VERSION "2021.24.4"

NS_ :

BS_:

BU_: VEH CH Receiver X

BA_DEF_ BO_ "GenMsgSendType" ENUM "Cyclic";
BA_DEF_ BO_ "GenMsgCycleTime" INT 0 10000;

BO_ 1317 PMF_alertLog: 8 Vector__XXX
 SG_ PMF_a011_vrefIrrational m11 : 63|1@1+ (1,0) [0|0] "" Vector__XXX
 SG_ PMF_a036_in1HzCLK m36 : 63|1@1+ (1,0) [0|0] "" Vector__XXX
 SG_ PMF_a011_currentReadingIrrationa m11 : 62|1@1+ (1,0) [0|0] "" Vector__XXX
 SG_ PMF_a036_in10HzCLK m36 : 62|1@1+ (1,0) [0|0] "" Vector__XXX
 SG_ PMF_a011_rateOfChangeIrrational m11 : 61|1@1+ (1,0) [0|0] "" Vector__XXX
 SG_ PMF_a036_in100HzCLK m36 : 61|1@1+ (1,0) [0|0] "" Vector__XXX
 SG_ PMF_a011_sampleFreeze m11 : 60|1@1+ (1,0) [0|0] "" Vector__XXX
 SG_ PMF_a036_in1kHzCLK m36 : 60|1@1+ (1,0) [0|0] "" Vector__XXX
 SG_ PMF_a095_fwdErrCounter m95 : 60|4@1+ (1,0) [0|0] "" Vector__XXX
 SG_ PMF_a011_badPhaseBsample m11 : 59|1@1+ (1,0) [0|0] "" Vector__XXX
 SG_ PMF_a036_in1kHzSWI m36 : 59|1@1+ (1,0) [0|0] "" Vector__XXX
 SG_ PMF_a011_badPhaseAsample m11 : 58|1@1+ (1,0) [0|0] "" Vector__XXX
 SG_ PMF_a036_inRxHWI m36 : 58|1@1+ (1,0) [0|0] "" Vector__XXX
 SG_ PMF_a036_inTxHWI m36 : 57|1@1+ (1,0) [0|0] "" Vector__XXX
 SG_ PMF_a036_inTxISR m36 : 56|1@1+ (1,0) [0|0] "" Vector__XXX
 SG_ PMF_a095_wwdErrCounter m95 : 56|4@1+ (1,0) [0|0] "" Vector__XXX
 SG_ PMF_a055_diElecAngleMismatchWarn m55 : 55|1@1+ (1,0) [0|0] "" Vector__XXX
 SG_ PMF_a055_diMIA m55 : 54|1@1+ (1,0) [0|0] "" Vector__XXX
 SG_ PMF_a055_claMIA m55 : 53|1@1+ (1,0) [0|0] "" Vector__XXX
 SG_ PMF_a036_ovfStackId m36 : 52|4@1+ (1,0) [0|0] "" Vector__XXX
 SG_ PMF_a055_diSpeedMismatch m55 : 52|1@1+ (1,0) [0|0] "" Vector__XXX
 SG_ PMF_a094_safetyICstate m94 : 52|3@1+ (1,0) [0|0] "" Vector__XXX
 SG_ PMF_a055_diElecAngleMismatch m55 : 51|1@1+ (1,0) [0|0] "" Vector__XXX
 SG_ PMF_a011_currentVref m11 : 50|8@1+ (0.04,0) [0|0] "" Vector__XXX
 SG_ PMF_a055_phaseOutOfSpec m55 : 50|1@1+ (1,0) [0|0] "" Vector__XXX
 SG_ PMF_a055_noCarrier m55 : 49|1@1+ (1,0) [0|0] "" Vector__XXX
 SG_ PMF_a000_alertDataW2 m0 : 48|16@1+ (1,0) [0|0] "" Vector__XXX
 SG_ PMF_a001_w2 m1 : 48|16@1+ (1,0) [0|0] "" Vector__XXX
 SG_ PMF_a002_torqueAccelWindow m2 : 48|13@1- (2,0) [0|0] "" Vector__XXX
 SG_ PMF_a004_torqueDecelWindow m4 : 48|13@1- (2,0) [0|0] "" Vector__XXX
 SG_ PMF_a008_crc_msw m8 : 48|16@1+ (1,0) [0|0] "" Vector__XXX
 SG_ PMF_a012_badValue2 m12 : 48|16@1+ (1,0) [0|0] "" Vector__XXX
 SG_ PMF_a013_errorType m13 : 48|3@1+ (1,0) [0|0] "" Vector__XXX
 SG_ PMF_a018_w2 m18 : 48|16@1+ (1,0) [0|0] "" Vector__XXX
 SG_ PMF_a027_w2 m27 : 48|16@1+ (1,0) [0|0] "" Vector__XXX
 SG_ PMF_a028_pedalPos m28 : 48|8@1+ (0.4,0) [0|0] "" Vector__XXX
 SG_ PMF_a031_stackSize m31 : 48|14@1+ (1,0) [0|0] "" Vector__XXX
 SG_ PMF_a032_w2 m32 : 48|16@1+ (1,0) [0|0] "" Vector__XXX
 SG_ PMF_a034_motorRPM m34 : 48|16@1- (1,0) [0|0] "" Vector__XXX
 SG_ PMF_a055_notReady m55 : 48|1@1+ (1,0) [0|0] "" Vector__XXX
 SG_ PMF_a056_errorType m56 : 48|3@1+ (1,0) [0|0] "" Vector__XXX
 SG_ PMF_a057_badValue2 m57 : 48|16@1+ (1,0) [0|0] "" Vector__XXX
 SG_ PMF_a062_errorType m62 : 48|4@1+ (1,0) [0|0] "" Vector__XXX
 SG_ PMF_a094_fwdErrCounter m94 : 48|4@1+ (1,0) [0|0] "" Vector__XXX
 SG_ PMF_a096_safetyICstate m96 : 48|3@1+ (1,0) [0|0] "" Vector__XXX
 SG_ PMF_a036_timeSinceIdle m36 : 46|6@1+ (0.16,0) [0|0] "" Vector__XXX
 SG_ PMF_a096_armingConditionsMet m96 : 46|1@1+ (1,0) [0|0] "" Vector__XXX
 SG_ PMF_a034_torqueType m34 : 45|2@1+ (1,0) [0|0] "" Vector__XXX
 SG_ PMF_a010_DI_autonomyHealth m10 : 44|1@1+ (1,0) [0|0] "" Vector__XXX
 SG_ PMF_a094_wwdErrCounter m94 : 44|4@1+ (1,0) [0|0] "" Vector__XXX
 SG_ PMF_a010_DI_brakeCommand m10 : 43|1@1+ (1,0) [0|0] "" Vector__XXX
 SG_ PMF_a094_spiParityErr m94 : 43|1@1+ (1,0) [0|0] "" Vector__XXX
 SG_ PMF_a095_motorRPM m95 : 43|12@1- (10,0) [0|0] "" Vector__XXX
 SG_ PMF_a010_DI_vehicleEstimates m10 : 42|1@1+ (1,0) [0|0] "" Vector__XXX
 SG_ PMF_a011_IbDelta m11 : 42|8@1- (24.0384,0) [0|0] "" Vector__XXX
 SG_ PMF_a026_xdcErrorArg1 m26 : 42|22@1- (1,0) [0|0] "" Vector__XXX
 SG_ PMF_a094_spiOverrun m94 : 42|1@1+ (1,0) [0|0] "" Vector__XXX
 SG_ PMF_a010_vdcRight m10 : 41|1@1+ (1,0) [0|0] "" Vector__XXX
 SG_ PMF_a094_tracker2UV m94 : 41|1@1+ (1,0) [0|0] "" Vector__XXX
 SG_ PMF_a010_vdcLeft m10 : 40|1@1+ (1,0) [0|0] "" Vector__XXX
 SG_ PMF_a033_DSADC_Ib m33 : 40|16@1- (0.0939,0) [0|0] "" Vector__XXX
 SG_ PMF_a036_timeSince1kHzSWI m36 : 40|6@1+ (32,0) [0|0] "" Vector__XXX
 SG_ PMF_a040_PM_locState m40 : 40|1@1+ (1,0) [0|0] "" Vector__XXX
 SG_ PMF_a055_commonGain m55 : 40|8@1+ (0.02,0) [0|0] "" Vector__XXX
 SG_ PMF_a094_tracker1UV m94 : 40|1@1+ (1,0) [0|0] "" Vector__XXX
 SG_ PMF_a095_safetyICstate m95 : 40|3@1+ (1,0) [0|0] "" Vector__XXX
 SG_ PMF_a096_fwdErrCounterMax m96 : 40|6@1+ (1,0) [0|0] "" Vector__XXX
 SG_ PMF_a010_DI_chassisControl2 m10 : 39|1@1+ (1,0) [0|0] "" Vector__XXX
 SG_ PMF_a094_voltRefUV m94 : 39|1@1+ (1,0) [0|0] "" Vector__XXX
 SG_ PMF_a010_DI_chassisControl m10 : 38|1@1+ (1,0) [0|0] "" Vector__XXX
 SG_ PMF_a094_commLdoUV m94 : 38|1@1+ (1,0) [0|0] "" Vector__XXX
 SG_ PMF_a095_biasCurrentTooHigh m95 : 38|1@1+ (1,0) [0|0] "" Vector__XXX
 SG_ PMF_a010_DI_systemStatus m10 : 37|1@1+ (1,0) [0|0] "" Vector__XXX
 SG_ PMF_a094_preRegulatorUV m94 : 37|1@1+ (1,0) [0|0] "" Vector__XXX
 SG_ PMF_a095_biasCurrentTooLow m95 : 37|1@1+ (1,0) [0|0] "" Vector__XXX
 SG_ PMF_a010_DI_speed m10 : 36|1@1+ (1,0) [0|0] "" Vector__XXX
 SG_ PMF_a094_commLdoOT m94 : 36|1@1+ (1,0) [0|0] "" Vector__XXX
 SG_ PMF_a095_bandgapComparatorOV m95 : 36|1@1+ (1,0) [0|0] "" Vector__XXX
 SG_ PMF_a010_DI_locStatus m10 : 35|1@1+ (1,0) [0|0] "" Vector__XXX
 SG_ PMF_a094_tracker2OV m94 : 35|1@1+ (1,0) [0|0] "" Vector__XXX
 SG_ PMF_a095_bandgapComparatorUV m95 : 35|1@1+ (1,0) [0|0] "" Vector__XXX
 SG_ PMF_a010_DI_slaveCommand m10 : 34|1@1+ (1,0) [0|0] "" Vector__XXX
 SG_ PMF_a031_stackUsedPrev m31 : 34|14@1+ (1,0) [0|0] "" Vector__XXX
 SG_ PMF_a036_timeSince1kHzCLK m36 : 34|6@1+ (32,0) [0|0] "" Vector__XXX
 SG_ PMF_a094_tracker1OV m94 : 34|1@1+ (1,0) [0|0] "" Vector__XXX
 SG_ PMF_a095_supplyVoltOV m95 : 34|1@1+ (1,0) [0|0] "" Vector__XXX
 SG_ PMF_a010_DI_torque m10 : 33|1@1+ (1,0) [0|0] "" Vector__XXX
 SG_ PMF_a011_Ib m11 : 33|9@1- (12.0192,0) [0|0] "" Vector__XXX
 SG_ PMF_a094_commLdoOV m94 : 33|1@1+ (1,0) [0|0] "" Vector__XXX
 SG_ PMF_a095_coreUV m95 : 33|1@1+ (1,0) [0|0] "" Vector__XXX
 SG_ PMF_a000_alertDataW1 m0 : 32|16@1+ (1,0) [0|0] "" Vector__XXX
 SG_ PMF_a001_w1 m1 : 32|16@1+ (1,0) [0|0] "" Vector__XXX
 SG_ PMF_a002_torqueAccelAverage m2 : 32|13@1- (2,0) [0|0] "" Vector__XXX
 SG_ PMF_a003_zeroPointPedal m3 : 32|8@1+ (0.4,0) [0|0] "" Vector__XXX
 SG_ PMF_a004_torqueDecelAverage m4 : 32|13@1- (2,0) [0|0] "" Vector__XXX
 SG_ PMF_a005_iDQmagnitude m5 : 32|16@1- (0.0939,0) [0|0] "" Vector__XXX
 SG_ PMF_a008_crc_lsw m8 : 32|16@1+ (1,0) [0|0] "" Vector__XXX
 SG_ PMF_a010_DI_status m10 : 32|1@1+ (1,0) [0|0] "" Vector__XXX
 SG_ PMF_a012_badValue1 m12 : 32|16@1+ (1,0) [0|0] "" Vector__XXX
 SG_ PMF_a013_canID m13 : 32|16@1+ (1,0) [0|0] "" Vector__XXX
 SG_ PMF_a018_w1 m18 : 32|16@1+ (1,0) [0|0] "" Vector__XXX
 SG_ PMF_a019_statorTslope1 m19 : 32|16@1- (0.1,0) [0|0] "" Vector__XXX
 SG_ PMF_a026_xdcErrorIdMSW m26 : 32|10@1+ (1,0) [0|0] "" Vector__XXX
 SG_ PMF_a027_w1 m27 : 32|16@1+ (1,0) [0|0] "" Vector__XXX
 SG_ PMF_a028_torqueCommandFwd m28 : 32|13@1- (2,0) [0|0] "" Vector__XXX
 SG_ PMF_a032_w1 m32 : 32|16@1+ (1,0) [0|0] "" Vector__XXX
 SG_ PMF_a034_parameterPM m34 : 32|13@1- (0.25,0) [0|0] "" Vector__XXX
 SG_ PMF_a055_phaseAngle m55 : 32|8@1+ (0.00308,0) [0|0] "" Vector__XXX
 SG_ PMF_a056_canID m56 : 32|16@1+ (1,0) [0|0] "" Vector__XXX
 SG_ PMF_a057_badValue1 m57 : 32|16@1+ (1,0) [0|0] "" Vector__XXX
 SG_ PMF_a064_pmCrsState m64 : 32|3@1+ (1,0) [0|0] "" Vector__XXX
 SG_ PMF_a094_tracker2Short m94 : 32|1@1+ (1,0) [0|0] "" Vector__XXX
 SG_ PMF_a095_standbyLdoUV m95 : 32|1@1+ (1,0) [0|0] "" Vector__XXX
 SG_ PMF_a096_fwdNumKicks m96 : 32|6@1+ (1,0) [0|0] "" Vector__XXX
 SG_ PMF_a026_immStackOvf m26 : 31|1@1+ (1,0) [0|0] "" Vector__XXX
 SG_ PMF_a094_tracker1Short m94 : 31|1@1+ (1,0) [0|0] "" Vector__XXX
 SG_ PMF_a095_ucLdoUV m95 : 31|1@1+ (1,0) [0|0] "" Vector__XXX
 SG_ PMF_a025_possibleSafetyICReset m25 : 30|1@1+ (1,0) [0|0] "" Vector__XXX
 SG_ PMF_a026_eepStackOvf m26 : 30|1@1+ (1,0) [0|0] "" Vector__XXX
 SG_ PMF_a094_voltRefShort m94 : 30|1@1+ (1,0) [0|0] "" Vector__XXX
 SG_ PMF_a095_voltRefOV m95 : 30|1@1+ (1,0) [0|0] "" Vector__XXX
 SG_ PMF_a025_ovfNmi m25 : 29|1@1+ (1,0) [0|0] "" Vector__XXX
 SG_ PMF_a026_idleStackOvf m26 : 29|1@1+ (1,0) [0|0] "" Vector__XXX
 SG_ PMF_a094_commLdoShort m94 : 29|1@1+ (1,0) [0|0] "" Vector__XXX
 SG_ PMF_a095_coreOV m95 : 29|1@1+ (1,0) [0|0] "" Vector__XXX
 SG_ PMF_a012_errorType m12 : 28|3@1+ (1,0) [0|0] "" Vector__XXX
 SG_ PMF_a025_rlNmi m25 : 28|1@1+ (1,0) [0|0] "" Vector__XXX
 SG_ PMF_a026_controlStackOvf m26 : 28|1@1+ (1,0) [0|0] "" Vector__XXX
 SG_ PMF_a036_timeSince100HzTxSWI m36 : 28|6@1+ (0.32,0) [0|0] "" Vector__XXX
 SG_ PMF_a057_errorType m57 : 28|3@1+ (1,0) [0|0] "" Vector__XXX
 SG_ PMF_a094_refVoltOverLoad m94 : 28|1@1+ (1,0) [0|0] "" Vector__XXX
 SG_ PMF_a095_standbyLdoOV m95 : 28|1@1+ (1,0) [0|0] "" Vector__XXX
 SG_ PMF_a025_sysDbgNmi m25 : 27|1@1+ (1,0) [0|0] "" Vector__XXX
 SG_ PMF_a026_systemStackOvf m26 : 27|1@1+ (1,0) [0|0] "" Vector__XXX
 SG_ PMF_a064_diCrsState m64 : 27|3@1+ (1,0) [0|0] "" Vector__XXX
 SG_ PMF_a094_commLdoOTWrn m94 : 27|1@1+ (1,0) [0|0] "" Vector__XXX
 SG_ PMF_a095_ucLdoOV m95 : 27|1@1+ (1,0) [0|0] "" Vector__XXX
 SG_ PMF_a025_pieVectErrorNmi m25 : 26|1@1+ (1,0) [0|0] "" Vector__XXX
 SG_ PMF_a026_switchingActive m26 : 26|1@1+ (1,0) [0|0] "" Vector__XXX
 SG_ PMF_a094_standbyLdoOverLoad m94 : 26|1@1+ (1,0) [0|0] "" Vector__XXX
 SG_ PMF_a095_preRegulatorOV m95 : 26|1@1+ (1,0) [0|0] "" Vector__XXX
 SG_ PMF_a011_IaDelta m11 : 25|8@1- (24.0384,0) [0|0] "" Vector__XXX
 SG_ PMF_a025_cpu2signMismatchNmi m25 : 25|1@1+ (1,0) [0|0] "" Vector__XXX
 SG_ PMF_a064_UI_stoppingMode m64 : 25|2@1+ (1,0) [0|0] "" Vector__XXX
 SG_ PMF_a094_ucLdoOTWrn m94 : 25|1@1+ (1,0) [0|0] "" Vector__XXX
 SG_ PMF_a095_coreVoltShort m95 : 25|1@1+ (1,0) [0|0] "" Vector__XXX
 SG_ PMF_a003_pedalPos m3 : 24|8@1+ (0.4,0) [0|0] "" Vector__XXX
 SG_ PMF_a025_cpu1signMismatchNmi m25 : 24|1@1+ (1,0) [0|0] "" Vector__XXX
 SG_ PMF_a033_DSADC_Ia m33 : 24|16@1- (0.0939,0) [0|0] "" Vector__XXX
 SG_ PMF_a039_messageId m39 : 24|16@1+ (1,0) [0|0] "" Vector__XXX
 SG_ PMF_a040_messageId m40 : 24|16@1+ (1,0) [0|0] "" Vector__XXX
 SG_ PMF_a061_pmIpcVersion m61 : 24|8@1+ (1,0) [0|0] "" Vector__XXX
 SG_ PMF_a064_shortDetectedByDI m64 : 24|1@1+ (1,0) [0|0] "" Vector__XXX
 SG_ PMF_a094_preRegulatorOTWrn m94 : 24|1@1+ (1,0) [0|0] "" Vector__XXX
 SG_ PMF_a095_standbyLdoShort m95 : 24|1@1+ (1,0) [0|0] "" Vector__XXX
 SG_ PMF_a096_wwdErrCounterMax m96 : 24|6@1+ (1,0) [0|0] "" Vector__XXX
 SG_ PMF_a025_flashUncErrorNmi m25 : 23|1@1+ (1,0) [0|0] "" Vector__XXX
 SG_ PMF_a094_lockUnlockErr m94 : 23|1@1+ (1,0) [0|0] "" Vector__XXX
 SG_ PMF_a095_ucLdoShort m95 : 23|1@1+ (1,0) [0|0] "" Vector__XXX
 SG_ PMF_a025_ramUncErrorNmi m25 : 22|1@1+ (1,0) [0|0] "" Vector__XXX
 SG_ PMF_a026_isrCount1kHz m26 : 22|4@1+ (1,0) [0|0] "" Vector__XXX
 SG_ PMF_a036_timeSinceRxHWI m36 : 22|6@1+ (64,0) [0|0] "" Vector__XXX
 SG_ PMF_a042_gearControl m42 : 22|1@1+ (1,0) [0|0] "" Vector__XXX
 SG_ PMF_a094_durationErr m94 : 22|1@1+ (1,0) [0|0] "" Vector__XXX
 SG_ PMF_a095_preRegulatorVoltShort m95 : 22|1@1+ (1,0) [0|0] "" Vector__XXX
 SG_ PMF_a025_clockFailNmi m25 : 21|1@1+ (1,0) [0|0] "" Vector__XXX
 SG_ PMF_a094_addrErr m94 : 21|1@1+ (1,0) [0|0] "" Vector__XXX
 SG_ PMF_a095_monitoringOT m95 : 21|1@1+ (1,0) [0|0] "" Vector__XXX
 SG_ PMF_a025_watchdog m25 : 20|1@1+ (1,0) [0|0] "" Vector__XXX
 SG_ PMF_a031_stackUsed m31 : 20|14@1+ (1,0) [0|0] "" Vector__XXX
 SG_ PMF_a033_failReason m33 : 20|3@1+ (1,0) [0|0] "" Vector__XXX
 SG_ PMF_a042_expectedPerformanceCfg m42 : 20|2@1+ (1,0) [0|0] "" Vector__XXX
 SG_ PMF_a053_sensors m53 : 20|1@1+ (1,0) [0|0] "" Vector__XXX
 SG_ PMF_a054_uiTPMSRCPSetting m54 : 20|1@1+ (1,0) [0|0] "" Vector__XXX
 SG_ PMF_a064_torqueCmdState m64 : 20|4@1+ (1,0) [0|0] "" Vector__XXX
 SG_ PMF_a094_lengthErr m94 : 20|1@1+ (1,0) [0|0] "" Vector__XXX
 SG_ PMF_a095_ucLdoOT m95 : 20|1@1+ (1,0) [0|0] "" Vector__XXX
 SG_ PMF_a017_EPBR_autonomyHealth m17 : 19|1@1+ (1,0) [0|0] "" Vector__XXX
 SG_ PMF_a025_nmiWatchdog m25 : 19|1@1+ (1,0) [0|0] "" Vector__XXX
 SG_ PMF_a053_restraintStatus m53 : 19|1@1+ (1,0) [0|0] "" Vector__XXX
 SG_ PMF_a054_uiTrackModeSettings m54 : 19|1@1+ (1,0) [0|0] "" Vector__XXX
 SG_ PMF_a094_parityErr m94 : 19|1@1+ (1,0) [0|0] "" Vector__XXX
 SG_ PMF_a095_preRegulatorOT m95 : 19|1@1+ (1,0) [0|0] "" Vector__XXX
 SG_ PMF_a002_torqueMeasured m2 : 18|13@1- (2,0) [0|0] "" Vector__XXX
 SG_ PMF_a004_torqueMeasured m4 : 18|13@1- (2,0) [0|0] "" Vector__XXX
 SG_ PMF_a005_torqueMeasured m5 : 18|13@1- (2,0) [0|0] "" Vector__XXX
 SG_ PMF_a017_EPBL_autonomyHealth m17 : 18|1@1+ (1,0) [0|0] "" Vector__XXX
 SG_ PMF_a025_hwBist m25 : 18|1@1+ (1,0) [0|0] "" Vector__XXX
 SG_ PMF_a042_GTW_drivetrainType m42 : 18|2@1+ (1,0) [0|0] "" Vector__XXX
 SG_ PMF_a053_vcleftSwitchStatus m53 : 18|1@1+ (1,0) [0|0] "" Vector__XXX
 SG_ PMF_a054_uiCruiseControl m54 : 18|1@1+ (1,0) [0|0] "" Vector__XXX
 SG_ PMF_a094_noOpFlag m94 : 18|1@1+ (1,0) [0|0] "" Vector__XXX
 SG_ PMF_a095_errMissStsFlag m95 : 18|1@1+ (1,0) [0|0] "" Vector__XXX
 SG_ PMF_a002_torqueWindow m2 : 17|1@1+ (1,0) [0|0] "" Vector__XXX
 SG_ PMF_a004_torqueWindow m4 : 17|1@1+ (1,0) [0|0] "" Vector__XXX
 SG_ PMF_a017_EPBR_status m17 : 17|1@1+ (1,0) [0|0] "" Vector__XXX
 SG_ PMF_a025_hibernate m25 : 17|1@1+ (1,0) [0|0] "" Vector__XXX
 SG_ PMF_a026_isrCount20kHz m26 : 17|5@1+ (1,0) [0|0] "" Vector__XXX
 SG_ PMF_a039_DIS_torque m39 : 17|1@1+ (1,0) [0|0] "" Vector__XXX
 SG_ PMF_a042_GTW_time m42 : 17|1@1+ (1,0) [0|0] "" Vector__XXX
 SG_ PMF_a053_coolant m53 : 17|1@1+ (1,0) [0|0] "" Vector__XXX
 SG_ PMF_a054_uiChassisControl m54 : 17|1@1+ (1,0) [0|0] "" Vector__XXX
 SG_ PMF_a094_trFailFlag m94 : 17|1@1+ (1,0) [0|0] "" Vector__XXX
 SG_ PMF_a095_fwdErrIntFlag m95 : 17|1@1+ (1,0) [0|0] "" Vector__XXX
 SG_ PMF_a000_alertDataW0 m0 : 16|16@1+ (1,0) [0|0] "" Vector__XXX
 SG_ PMF_a001_w0 m1 : 16|16@1+ (1,0) [0|0] "" Vector__XXX
 SG_ PMF_a002_torqueAverage m2 : 16|1@1+ (1,0) [0|0] "" Vector__XXX
 SG_ PMF_a003_reverseGear m3 : 16|1@1+ (1,0) [0|0] "" Vector__XXX
 SG_ PMF_a004_torqueAverage m4 : 16|1@1+ (1,0) [0|0] "" Vector__XXX
 SG_ PMF_a005_torqueReason m5 : 16|2@1+ (1,0) [0|0] "" Vector__XXX
 SG_ PMF_a008_memoryErrorTypeBits m8 : 16|16@1+ (1,0) [0|0] "" Vector__XXX
 SG_ PMF_a010_messageId m10 : 16|16@1+ (1,0) [0|0] "" Vector__XXX
 SG_ PMF_a011_Ia m11 : 16|9@1- (12.0192,0) [0|0] "" Vector__XXX
 SG_ PMF_a012_canID m12 : 16|12@1+ (1,0) [0|0] "" Vector__XXX
 SG_ PMF_a013_mailboxID m13 : 16|16@1+ (1,0) [0|0] "" Vector__XXX
 SG_ PMF_a017_EPBL_status m17 : 16|1@1+ (1,0) [0|0] "" Vector__XXX
 SG_ PMF_a018_w0 m18 : 16|16@1+ (1,0) [0|0] "" Vector__XXX
 SG_ PMF_a019_statorTemp1 m19 : 16|16@1- (0.1,0) [0|0] "" Vector__XXX
 SG_ PMF_a025_sccReset m25 : 16|1@1+ (1,0) [0|0] "" Vector__XXX
 SG_ PMF_a026_reason m26 : 16|1@1+ (1,0) [0|0] "" Vector__XXX
 SG_ PMF_a027_w0 m27 : 16|16@1+ (1,0) [0|0] "" Vector__XXX
 SG_ PMF_a028_torqueCommanded m28 : 16|13@1- (2,0) [0|0] "" Vector__XXX
 SG_ PMF_a031_taskID m31 : 16|4@1+ (1,0) [0|0] "" Vector__XXX
 SG_ PMF_a032_w0 m32 : 16|16@1+ (1,0) [0|0] "" Vector__XXX
 SG_ PMF_a033_state m33 : 16|4@1+ (1,0) [0|0] "" Vector__XXX
 SG_ PMF_a034_parameterDI m34 : 16|13@1- (0.25,0) [0|0] "" Vector__XXX
 SG_ PMF_a035_serviceDataId m35 : 16|16@1+ (1,0) [0|0] "" Vector__XXX
 SG_ PMF_a036_timeSinceTxHWI m36 : 16|6@1+ (64,0) [0|0] "" Vector__XXX
 SG_ PMF_a037_hvpFaults m37 : 16|1@1+ (1,0) [0|0] "" Vector__XXX
 SG_ PMF_a039_DIS_status m39 : 16|1@1+ (1,0) [0|0] "" Vector__XXX
 SG_ PMF_a040_PM_state m40 : 16|1@1+ (1,0) [0|0] "" Vector__XXX
 SG_ PMF_a042_GTW_carConfig m42 : 16|1@1+ (1,0) [0|0] "" Vector__XXX
 SG_ PMF_a053_LVPowerState m53 : 16|1@1+ (1,0) [0|0] "" Vector__XXX
 SG_ PMF_a054_uiPowertrainControl m54 : 16|1@1+ (1,0) [0|0] "" Vector__XXX
 SG_ PMF_a055_motorRPM m55 : 16|16@1- (1,0) [0|0] "" Vector__XXX
 SG_ PMF_a056_mailboxID m56 : 16|16@1+ (1,0) [0|0] "" Vector__XXX
 SG_ PMF_a057_canID m57 : 16|12@1+ (1,0) [0|0] "" Vector__XXX
 SG_ PMF_a061_diIpcVersion m61 : 16|8@1+ (1,0) [0|0] "" Vector__XXX
 SG_ PMF_a062_address m62 : 16|32@1+ (1,0) [0|0] "" Vector__XXX
 SG_ PMF_a064_interventionType m64 : 16|4@1+ (1,0) [0|0] "" Vector__XXX
 SG_ PMF_a092_pllClockSource m92 : 16|2@1+ (1,0) [0|0] "" Vector__XXX
 SG_ PMF_a094_cfgErrFlag m94 : 16|1@1+ (1,0) [0|0] "" Vector__XXX
 SG_ PMF_a095_wwdErrIntFlag m95 : 16|1@1+ (1,0) [0|0] "" Vector__XXX
 SG_ PMF_a096_wwdNumKicks m96 : 16|6@1+ (1,0) [0|0] "" Vector__XXX
 SG_ PMF_alertState : 15|1@1+ (1,0) [0|0] "" Vector__XXX
 SG_ PMF_alertID M : 0|7@1+ (1,0) [0|0] "" Vector__XXX

BO_ 1318 DIF_alertLog: 8 Vector__XXX
 SG_ DIF_a007_motorShort m7 : 63|1@1+ (1,0) [0|0] "" Vector__XXX
 SG_ DIF_a014_fbDeratedForRmsError m14 : 63|1@1+ (1,0) [0|0] "" Vector__XXX
 SG_ DIF_a240_secondaryStrategy3ps m240 : 63|1@1+ (1,0) [0|0] "" Vector__XXX
 SG_ DIF_a007_motorShift m7 : 62|1@1+ (1,0) [0|0] "" Vector__XXX
 SG_ DIF_a014_tcEnabled m14 : 62|1@1+ (1,0) [0|0] "" Vector__XXX
 SG_ DIF_a015_selfTestAborted m15 : 62|1@1+ (1,0) [0|0] "" Vector__XXX
 SG_ DIF_a156_incrementedGateDriveErr m156 : 62|1@1+ (1,0) [0|0] "" Vector__XXX
 SG_ DIF_a240_confNoCurrentDetected m240 : 62|1@1+ (1,0) [0|0] "" Vector__XXX
 SG_ DIF_a001_faultLine1Gpio_L m1 : 61|1@1+ (1,0) [0|0] "" Vector__XXX
 SG_ DIF_a002_faultLine1Gpio_L m2 : 61|1@1+ (1,0) [0|0] "" Vector__XXX
 SG_ DIF_a003_faultLine1Gpio_L m3 : 61|1@1+ (1,0) [0|0] "" Vector__XXX
 SG_ DIF_a038_reason m38 : 61|2@1+ (1,0) [0|0] "" Vector__XXX
 SG_ DIF_a153_reason m153 : 61|3@1+ (1,0) [0|0] "" Vector__XXX
 SG_ DIF_a001_faultLine1Gpio_H m1 : 60|1@1+ (1,0) [0|0] "" Vector__XXX
 SG_ DIF_a002_faultLine1Gpio_H m2 : 60|1@1+ (1,0) [0|0] "" Vector__XXX
 SG_ DIF_a003_faultLine1Gpio_H m3 : 60|1@1+ (1,0) [0|0] "" Vector__XXX
 SG_ DIF_a066_errorType m66 : 60|3@1+ (1,0) [0|0] "" Vector__XXX
 SG_ DIF_a123_varianceQ m123 : 60|4@1+ (20,0) [0|0] "" Vector__XXX
 SG_ DIF_a156_powerPolarityAlternate m156 : 60|2@1+ (1,0) [0|0] "" Vector__XXX
 SG_ DIF_a251_reason m251 : 60|3@1+ (1,0) [0|0] "" Vector__XXX
 SG_ DIF_a001_localReset_L m1 : 59|1@1+ (1,0) [0|0] "" Vector__XXX
 SG_ DIF_a002_localReset_L m2 : 59|1@1+ (1,0) [0|0] "" Vector__XXX
 SG_ DIF_a003_localReset_L m3 : 59|1@1+ (1,0) [0|0] "" Vector__XXX
 SG_ DIF_a001_remoteReset_L m1 : 58|1@1+ (1,0) [0|0] "" Vector__XXX
 SG_ DIF_a002_remoteReset_L m2 : 58|1@1+ (1,0) [0|0] "" Vector__XXX
 SG_ DIF_a003_remoteReset_L m3 : 58|1@1+ (1,0) [0|0] "" Vector__XXX
 SG_ DIF_a156_phaseCPolarityAlternate m156 : 58|2@1+ (1,0) [0|0] "" Vector__XXX
 SG_ DIF_a001_localCommError_L m1 : 57|1@1+ (1,0) [0|0] "" Vector__XXX
 SG_ DIF_a002_localCommError_L m2 : 57|1@1+ (1,0) [0|0] "" Vector__XXX
 SG_ DIF_a003_localCommError_L m3 : 57|1@1+ (1,0) [0|0] "" Vector__XXX
 SG_ DIF_a016_triggerEvent m16 : 57|5@1+ (1,0) [0|0] "" Vector__XXX
 SG_ DIF_a024_rotorAngle m24 : 57|7@1- (3,0) [0|0] "" Vector__XXX
 SG_ DIF_a240_secondaryDutyCycle m240 : 57|5@1+ (1,0) [0|0] "" Vector__XXX
 SG_ DIF_a001_remoteCommError_L m1 : 56|1@1+ (1,0) [0|0] "" Vector__XXX
 SG_ DIF_a002_remoteCommError_L m2 : 56|1@1+ (1,0) [0|0] "" Vector__XXX
 SG_ DIF_a003_remoteCommError_L m3 : 56|1@1+ (1,0) [0|0] "" Vector__XXX
 SG_ DIF_a011_codeBranch m11 : 56|4@1+ (1,0) [0|0] "" Vector__XXX
 SG_ DIF_a015_pyroSenseVAvg m15 : 56|6@1+ (0.1,0) [0|0] "" Vector__XXX
 SG_ DIF_a016_safetyICfaultLine m16 : 56|1@1+ (1,0) [0|0] "" Vector__XXX
 SG_ DIF_a099_cpuUsage10ms m99 : 56|8@1+ (1,0) [0|0] "" Vector__XXX
 SG_ DIF_a123_varianceD m123 : 56|4@1+ (20,0) [0|0] "" Vector__XXX
 SG_ DIF_a153_oilPumpAlert m153 : 56|5@1+ (1,0) [0|0] "" Vector__XXX
 SG_ DIF_a156_phaseBPolarityAlternate m156 : 56|2@1+ (1,0) [0|0] "" Vector__XXX
 SG_ DIF_a251_leadAngle m251 : 56|4@1+ (1.875,0) [0|0] "" Vector__XXX
 SG_ DIF_a001_localReset_H m1 : 55|1@1+ (1,0) [0|0] "" Vector__XXX
 SG_ DIF_a002_localReset_H m2 : 55|1@1+ (1,0) [0|0] "" Vector__XXX
 SG_ DIF_a003_localReset_H m3 : 55|1@1+ (1,0) [0|0] "" Vector__XXX
 SG_ DIF_a148_timeAbove104degC m148 : 55|9@1+ (5,0) [0|0] "" Vector__XXX
 SG_ DIF_a154_claMIA m154 : 55|1@1+ (1,0) [0|0] "" Vector__XXX
 SG_ DIF_a001_remoteReset_H m1 : 54|1@1+ (1,0) [0|0] "" Vector__XXX
 SG_ DIF_a002_remoteReset_H m2 : 54|1@1+ (1,0) [0|0] "" Vector__XXX
 SG_ DIF_a003_remoteReset_H m3 : 54|1@1+ (1,0) [0|0] "" Vector__XXX
 SG_ DIF_a007_iqFdbStdDeviation m7 : 54|8@1+ (4,0) [0|0] "" Vector__XXX
 SG_ DIF_a154_trackerIrrational m154 : 54|1@1+ (1,0) [0|0] "" Vector__XXX
 SG_ DIF_a156_phaseAPolarityAlternate m156 : 54|2@1+ (1,0) [0|0] "" Vector__XXX
 SG_ DIF_a001_localCommError_H m1 : 53|1@1+ (1,0) [0|0] "" Vector__XXX
 SG_ DIF_a002_localCommError_H m2 : 53|1@1+ (1,0) [0|0] "" Vector__XXX
 SG_ DIF_a003_localCommError_H m3 : 53|1@1+ (1,0) [0|0] "" Vector__XXX
 SG_ DIF_a153_state m153 : 53|3@1+ (1,0) [0|0] "" Vector__XXX
 SG_ DIF_a154_carrierOffset m154 : 53|1@1+ (1,0) [0|0] "" Vector__XXX
 SG_ DIF_a001_remoteCommError_H m1 : 52|1@1+ (1,0) [0|0] "" Vector__XXX
 SG_ DIF_a002_remoteCommError_H m2 : 52|1@1+ (1,0) [0|0] "" Vector__XXX
 SG_ DIF_a003_remoteCommError_H m3 : 52|1@1+ (1,0) [0|0] "" Vector__XXX
 SG_ DIF_a014_rmsTorqueError m14 : 52|10@1+ (1,0) [0|0] "" Vector__XXX
 SG_ DIF_a103_sensorTempEst m103 : 52|8@1- (1.2598425196850394,40.31496062992126) [0|0] "" Vector__XXX
 SG_ DIF_a134_wheelSpeedDiffReR m134 : 52|12@1- (0.0625,0) [0|0] "" Vector__XXX
 SG_ DIF_a154_errorTableInvalid m154 : 52|1@1+ (1,0) [0|0] "" Vector__XXX
 SG_ DIF_a240_primaryDutyCycle m240 : 52|5@1+ (1,0) [0|0] "" Vector__XXX
 SG_ DIF_a084_flashEccTestFail m84 : 51|1@1+ (1,0) [0|0] "" Vector__XXX
 SG_ DIF_a154_notReady m154 : 51|1@1+ (1,0) [0|0] "" Vector__XXX
 SG_ DIF_a240_secNoCurrentB m240 : 51|1@1+ (1,0) [0|0] "" Vector__XXX
 SG_ DIF_a069_fittedTorqueLimit m69 : 50|13@1- (0.25,0) [0|0] "" Vector__XXX
 SG_ DIF_a084_postAddressTestFail m84 : 50|1@1+ (1,0) [0|0] "" Vector__XXX
 SG_ DIF_a107_fpgaWarningActive m107 : 50|1@1+ (1,0) [0|0] "" Vector__XXX
 SG_ DIF_a154_noCarrier m154 : 50|1@1+ (1,0) [0|0] "" Vector__XXX
 SG_ DIF_a240_secNoCurrentA m240 : 50|1@1+ (1,0) [0|0] "" Vector__XXX
 SG_ DIF_a084_preAddressTestFail m84 : 49|1@1+ (1,0) [0|0] "" Vector__XXX
 SG_ DIF_a107_fpgaFaultActive m107 : 49|1@1+ (1,0) [0|0] "" Vector__XXX
 SG_ DIF_a149_pcbaID m149 : 49|1@1+ (1,0) [0|0] "" Vector__XXX
 SG_ DIF_a154_noPhaseLock m154 : 49|1@1+ (1,0) [0|0] "" Vector__XXX
 SG_ DIF_a240_primNoCurrentB m240 : 49|1@1+ (1,0) [0|0] "" Vector__XXX
 SG_ DIF_a000_alertDataW2 m0 : 48|16@1+ (1,0) [0|0] "" Vector__XXX
 SG_ DIF_a001_gateDriveErrCounter m1 : 48|4@1+ (1,0) [0|0] "" Vector__XXX
 SG_ DIF_a002_gateDriveErrCounter m2 : 48|4@1+ (1,0) [0|0] "" Vector__XXX
 SG_ DIF_a003_gateDriveErrCounter m3 : 48|4@1+ (1,0) [0|0] "" Vector__XXX
 SG_ DIF_a011_badDataExpected m11 : 48|8@1+ (1,0) [0|0] "" Vector__XXX
 SG_ DIF_a013_errorType m13 : 48|4@1+ (1,0) [0|0] "" Vector__XXX
 SG_ DIF_a015_pyroSenseVDiff m15 : 48|6@1+ (0.1,0) [0|0] "" Vector__XXX
 SG_ DIF_a025_motorSpeed m25 : 48|16@1- (1,0) [0|0] "" Vector__XXX
 SG_ DIF_a026_motorSpeed m26 : 48|16@1- (1,0) [0|0] "" Vector__XXX
 SG_ DIF_a027_motorSpeed m27 : 48|16@1- (1,0) [0|0] "" Vector__XXX
 SG_ DIF_a028_iArmsSpeed m28 : 48|16@1+ (1,0) [0|0] "" Vector__XXX
 SG_ DIF_a029_iBrmsSpeed m29 : 48|16@1+ (1,0) [0|0] "" Vector__XXX
 SG_ DIF_a030_iCrmsSpeed m30 : 48|16@1+ (1,0) [0|0] "" Vector__XXX
 SG_ DIF_a033_vRefIa m33 : 48|16@1- (0.001,0) [0|0] "" Vector__XXX
 SG_ DIF_a034_vRefIb m34 : 48|16@1- (0.001,0) [0|0] "" Vector__XXX
 SG_ DIF_a035_frequency m35 : 48|10@1+ (1,0) [0|0] "" Vector__XXX
 SG_ DIF_a038_iBat m38 : 48|13@1+ (0.5,0) [0|0] "" Vector__XXX
 SG_ DIF_a042_inletTempSlope m42 : 48|8@1- (0.5,0) [0|0] "" Vector__XXX
 SG_ DIF_a045_outletTempSlope m45 : 48|8@1- (0.5,0) [0|0] "" Vector__XXX
 SG_ DIF_a049_motorCurrent m49 : 48|11@1+ (1,0) [0|0] "" Vector__XXX
 SG_ DIF_a055_motorRPM m55 : 48|16@1- (1,0) [0|0] "" Vector__XXX
 SG_ DIF_a058_pcbTempSlope m58 : 48|8@1- (0.5,0) [0|0] "" Vector__XXX
 SG_ DIF_a066_canID m66 : 48|12@1+ (1,0) [0|0] "" Vector__XXX
 SG_ DIF_a074_motorSpeed2 m74 : 48|16@1- (1,0) [0|0] "" Vector__XXX
 SG_ DIF_a084_eccCheckFail m84 : 48|1@1+ (1,0) [0|0] "" Vector__XXX
 SG_ DIF_a093_errorType m93 : 48|1@1+ (1,0) [0|0] "" Vector__XXX
 SG_ DIF_a094_badValue2 m94 : 48|16@1+ (1,0) [0|0] "" Vector__XXX
 SG_ DIF_a099_cpuUsage1kHz m99 : 48|8@1+ (1,0) [0|0] "" Vector__XXX
 SG_ DIF_a107_fpgaMasterActive m107 : 48|1@1+ (1,0) [0|0] "" Vector__XXX
 SG_ DIF_a113_heatsink3Temp m113 : 48|16@1- (0.1,0) [0|0] "" Vector__XXX
 SG_ DIF_a121_badFlux m121 : 48|16@1+ (0.0001,0) [0|0] "" Vector__XXX
 SG_ DIF_a123_motorRPM m123 : 48|8@1- (150,0) [0|0] "" Vector__XXX
 SG_ DIF_a133_badValue2 m133 : 48|16@1- (0.1,0) [0|0] "" Vector__XXX
 SG_ DIF_a149_responseError m149 : 48|1@1+ (1,0) [0|0] "" Vector__XXX
 SG_ DIF_a150_energy m150 : 48|16@1+ (1,0) [0|0] "" Vector__XXX
 SG_ DIF_a153_lowPressPlausibility m153 : 48|5@1+ (3.3,0) [0|0] "" Vector__XXX
 SG_ DIF_a154_noCalibration m154 : 48|1@1+ (1,0) [0|0] "" Vector__XXX
 SG_ DIF_a160_energy m160 : 48|16@1+ (1,0) [0|0] "" Vector__XXX
 SG_ DIF_a240_primNoCurrentA m240 : 48|1@1+ (1,0) [0|0] "" Vector__XXX
 SG_ DIF_a246_eepromOffsetIb m246 : 48|6@1- (0.763,0) [0|0] "" Vector__XXX
 SG_ DIF_a247_torqueMotor m247 : 48|16@1- (1,0) [0|0] "" Vector__XXX
 SG_ DIF_a249_motorCurrent m249 : 48|11@1+ (1,0) [0|0] "" Vector__XXX
 SG_ DIF_a251_phaseCurrent m251 : 48|8@1+ (0.1,0) [0|0] "" Vector__XXX
 SG_ DIF_a001_deadtimeError_L m1 : 47|1@1+ (1,0) [0|0] "" Vector__XXX
 SG_ DIF_a002_deadtimeError_L m2 : 47|1@1+ (1,0) [0|0] "" Vector__XXX
 SG_ DIF_a003_deadtimeError_L m3 : 47|1@1+ (1,0) [0|0] "" Vector__XXX
 SG_ DIF_a149_motorFlowSNA m149 : 47|1@1+ (1,0) [0|0] "" Vector__XXX
 SG_ DIF_a240_secondaryTimeout m240 : 47|1@1+ (1,0) [0|0] "" Vector__XXX
 SG_ DIF_a001_spiError_L m1 : 46|1@1+ (1,0) [0|0] "" Vector__XXX
 SG_ DIF_a002_spiError_L m2 : 46|1@1+ (1,0) [0|0] "" Vector__XXX
 SG_ DIF_a003_spiError_L m3 : 46|1@1+ (1,0) [0|0] "" Vector__XXX
 SG_ DIF_a007_idFdbStdDeviation m7 : 46|8@1+ (4,0) [0|0] "" Vector__XXX
 SG_ DIF_a148_timeFrom90to104degC m148 : 46|9@1+ (30,0) [0|0] "" Vector__XXX
 SG_ DIF_a149_motorShorted m149 : 46|1@1+ (1,0) [0|0] "" Vector__XXX
 SG_ DIF_a240_primaryTimeout m240 : 46|1@1+ (1,0) [0|0] "" Vector__XXX
 SG_ DIF_a001_localRegError_L m1 : 45|1@1+ (1,0) [0|0] "" Vector__XXX
 SG_ DIF_a002_localRegError_L m2 : 45|1@1+ (1,0) [0|0] "" Vector__XXX
 SG_ DIF_a003_localRegError_L m3 : 45|1@1+ (1,0) [0|0] "" Vector__XXX
 SG_ DIF_a024_maxCurrMagSqrd m24 : 45|12@1+ (500,0) [0|0] "" Vector__XXX
 SG_ DIF_a055_torqueType m55 : 45|2@1+ (1,0) [0|0] "" Vector__XXX
 SG_ DIF_a103_ambientTemp m103 : 45|7@1- (1.5873015873015872,11.11111111111111) [0|0] "" Vector__XXX
 SG_ DIF_a149_motorOpenPhase m149 : 45|1@1+ (1,0) [0|0] "" Vector__XXX
 SG_ DIF_a001_overvoltVDD_L m1 : 44|1@1+ (1,0) [0|0] "" Vector__XXX
 SG_ DIF_a002_overvoltVDD_L m2 : 44|1@1+ (1,0) [0|0] "" Vector__XXX
 SG_ DIF_a003_overvoltVDD_L m3 : 44|1@1+ (1,0) [0|0] "" Vector__XXX
 SG_ DIF_a147_wearIsValid m147 : 44|1@1+ (1,0) [0|0] "" Vector__XXX
 SG_ DIF_a149_insufficientFlow m149 : 44|1@1+ (1,0) [0|0] "" Vector__XXX
 SG_ DIF_a001_undervoltVDD_L m1 : 43|1@1+ (1,0) [0|0] "" Vector__XXX
 SG_ DIF_a002_undervoltVDD_L m2 : 43|1@1+ (1,0) [0|0] "" Vector__XXX
 SG_ DIF_a003_undervoltVDD_L m3 : 43|1@1+ (1,0) [0|0] "" Vector__XXX
 SG_ DIF_a149_fluidTempSNA m149 : 43|1@1+ (1,0) [0|0] "" Vector__XXX
 SG_ DIF_a001_remoteRegError_L m1 : 42|1@1+ (1,0) [0|0] "" Vector__XXX
 SG_ DIF_a002_remoteRegError_L m2 : 42|1@1+ (1,0) [0|0] "" Vector__XXX
 SG_ DIF_a003_remoteRegError_L m3 : 42|1@1+ (1,0) [0|0] "" Vector__XXX
 SG_ DIF_a014_brakeMasterCylPress m14 : 42|10@1+ (0.25,-42.5) [0|0] "" Vector__XXX
 SG_ DIF_a162_currentOdometer m162 : 42|10@1+ (500,0) [0|0] "" Vector__XXX
 SG_ DIF_a001_asynchStop_L m1 : 41|1@1+ (1,0) [0|0] "" Vector__XXX
 SG_ DIF_a002_asynchStop_L m2 : 41|1@1+ (1,0) [0|0] "" Vector__XXX
 SG_ DIF_a003_asynchStop_L m3 : 41|1@1+ (1,0) [0|0] "" Vector__XXX
 SG_ DIF_a001_undervoltVCC_L m1 : 40|1@1+ (1,0) [0|0] "" Vector__XXX
 SG_ DIF_a002_undervoltVCC_L m2 : 40|1@1+ (1,0) [0|0] "" Vector__XXX
 SG_ DIF_a003_undervoltVCC_L m3 : 40|1@1+ (1,0) [0|0] "" Vector__XXX
 SG_ DIF_a011_badDataRead m11 : 40|8@1+ (1,0) [0|0] "" Vector__XXX
 SG_ DIF_a015_pyroSenseVN m15 : 40|6@1+ (0.1,0) [0|0] "" Vector__XXX
 SG_ DIF_a016_torqueMotor m16 : 40|16@1- (1,0) [0|0] "" Vector__XXX
 SG_ DIF_a061_otherTemp m61 : 40|16@1- (0.1,0) [0|0] "" Vector__XXX
 SG_ DIF_a065_mailboxID m65 : 40|16@1+ (1,0) [0|0] "" Vector__XXX
 SG_ DIF_a069_rotorMagnetTemp m69 : 40|10@1+ (0.25,-60) [0|0] "" Vector__XXX
 SG_ DIF_a096_word2 m96 : 40|16@1+ (1,0) [0|0] "" Vector__XXX
 SG_ DIF_a097_argument m97 : 40|16@1+ (1,0) [0|0] "" Vector__XXX
 SG_ DIF_a099_cpuUsage100Hz m99 : 40|8@1+ (1,0) [0|0] "" Vector__XXX
 SG_ DIF_a122_stackSize m122 : 40|16@1+ (1,0) [0|0] "" Vector__XXX
 SG_ DIF_a134_wheelSpeedDiffReL m134 : 40|12@1- (0.0625,0) [0|0] "" Vector__XXX
 SG_ DIF_a149_state m149 : 40|3@1+ (1,0) [0|0] "" Vector__XXX
 SG_ DIF_a150_elapsedMs m150 : 40|8@1+ (1,0) [0|0] "" Vector__XXX
 SG_ DIF_a152_expectedValue m152 : 40|8@1+ (1,0) [0|0] "" Vector__XXX
 SG_ DIF_a153_dcVoltage m153 : 40|8@1+ (0.3,0) [0|0] "" Vector__XXX
 SG_ DIF_a154_commonGain m154 : 40|8@1+ (0.02,0) [0|0] "" Vector__XXX
 SG_ DIF_a160_elapsedMs m160 : 40|8@1+ (1,0) [0|0] "" Vector__XXX
 SG_ DIF_a240_fuseB_I2t m240 : 40|6@1+ (8,0) [0|0] "" Vector__XXX
 SG_ DIF_a246_eepromOffsetIa m246 : 40|6@1- (0.763,0) [0|0] "" Vector__XXX
 SG_ DIF_a249_statorT m249 : 40|8@1+ (1,-40) [0|0] "" Vector__XXX
 SG_ DIF_a251_dcCurrent m251 : 40|8@1+ (0.1,0) [0|0] "" Vector__XXX
 SG_ DIF_a254_reason m254 : 40|2@1+ (1,0) [0|0] "" Vector__XXX
 SG_ DIF_a001_overvoltVH_L m1 : 39|1@1+ (1,0) [0|0] "" Vector__XXX
 SG_ DIF_a002_overvoltVH_L m2 : 39|1@1+ (1,0) [0|0] "" Vector__XXX
 SG_ DIF_a003_overvoltVH_L m3 : 39|1@1+ (1,0) [0|0] "" Vector__XXX
 SG_ DIF_a123_badCurrent m123 : 39|9@1- (10,0) [0|0] "" Vector__XXX
 SG_ DIF_a001_overvoltVL_L m1 : 38|1@1+ (1,0) [0|0] "" Vector__XXX
 SG_ DIF_a002_overvoltVL_L m2 : 38|1@1+ (1,0) [0|0] "" Vector__XXX
 SG_ DIF_a003_overvoltVL_L m3 : 38|1@1+ (1,0) [0|0] "" Vector__XXX
 SG_ DIF_a024_Ib m24 : 38|7@1- (22.5,0) [0|0] "" Vector__XXX
 SG_ DIF_a156_motorRPM m156 : 38|16@1- (1,0) [0|0] "" Vector__XXX
 SG_ DIF_a001_desat_L m1 : 37|1@1+ (1,0) [0|0] "" Vector__XXX
 SG_ DIF_a002_desat_L m2 : 37|1@1+ (1,0) [0|0] "" Vector__XXX
 SG_ DIF_a003_desat_L m3 : 37|1@1+ (1,0) [0|0] "" Vector__XXX
 SG_ DIF_a148_timeFrom50to90degC m148 : 37|9@1+ (30,0) [0|0] "" Vector__XXX
 SG_ DIF_a156_alertQueueOverrun m156 : 37|1@1+ (1,0) [0|0] "" Vector__XXX
 SG_ DIF_a001_sense_L m1 : 36|1@1+ (1,0) [0|0] "" Vector__XXX
 SG_ DIF_a002_sense_L m2 : 36|1@1+ (1,0) [0|0] "" Vector__XXX
 SG_ DIF_a003_sense_L m3 : 36|1@1+ (1,0) [0|0] "" Vector__XXX
 SG_ DIF_a042_heatsinkTemp m42 : 36|10@1+ (0.25,-60) [0|0] "" Vector__XXX
 SG_ DIF_a045_heatsinkTemp m45 : 36|10@1+ (0.25,-60) [0|0] "" Vector__XXX
 SG_ DIF_a058_heatsinkTemp m58 : 36|10@1+ (0.25,-60) [0|0] "" Vector__XXX
 SG_ DIF_a144_autonomyFeatureType m144 : 36|1@1+ (1,0) [0|0] "" Vector__XXX
 SG_ DIF_a001_undervoltVH_L m1 : 35|1@1+ (1,0) [0|0] "" Vector__XXX
 SG_ DIF_a002_undervoltVH_L m2 : 35|1@1+ (1,0) [0|0] "" Vector__XXX
 SG_ DIF_a003_undervoltVH_L m3 : 35|1@1+ (1,0) [0|0] "" Vector__XXX
 SG_ DIF_a103_rmsCurrent m103 : 35|10@1- (12.819960861056751,0) [0|0] "" Vector__XXX
 SG_ DIF_a144_chassisSubType m144 : 35|1@1+ (1,0) [0|0] "" Vector__XXX
 SG_ DIF_a156_safeStateRecommend m156 : 35|2@1+ (1,0) [0|0] "" Vector__XXX
 SG_ DIF_a001_undervoltVL_L m1 : 34|1@1+ (1,0) [0|0] "" Vector__XXX
 SG_ DIF_a002_undervoltVL_L m2 : 34|1@1+ (1,0) [0|0] "" Vector__XXX
 SG_ DIF_a003_undervoltVL_L m3 : 34|1@1+ (1,0) [0|0] "" Vector__XXX
 SG_ DIF_a144_powerLiftgateType m144 : 34|1@1+ (1,0) [0|0] "" Vector__XXX
 SG_ DIF_a147_accumulatedWear m147 : 34|10@1+ (0.005,0) [0|0] "" Vector__XXX
 SG_ DIF_a240_fuseA_I2t m240 : 34|6@1+ (8,0) [0|0] "" Vector__XXX
 SG_ DIF_a001_thermalShutdown_L m1 : 33|1@1+ (1,0) [0|0] "" Vector__XXX
 SG_ DIF_a002_thermalShutdown_L m2 : 33|1@1+ (1,0) [0|0] "" Vector__XXX
 SG_ DIF_a003_thermalShutdown_L m3 : 33|1@1+ (1,0) [0|0] "" Vector__XXX
 SG_ DIF_a136_busyError_AH m136 : 33|1@1+ (1,0) [0|0] "" Vector__XXX
 SG_ DIF_a144_dasHw m144 : 33|1@1+ (1,0) [0|0] "" Vector__XXX
 SG_ DIF_a156_result m156 : 33|2@1+ (1,0) [0|0] "" Vector__XXX
 SG_ DIF_a000_alertDataW1 m0 : 32|16@1+ (1,0) [0|0] "" Vector__XXX
 SG_ DIF_a001_thermalWarning_L m1 : 32|1@1+ (1,0) [0|0] "" Vector__XXX
 SG_ DIF_a002_thermalWarning_L m2 : 32|1@1+ (1,0) [0|0] "" Vector__XXX
 SG_ DIF_a003_thermalWarning_L m3 : 32|1@1+ (1,0) [0|0] "" Vector__XXX
 SG_ DIF_a007_offsetError m7 : 32|14@1- (0.00038349519697141,0) [0|0] "" Vector__XXX
 SG_ DIF_a010_wdtFlags m10 : 32|16@1+ (1,0) [0|0] "" Vector__XXX
 SG_ DIF_a011_badGateDriveIC m11 : 32|3@1+ (1,0) [0|0] "" Vector__XXX
 SG_ DIF_a014_torqueCommandFwd m14 : 32|10@1- (2,0) [0|0] "" Vector__XXX
 SG_ DIF_a015_pyroSenseV m15 : 32|6@1+ (0.1,0) [0|0] "" Vector__XXX
 SG_ DIF_a025_torqueMotor m25 : 32|13@1- (0.25,0) [0|0] "" Vector__XXX
 SG_ DIF_a026_torqueMotor m26 : 32|13@1- (0.25,0) [0|0] "" Vector__XXX
 SG_ DIF_a027_torqueMotor m27 : 32|13@1- (0.25,0) [0|0] "" Vector__XXX
 SG_ DIF_a028_iArmsTorque m28 : 32|16@1+ (0.25,0) [0|0] "" Vector__XXX
 SG_ DIF_a029_iBrmsTorque m29 : 32|16@1+ (0.25,0) [0|0] "" Vector__XXX
 SG_ DIF_a030_iCrmsTorque m30 : 32|16@1+ (0.25,0) [0|0] "" Vector__XXX
 SG_ DIF_a033_deltaIa m33 : 32|16@1- (1,0) [0|0] "" Vector__XXX
 SG_ DIF_a034_deltaIb m34 : 32|16@1- (1,0) [0|0] "" Vector__XXX
 SG_ DIF_a035_phaseCurrent m35 : 32|16@1+ (1,0) [0|0] "" Vector__XXX
 SG_ DIF_a036_busHighLimit m36 : 32|16@1+ (0.1,0) [0|0] "" Vector__XXX
 SG_ DIF_a037_busLowLimit m37 : 32|16@1+ (0.1,0) [0|0] "" Vector__XXX
 SG_ DIF_a038_vBat m38 : 32|13@1+ (0.2,0) [0|0] "" Vector__XXX
 SG_ DIF_a046_statorTemp2 m46 : 32|16@1- (0.1,0) [0|0] "" Vector__XXX
 SG_ DIF_a047_statorTslope1 m47 : 32|16@1- (0.1,0) [0|0] "" Vector__XXX
 SG_ DIF_a048_statorTslope2 m48 : 32|16@1- (0.1,0) [0|0] "" Vector__XXX
 SG_ DIF_a049_motorRPM m49 : 32|16@1+ (1,0) [0|0] "" Vector__XXX
 SG_ DIF_a050_statorTemp2 m50 : 32|16@1- (0.1,0) [0|0] "" Vector__XXX
 SG_ DIF_a054_heatsinkTemp m54 : 32|16@1- (0.1,0) [0|0] "" Vector__XXX
 SG_ DIF_a055_parameterPM m55 : 32|13@1- (0.25,0) [0|0] "" Vector__XXX
 SG_ DIF_a065_errorType m65 : 32|1@1+ (1,0) [0|0] "" Vector__XXX
 SG_ DIF_a066_badValue2 m66 : 32|16@1+ (1,0) [0|0] "" Vector__XXX
 SG_ DIF_a067_mailboxID m67 : 32|16@1+ (1,0) [0|0] "" Vector__XXX
 SG_ DIF_a069_rotorCoolingPower m69 : 32|8@1+ (20,0) [0|0] "" Vector__XXX
 SG_ DIF_a071_busVslope m71 : 32|16@1+ (0.1,0) [0|0] "" Vector__XXX
 SG_ DIF_a074_motorSpeed1 m74 : 32|16@1- (1,0) [0|0] "" Vector__XXX
 SG_ DIF_a075_absSpeed m75 : 32|16@1+ (1,0) [0|0] "" Vector__XXX
 SG_ DIF_a093_canID m93 : 32|16@1+ (1,0) [0|0] "" Vector__XXX
 SG_ DIF_a094_badValue1 m94 : 32|16@1+ (1,0) [0|0] "" Vector__XXX
 SG_ DIF_a095_canID m95 : 32|16@1+ (1,0) [0|0] "" Vector__XXX
 SG_ DIF_a098_fluxState m98 : 32|4@1+ (1,0) [0|0] "" Vector__XXX
 SG_ DIF_a099_cpuUsage10Hz m99 : 32|8@1+ (1,0) [0|0] "" Vector__XXX
 SG_ DIF_a107_fpgaBootVersion m107 : 32|16@1+ (1,0) [0|0] "" Vector__XXX
 SG_ DIF_a108_blockingAlert m108 : 32|8@1+ (1,0) [0|0] "" Vector__XXX
 SG_ DIF_a111_phBcalib m111 : 32|16@1+ (1,0) [0|0] "" Vector__XXX
 SG_ DIF_a113_heatsink2Temp m113 : 32|16@1- (0.1,0) [0|0] "" Vector__XXX
 SG_ DIF_a121_badCurrent m121 : 32|16@1- (0.1,0) [0|0] "" Vector__XXX
 SG_ DIF_a123_lossRequest m123 : 32|7@1+ (0.1,0) [0|0] "" Vector__XXX
 SG_ DIF_a128_reportedFPGAversion m128 : 32|16@1+ (1,0) [0|0] "" Vector__XXX
 SG_ DIF_a133_badValue1 m133 : 32|16@1- (0.1,0) [0|0] "" Vector__XXX
 SG_ DIF_a136_crcError_AH m136 : 32|1@1+ (1,0) [0|0] "" Vector__XXX
 SG_ DIF_a142_lashCheckCount m142 : 32|15@1+ (1,0) [0|0] "" Vector__XXX
 SG_ DIF_a144_brakeActuationType m144 : 32|1@1+ (1,0) [0|0] "" Vector__XXX
 SG_ DIF_a149_temperature m149 : 32|8@1+ (1,-40) [0|0] "" Vector__XXX
 SG_ DIF_a150_vBatFilteredRate m150 : 32|8@1- (100,0) [0|0] "" Vector__XXX
 SG_ DIF_a151_torqueDriver m151 : 32|16@1- (0.25,0) [0|0] "" Vector__XXX
 SG_ DIF_a152_badValue m152 : 32|8@1+ (1,0) [0|0] "" Vector__XXX
 SG_ DIF_a153_phaseCurrent m153 : 32|8@1+ (0.1,0) [0|0] "" Vector__XXX
 SG_ DIF_a154_phaseError m154 : 32|8@1- (0.004,0) [0|0] "" Vector__XXX
 SG_ DIF_a156_ucrPlausible m156 : 32|1@1+ (1,0) [0|0] "" Vector__XXX
 SG_ DIF_a160_vBatFilteredRate m160 : 32|8@1- (100,0) [0|0] "" Vector__XXX
 SG_ DIF_a162_initialVehicleOdometer m162 : 32|10@1+ (400,0) [0|0] "" Vector__XXX
 SG_ DIF_a172_statorTemp2 m172 : 32|16@1- (0.1,0) [0|0] "" Vector__XXX
 SG_ DIF_a177_correctedValue m177 : 32|16@1+ (0.0001,0) [0|0] "" Vector__XXX
 SG_ DIF_a202_sysStateExitCondition m202 : 32|5@1+ (1,0) [0|0] "" Vector__XXX
 SG_ DIF_a244_delay m244 : 32|16@1+ (1,0) [0|0] "" Vector__XXX
 SG_ DIF_a246_motorRPM m246 : 32|8@1- (150,0) [0|0] "" Vector__XXX
 SG_ DIF_a247_motorRPM m247 : 32|16@1- (1,0) [0|0] "" Vector__XXX
 SG_ DIF_a249_statorTempFromResist m249 : 32|8@1+ (1,-40) [0|0] "" Vector__XXX
 SG_ DIF_a251_dcVoltage m251 : 32|8@1+ (0.3,0) [0|0] "" Vector__XXX
 SG_ DIF_a001_deadtimeError_H m1 : 31|1@1+ (1,0) [0|0] "" Vector__XXX
 SG_ DIF_a002_deadtimeError_H m2 : 31|1@1+ (1,0) [0|0] "" Vector__XXX
 SG_ DIF_a003_deadtimeError_H m3 : 31|1@1+ (1,0) [0|0] "" Vector__XXX
 SG_ DIF_a024_Ia m24 : 31|7@1- (22.5,0) [0|0] "" Vector__XXX
 SG_ DIF_a136_spiError_AH m136 : 31|1@1+ (1,0) [0|0] "" Vector__XXX
 SG_ DIF_a144_softPerformanceLimit m144 : 31|1@1+ (1,0) [0|0] "" Vector__XXX
 SG_ DIF_a156_highMotorSpeed m156 : 31|1@1+ (1,0) [0|0] "" Vector__XXX
 SG_ DIF_a244_plausibleSingleSwitchSh m244 : 31|1@1+ (1,0) [0|0] "" Vector__XXX
 SG_ DIF_a001_spiError_H m1 : 30|1@1+ (1,0) [0|0] "" Vector__XXX
 SG_ DIF_a002_spiError_H m2 : 30|1@1+ (1,0) [0|0] "" Vector__XXX
 SG_ DIF_a003_spiError_H m3 : 30|1@1+ (1,0) [0|0] "" Vector__XXX
 SG_ DIF_a014_adState m14 : 30|2@1+ (1,0) [0|0] "" Vector__XXX
 SG_ DIF_a015_pyroSenseIrrational m15 : 30|1@1+ (1,0) [0|0] "" Vector__XXX
 SG_ DIF_a117_odometerStatus m117 : 30|1@1+ (1,0) [0|0] "" Vector__XXX
 SG_ DIF_a136_busyError_AL m136 : 30|1@1+ (1,0) [0|0] "" Vector__XXX
 SG_ DIF_a144_heatsinkType m144 : 30|1@1+ (1,0) [0|0] "" Vector__XXX
 SG_ DIF_a156_highCurrentMagnitude m156 : 30|1@1+ (1,0) [0|0] "" Vector__XXX
 SG_ DIF_a244_gateDriveICUndervoltage m244 : 30|1@1+ (1,0) [0|0] "" Vector__XXX
 SG_ DIF_a253_reason m253 : 30|2@1+ (1,0) [0|0] "" Vector__XXX
 SG_ DIF_a254_vBat m254 : 30|10@1+ (2,0) [0|0] "" Vector__XXX
 SG_ DIF_a001_localRegError_H m1 : 29|1@1+ (1,0) [0|0] "" Vector__XXX
 SG_ DIF_a002_localRegError_H m2 : 29|1@1+ (1,0) [0|0] "" Vector__XXX
 SG_ DIF_a003_localRegError_H m3 : 29|1@1+ (1,0) [0|0] "" Vector__XXX
 SG_ DIF_a010_ovfNmi m10 : 29|1@1+ (1,0) [0|0] "" Vector__XXX
 SG_ DIF_a136_crcError_AL m136 : 29|1@1+ (1,0) [0|0] "" Vector__XXX
 SG_ DIF_a144_oilPump2HwType m144 : 29|1@1+ (1,0) [0|0] "" Vector__XXX
 SG_ DIF_a229_reason m229 : 29|1@1+ (1,0) [0|0] "" Vector__XXX
 SG_ DIF_a001_overvoltVDD_H m1 : 28|1@1+ (1,0) [0|0] "" Vector__XXX
 SG_ DIF_a002_overvoltVDD_H m2 : 28|1@1+ (1,0) [0|0] "" Vector__XXX
 SG_ DIF_a003_overvoltVDD_H m3 : 28|1@1+ (1,0) [0|0] "" Vector__XXX
 SG_ DIF_a010_rlNmi m10 : 28|1@1+ (1,0) [0|0] "" Vector__XXX
 SG_ DIF_a094_errorType m94 : 28|3@1+ (1,0) [0|0] "" Vector__XXX
 SG_ DIF_a134_wheelSpeedDiffFrR m134 : 28|12@1- (0.0625,0) [0|0] "" Vector__XXX
 SG_ DIF_a136_spiError_AL m136 : 28|1@1+ (1,0) [0|0] "" Vector__XXX
 SG_ DIF_a144_oilPump1HwType m144 : 28|1@1+ (1,0) [0|0] "" Vector__XXX
 SG_ DIF_a148_timeBelow50degC m148 : 28|9@1+ (30,0) [0|0] "" Vector__XXX
 SG_ DIF_a156_powerPolarity m156 : 28|2@1+ (1,0) [0|0] "" Vector__XXX
 SG_ DIF_a240_secondaryPattern m240 : 28|6@1+ (1,0) [0|0] "" Vector__XXX
 SG_ DIF_a250_reason m250 : 28|2@1+ (1,0) [0|0] "" Vector__XXX
 SG_ DIF_a001_undervoltVDD_H m1 : 27|1@1+ (1,0) [0|0] "" Vector__XXX
 SG_ DIF_a002_undervoltVDD_H m2 : 27|1@1+ (1,0) [0|0] "" Vector__XXX
 SG_ DIF_a003_undervoltVDD_H m3 : 27|1@1+ (1,0) [0|0] "" Vector__XXX
 SG_ DIF_a010_sysDbgNmi m10 : 27|1@1+ (1,0) [0|0] "" Vector__XXX
 SG_ DIF_a024_state m24 : 27|4@1+ (1,0) [0|0] "" Vector__XXX
 SG_ DIF_a103_inverterTemp m103 : 27|8@1- (2.0078740157480315,68.26771653543307) [0|0] "" Vector__XXX
 SG_ DIF_a136_busyError_CH m136 : 27|1@1+ (1,0) [0|0] "" Vector__XXX
 SG_ DIF_a144_platformMaxBusVoltage m144 : 27|1@1+ (1,0) [0|0] "" Vector__XXX
 SG_ DIF_a155_liftgateStatus m155 : 27|1@1+ (1,0) [0|0] "" Vector__XXX
 SG_ DIF_a001_remoteRegError_H m1 : 26|1@1+ (1,0) [0|0] "" Vector__XXX
 SG_ DIF_a002_remoteRegError_H m2 : 26|1@1+ (1,0) [0|0] "" Vector__XXX
 SG_ DIF_a003_remoteRegError_H m3 : 26|1@1+ (1,0) [0|0] "" Vector__XXX
 SG_ DIF_a010_pieVectErrorNmi m10 : 26|1@1+ (1,0) [0|0] "" Vector__XXX
 SG_ DIF_a042_outletTemp m42 : 26|10@1+ (0.25,-60) [0|0] "" Vector__XXX
 SG_ DIF_a045_outletTemp m45 : 26|10@1+ (0.25,-60) [0|0] "" Vector__XXX
 SG_ DIF_a058_outletTemp m58 : 26|10@1+ (0.25,-60) [0|0] "" Vector__XXX
 SG_ DIF_a074_speed2Type m74 : 26|2@1+ (1,0) [0|0] "" Vector__XXX
 SG_ DIF_a092_bmsSystemStatus m92 : 26|1@1+ (1,0) [0|0] "" Vector__XXX
 SG_ DIF_a103_fluidImplausible m103 : 26|1@1+ (1,0) [0|0] "" Vector__XXX
 SG_ DIF_a136_crcError_CH m136 : 26|1@1+ (1,0) [0|0] "" Vector__XXX
 SG_ DIF_a144_frunkLatchType m144 : 26|1@1+ (1,0) [0|0] "" Vector__XXX
 SG_ DIF_a156_phaseCPolarity m156 : 26|2@1+ (1,0) [0|0] "" Vector__XXX
 SG_ DIF_a001_asynchStop_H m1 : 25|1@1+ (1,0) [0|0] "" Vector__XXX
 SG_ DIF_a002_asynchStop_H m2 : 25|1@1+ (1,0) [0|0] "" Vector__XXX
 SG_ DIF_a003_asynchStop_H m3 : 25|1@1+ (1,0) [0|0] "" Vector__XXX
 SG_ DIF_a010_cpu2signMismatchNmi m10 : 25|1@1+ (1,0) [0|0] "" Vector__XXX
 SG_ DIF_a011_regAddress m11 : 25|5@1+ (1,0) [0|0] "" Vector__XXX
 SG_ DIF_a035_phaseDifference m35 : 25|7@1+ (1,0) [0|0] "" Vector__XXX
 SG_ DIF_a088_uiDriveSystemsDebug m88 : 25|1@1+ (1,0) [0|0] "" Vector__XXX
 SG_ DIF_a092_bmsPackConfig m92 : 25|1@1+ (1,0) [0|0] "" Vector__XXX
 SG_ DIF_a103_lowFlowDetected m103 : 25|1@1+ (1,0) [0|0] "" Vector__XXX
 SG_ DIF_a123_badFlux m123 : 25|7@1+ (0.0015,0) [0|0] "" Vector__XXX
 SG_ DIF_a136_spiError_CH m136 : 25|1@1+ (1,0) [0|0] "" Vector__XXX
 SG_ DIF_a144_cabinPTCHeaterType m144 : 25|1@1+ (1,0) [0|0] "" Vector__XXX
 SG_ DIF_a155_systemStatus m155 : 25|1@1+ (1,0) [0|0] "" Vector__XXX
 SG_ DIF_a246_codeBranch m246 : 25|2@1+ (1,0) [0|0] "" Vector__XXX
 SG_ DIF_a001_undervoltVCC_H m1 : 24|1@1+ (1,0) [0|0] "" Vector__XXX
 SG_ DIF_a002_undervoltVCC_H m2 : 24|1@1+ (1,0) [0|0] "" Vector__XXX
 SG_ DIF_a003_undervoltVCC_H m3 : 24|1@1+ (1,0) [0|0] "" Vector__XXX
 SG_ DIF_a007_phaseBcurrent m7 : 24|8@1+ (8,0) [0|0] "" Vector__XXX
 SG_ DIF_a010_cpu1signMismatchNmi m10 : 24|1@1+ (1,0) [0|0] "" Vector__XXX
 SG_ DIF_a011_phaseCLow m11 : 24|1@1+ (1,0) [0|0] "" Vector__XXX
 SG_ DIF_a015_lightSenseV m15 : 24|6@1+ (0.1,0) [0|0] "" Vector__XXX
 SG_ DIF_a016_motorRPM m16 : 24|16@1- (1,0) [0|0] "" Vector__XXX
 SG_ DIF_a024_failReason m24 : 24|3@1+ (1,0) [0|0] "" Vector__XXX
 SG_ DIF_a035_noDriveCurrent m35 : 24|1@1+ (1,0) [0|0] "" Vector__XXX
 SG_ DIF_a041_sdcUartRxVersion m41 : 24|4@1+ (1,0) [0|0] "" Vector__XXX
 SG_ DIF_a049_statorTemp2 m49 : 24|8@1- (1,80) [0|0] "" Vector__XXX
 SG_ DIF_a061_phTemp m61 : 24|16@1- (0.1,0) [0|0] "" Vector__XXX
 SG_ DIF_a074_speed1Type m74 : 24|2@1+ (1,0) [0|0] "" Vector__XXX
 SG_ DIF_a078_adcRefLowAvg m78 : 24|16@1+ (1,0) [0|0] "" Vector__XXX
 SG_ DIF_a079_adcRefHighAvg m79 : 24|16@1+ (1,0) [0|0] "" Vector__XXX
 SG_ DIF_a088_semiControls m88 : 24|1@1+ (1,0) [0|0] "" Vector__XXX
 SG_ DIF_a092_bmsVoltageRegGain m92 : 24|1@1+ (1,0) [0|0] "" Vector__XXX
 SG_ DIF_a096_word1 m96 : 24|16@1+ (1,0) [0|0] "" Vector__XXX
 SG_ DIF_a097_lineNumber m97 : 24|16@1+ (1,0) [0|0] "" Vector__XXX
 SG_ DIF_a099_cpuUsage1Hz m99 : 24|8@1+ (1,0) [0|0] "" Vector__XXX
 SG_ DIF_a103_noFlowDetected m103 : 24|1@1+ (1,0) [0|0] "" Vector__XXX
 SG_ DIF_a108_toState m108 : 24|8@1+ (1,0) [0|0] "" Vector__XXX
 SG_ DIF_a117_vehicle m117 : 24|1@1+ (1,0) [0|0] "" Vector__XXX
 SG_ DIF_a122_stackUsed m122 : 24|16@1+ (1,0) [0|0] "" Vector__XXX
 SG_ DIF_a127_temp m127 : 24|16@1- (0.1,0) [0|0] "" Vector__XXX
 SG_ DIF_a136_busyError_CL m136 : 24|1@1+ (1,0) [0|0] "" Vector__XXX
 SG_ DIF_a144_inverterHardware m144 : 24|1@1+ (1,0) [0|0] "" Vector__XXX
 SG_ DIF_a147_overtorque2UsedCount m147 : 24|10@1+ (1,0) [0|0] "" Vector__XXX
 SG_ DIF_a149_voltage m149 : 24|8@1+ (0.1,0) [0|0] "" Vector__XXX
 SG_ DIF_a152_frameId m152 : 24|8@1+ (1,0) [0|0] "" Vector__XXX
 SG_ DIF_a153_oilTemperature m153 : 24|8@1+ (1,-40) [0|0] "" Vector__XXX
 SG_ DIF_a155_restraintStatus m155 : 24|1@1+ (1,0) [0|0] "" Vector__XXX
 SG_ DIF_a156_phaseBPolarity m156 : 24|2@1+ (1,0) [0|0] "" Vector__XXX
 SG_ DIF_a162_additionalFetBurnIn m162 : 24|8@1+ (2,0) [0|0] "" Vector__XXX
 SG_ DIF_a173_phaseCPeriodViolation2 m173 : 24|1@1+ (1,0) [0|0] "" Vector__XXX
 SG_ DIF_a241_rotorMaxMagnetTemp m241 : 24|8@1- (1,88) [0|0] "" Vector__XXX
 SG_ DIF_a243_triggerEvent m243 : 24|6@1+ (1,0) [0|0] "" Vector__XXX
 SG_ DIF_a244_irSensorV m244 : 24|6@1+ (0.1,0) [0|0] "" Vector__XXX
 SG_ DIF_a246_lvIsGood m246 : 24|1@1+ (1,0) [0|0] "" Vector__XXX
 SG_ DIF_a251_oilTemperature m251 : 24|8@1+ (1,-40) [0|0] "" Vector__XXX
 SG_ DIF_a001_overvoltVH_H m1 : 23|1@1+ (1,0) [0|0] "" Vector__XXX
 SG_ DIF_a002_overvoltVH_H m2 : 23|1@1+ (1,0) [0|0] "" Vector__XXX
 SG_ DIF_a003_overvoltVH_H m3 : 23|1@1+ (1,0) [0|0] "" Vector__XXX
 SG_ DIF_a010_flashUncErrorNmi m10 : 23|1@1+ (1,0) [0|0] "" Vector__XXX
 SG_ DIF_a011_phaseCHigh m11 : 23|1@1+ (1,0) [0|0] "" Vector__XXX
 SG_ DIF_a016_pedalMonitorPreWatchdog m16 : 23|1@1+ (1,0) [0|0] "" Vector__XXX
 SG_ DIF_a088_vehicleControl2 m88 : 23|1@1+ (1,0) [0|0] "" Vector__XXX
 SG_ DIF_a091_ESP_redundantBrakingSta m91 : 23|1@1+ (1,0) [0|0] "" Vector__XXX
 SG_ DIF_a092_bmsCtrStatus m92 : 23|1@1+ (1,0) [0|0] "" Vector__XXX
 SG_ DIF_a117_temperature m117 : 23|1@1+ (1,0) [0|0] "" Vector__XXX
 SG_ DIF_a136_crcError_CL m136 : 23|1@1+ (1,0) [0|0] "" Vector__XXX
 SG_ DIF_a144_brakeHWType m144 : 23|1@1+ (1,0) [0|0] "" Vector__XXX
 SG_ DIF_a155_vcleftSwitchStatus m155 : 23|1@1+ (1,0) [0|0] "" Vector__XXX
 SG_ DIF_a173_phaseCPeriodViolation1 m173 : 23|1@1+ (1,0) [0|0] "" Vector__XXX
 SG_ DIF_a246_hvIsGood m246 : 23|1@1+ (1,0) [0|0] "" Vector__XXX
 SG_ DIF_a001_overvoltVL_H m1 : 22|1@1+ (1,0) [0|0] "" Vector__XXX
 SG_ DIF_a002_overvoltVL_H m2 : 22|1@1+ (1,0) [0|0] "" Vector__XXX
 SG_ DIF_a003_overvoltVL_H m3 : 22|1@1+ (1,0) [0|0] "" Vector__XXX
 SG_ DIF_a010_ramUncErrorNmi m10 : 22|1@1+ (1,0) [0|0] "" Vector__XXX
 SG_ DIF_a011_phaseBLow m11 : 22|1@1+ (1,0) [0|0] "" Vector__XXX
 SG_ DIF_a015_lightSenseIrrational m15 : 22|1@1+ (1,0) [0|0] "" Vector__XXX
 SG_ DIF_a016_uncontrolledRegenZone m16 : 22|1@1+ (1,0) [0|0] "" Vector__XXX
 SG_ DIF_a035_reportingPhase m35 : 22|2@1+ (1,0) [0|0] "" Vector__XXX
 SG_ DIF_a040_temperature m40 : 22|1@1+ (1,0) [0|0] "" Vector__XXX
 SG_ DIF_a052_temperature m52 : 22|1@1+ (1,0) [0|0] "" Vector__XXX
 SG_ DIF_a088_mcuDriverLimits m88 : 22|1@1+ (1,0) [0|0] "" Vector__XXX
 SG_ DIF_a091_ESP_party3 m91 : 22|1@1+ (1,0) [0|0] "" Vector__XXX
 SG_ DIF_a092_bmsThermalStatus m92 : 22|1@1+ (1,0) [0|0] "" Vector__XXX
 SG_ DIF_a117_systemStatus m117 : 22|1@1+ (1,0) [0|0] "" Vector__XXX
 SG_ DIF_a136_spiError_CL m136 : 22|1@1+ (1,0) [0|0] "" Vector__XXX
 SG_ DIF_a144_vdcType m144 : 22|1@1+ (1,0) [0|0] "" Vector__XXX
 SG_ DIF_a148_initialJunctionT m148 : 22|6@1+ (3,-40) [0|0] "" Vector__XXX
 SG_ DIF_a155_rightDoorStatus m155 : 22|1@1+ (1,0) [0|0] "" Vector__XXX
 SG_ DIF_a156_phaseAPolarity m156 : 22|2@1+ (1,0) [0|0] "" Vector__XXX
 SG_ DIF_a173_phaseBPeriodViolation2 m173 : 22|1@1+ (1,0) [0|0] "" Vector__XXX
 SG_ DIF_a240_primaryPattern m240 : 22|6@1+ (1,0) [0|0] "" Vector__XXX
 SG_ DIF_a245_unexpectedCurrent m245 : 22|1@1+ (1,0) [0|0] "" Vector__XXX
 SG_ DIF_a246_observerDetectedLS3PS m246 : 22|1@1+ (1,0) [0|0] "" Vector__XXX
 SG_ DIF_a001_desat_H m1 : 21|1@1+ (1,0) [0|0] "" Vector__XXX
 SG_ DIF_a002_desat_H m2 : 21|1@1+ (1,0) [0|0] "" Vector__XXX
 SG_ DIF_a003_desat_H m3 : 21|1@1+ (1,0) [0|0] "" Vector__XXX
 SG_ DIF_a010_clockFailNmi m10 : 21|1@1+ (1,0) [0|0] "" Vector__XXX
 SG_ DIF_a011_phaseBHigh m11 : 21|1@1+ (1,0) [0|0] "" Vector__XXX
 SG_ DIF_a015_armedFailed m15 : 21|1@1+ (1,0) [0|0] "" Vector__XXX
 SG_ DIF_a016_ascMonitor m16 : 21|1@1+ (1,0) [0|0] "" Vector__XXX
 SG_ DIF_a035_wontMoveCurrent m35 : 21|1@1+ (1,0) [0|0] "" Vector__XXX
 SG_ DIF_a040_hvStatus m40 : 21|1@1+ (1,0) [0|0] "" Vector__XXX
 SG_ DIF_a052_hvStatus m52 : 21|1@1+ (1,0) [0|0] "" Vector__XXX
 SG_ DIF_a088_uiTrackModeSettings m88 : 21|1@1+ (1,0) [0|0] "" Vector__XXX
 SG_ DIF_a090_state4 m90 : 21|1@1+ (1,0) [0|0] "" Vector__XXX
 SG_ DIF_a091_ESP_status m91 : 21|1@1+ (1,0) [0|0] "" Vector__XXX
 SG_ DIF_a092_bmsSocStatus m92 : 21|1@1+ (1,0) [0|0] "" Vector__XXX
 SG_ DIF_a096_boot_flash m96 : 21|1@1+ (1,0) [0|0] "" Vector__XXX
 SG_ DIF_a112_modulationIndex m112 : 21|11@1+ (0.00048828125,0) [0|0] "" Vector__XXX
 SG_ DIF_a117_chassisControl m117 : 21|1@1+ (1,0) [0|0] "" Vector__XXX
 SG_ DIF_a136_busyError_BH m136 : 21|1@1+ (1,0) [0|0] "" Vector__XXX
 SG_ DIF_a144_performancePackage m144 : 21|1@1+ (1,0) [0|0] "" Vector__XXX
 SG_ DIF_a155_leftDoorStatus m155 : 21|1@1+ (1,0) [0|0] "" Vector__XXX
 SG_ DIF_a173_phaseBPeriodViolation1 m173 : 21|1@1+ (1,0) [0|0] "" Vector__XXX
 SG_ DIF_a244_udsSelfTest m244 : 21|1@1+ (1,0) [0|0] "" Vector__XXX
 SG_ DIF_a245_gateDriveSupplyFault m245 : 21|1@1+ (1,0) [0|0] "" Vector__XXX
 SG_ DIF_a246_currentSensorRational m246 : 21|1@1+ (1,0) [0|0] "" Vector__XXX
 SG_ DIF_a001_sense_H m1 : 20|1@1+ (1,0) [0|0] "" Vector__XXX
 SG_ DIF_a002_sense_H m2 : 20|1@1+ (1,0) [0|0] "" Vector__XXX
 SG_ DIF_a003_sense_H m3 : 20|1@1+ (1,0) [0|0] "" Vector__XXX
 SG_ DIF_a010_watchdog m10 : 20|1@1+ (1,0) [0|0] "" Vector__XXX
 SG_ DIF_a011_phaseALow m11 : 20|1@1+ (1,0) [0|0] "" Vector__XXX
 SG_ DIF_a015_swLowsideTestFailed m15 : 20|1@1+ (1,0) [0|0] "" Vector__XXX
 SG_ DIF_a016_gateDriveFaultLine m16 : 20|1@1+ (1,0) [0|0] "" Vector__XXX
 SG_ DIF_a035_unbalancedCurrent m35 : 20|1@1+ (1,0) [0|0] "" Vector__XXX
 SG_ DIF_a040_capability2 m40 : 20|1@1+ (1,0) [0|0] "" Vector__XXX
 SG_ DIF_a052_capability2 m52 : 20|1@1+ (1,0) [0|0] "" Vector__XXX
 SG_ DIF_a064_torqueCmdState m64 : 20|4@1+ (1,0) [0|0] "" Vector__XXX
 SG_ DIF_a087_carState m87 : 20|1@1+ (1,0) [0|0] "" Vector__XXX
 SG_ DIF_a088_uiVehicleModes m88 : 20|1@1+ (1,0) [0|0] "" Vector__XXX
 SG_ DIF_a090_state2 m90 : 20|1@1+ (1,0) [0|0] "" Vector__XXX
 SG_ DIF_a091_ESP_offsets m91 : 20|1@1+ (1,0) [0|0] "" Vector__XXX
 SG_ DIF_a092_bmsBmbMinMax m92 : 20|1@1+ (1,0) [0|0] "" Vector__XXX
 SG_ DIF_a096_mem_regs m96 : 20|1@1+ (1,0) [0|0] "" Vector__XXX
 SG_ DIF_a099_thread1kHz m99 : 20|1@1+ (1,0) [0|0] "" Vector__XXX
 SG_ DIF_a112_hs3psSafeState m112 : 20|1@1+ (1,0) [0|0] "" Vector__XXX
 SG_ DIF_a117_speed m117 : 20|1@1+ (1,0) [0|0] "" Vector__XXX
 SG_ DIF_a136_crcError_BH m136 : 20|1@1+ (1,0) [0|0] "" Vector__XXX
 SG_ DIF_a144_packPerformanceDeviatio m144 : 20|1@1+ (1,0) [0|0] "" Vector__XXX
 SG_ DIF_a155_status m155 : 20|1@1+ (1,0) [0|0] "" Vector__XXX
 SG_ DIF_a173_phaseAPeriodViolation2 m173 : 20|1@1+ (1,0) [0|0] "" Vector__XXX
 SG_ DIF_a202_movement m202 : 20|9@1+ (0.005,0) [0|0] "" Vector__XXX
 SG_ DIF_a233_serviceModeActive m233 : 20|1@1+ (1,0) [0|0] "" Vector__XXX
 SG_ DIF_a244_postShortTestFailed m244 : 20|1@1+ (1,0) [0|0] "" Vector__XXX
 SG_ DIF_a245_doubleSwitchShort m245 : 20|1@1+ (1,0) [0|0] "" Vector__XXX
 SG_ DIF_a246_didPMCauseASC m246 : 20|1@1+ (1,0) [0|0] "" Vector__XXX
 SG_ DIF_a001_undervoltVH_H m1 : 19|1@1+ (1,0) [0|0] "" Vector__XXX
 SG_ DIF_a002_undervoltVH_H m2 : 19|1@1+ (1,0) [0|0] "" Vector__XXX
 SG_ DIF_a003_undervoltVH_H m3 : 19|1@1+ (1,0) [0|0] "" Vector__XXX
 SG_ DIF_a010_nmiWatchdog m10 : 19|1@1+ (1,0) [0|0] "" Vector__XXX
 SG_ DIF_a011_phaseAHigh m11 : 19|1@1+ (1,0) [0|0] "" Vector__XXX
 SG_ DIF_a015_swHighsideTestFailed m15 : 19|1@1+ (1,0) [0|0] "" Vector__XXX
 SG_ DIF_a035_standbyCurrent m35 : 19|1@1+ (1,0) [0|0] "" Vector__XXX
 SG_ DIF_a040_status m40 : 19|1@1+ (1,0) [0|0] "" Vector__XXX
 SG_ DIF_a052_status m52 : 19|1@1+ (1,0) [0|0] "" Vector__XXX
 SG_ DIF_a087_gearControl m87 : 19|1@1+ (1,0) [0|0] "" Vector__XXX
 SG_ DIF_a088_uiPowertrainControl m88 : 19|1@1+ (1,0) [0|0] "" Vector__XXX
 SG_ DIF_a090_locState m90 : 19|1@1+ (1,0) [0|0] "" Vector__XXX
 SG_ DIF_a091_ESP_motorLimits m91 : 19|1@1+ (1,0) [0|0] "" Vector__XXX
 SG_ DIF_a092_bmsPowerAvailable m92 : 19|1@1+ (1,0) [0|0] "" Vector__XXX
 SG_ DIF_a096_mem_data m96 : 19|1@1+ (1,0) [0|0] "" Vector__XXX
 SG_ DIF_a099_thread100Hz m99 : 19|1@1+ (1,0) [0|0] "" Vector__XXX
 SG_ DIF_a110_EPBR_autonomyHealth m110 : 19|1@1+ (1,0) [0|0] "" Vector__XXX
 SG_ DIF_a112_ls3psSafeState m112 : 19|1@1+ (1,0) [0|0] "" Vector__XXX
 SG_ DIF_a117_slaveCommand2 m117 : 19|1@1+ (1,0) [0|0] "" Vector__XXX
 SG_ DIF_a121_torqueDelta m121 : 19|13@1- (0.25,0) [0|0] "" Vector__XXX
 SG_ DIF_a123_busVoltage m123 : 19|6@1+ (4,250) [0|0] "" Vector__XXX
 SG_ DIF_a136_spiError_BH m136 : 19|1@1+ (1,0) [0|0] "" Vector__XXX
 SG_ DIF_a144_packEnergy m144 : 19|1@1+ (1,0) [0|0] "" Vector__XXX
 SG_ DIF_a155_vehicleStatus m155 : 19|1@1+ (1,0) [0|0] "" Vector__XXX
 SG_ DIF_a173_phaseAPeriodViolation1 m173 : 19|1@1+ (1,0) [0|0] "" Vector__XXX
 SG_ DIF_a225_hsDeltaImplausible m225 : 19|1@1+ (1,0) [0|0] "" Vector__XXX
 SG_ DIF_a244_flybackFault m244 : 19|1@1+ (1,0) [0|0] "" Vector__XXX
 SG_ DIF_a245_lowSpeedShort m245 : 19|1@1+ (1,0) [0|0] "" Vector__XXX
 SG_ DIF_a001_undervoltVL_H m1 : 18|1@1+ (1,0) [0|0] "" Vector__XXX
 SG_ DIF_a002_undervoltVL_H m2 : 18|1@1+ (1,0) [0|0] "" Vector__XXX
 SG_ DIF_a003_undervoltVL_H m3 : 18|1@1+ (1,0) [0|0] "" Vector__XXX
 SG_ DIF_a010_hwBist m10 : 18|1@1+ (1,0) [0|0] "" Vector__XXX
 SG_ DIF_a015_hwIrTestFailed m15 : 18|1@1+ (1,0) [0|0] "" Vector__XXX
 SG_ DIF_a016_oldSafeState m16 : 18|2@1+ (1,0) [0|0] "" Vector__XXX
 SG_ DIF_a035_phaseCerror m35 : 18|1@1+ (1,0) [0|0] "" Vector__XXX
 SG_ DIF_a040_power m40 : 18|1@1+ (1,0) [0|0] "" Vector__XXX
 SG_ DIF_a041_diUartRxVersion m41 : 18|4@1+ (1,0) [0|0] "" Vector__XXX
 SG_ DIF_a052_power m52 : 18|1@1+ (1,0) [0|0] "" Vector__XXX
 SG_ DIF_a061_reason m61 : 18|1@1+ (1,0) [0|0] "" Vector__XXX
 SG_ DIF_a087_gtwUpdateStatus m87 : 18|1@1+ (1,0) [0|0] "" Vector__XXX
 SG_ DIF_a088_uiDriverAssistMapData m88 : 18|1@1+ (1,0) [0|0] "" Vector__XXX
 SG_ DIF_a090_state m90 : 18|1@1+ (1,0) [0|0] "" Vector__XXX
 SG_ DIF_a091_ESP_wheelRotation m91 : 18|1@1+ (1,0) [0|0] "" Vector__XXX
 SG_ DIF_a092_bmsHvBusStatus m92 : 18|1@1+ (1,0) [0|0] "" Vector__XXX
 SG_ DIF_a096_text_flash m96 : 18|1@1+ (1,0) [0|0] "" Vector__XXX
 SG_ DIF_a099_thread10Hz m99 : 18|1@1+ (1,0) [0|0] "" Vector__XXX
 SG_ DIF_a110_EPBL_autonomyHealth m110 : 18|1@1+ (1,0) [0|0] "" Vector__XXX
 SG_ DIF_a112_allOffSafeState m112 : 18|1@1+ (1,0) [0|0] "" Vector__XXX
 SG_ DIF_a117_power m117 : 18|1@1+ (1,0) [0|0] "" Vector__XXX
 SG_ DIF_a136_busyError_BL m136 : 18|1@1+ (1,0) [0|0] "" Vector__XXX
 SG_ DIF_a144_drivetrainType m144 : 18|1@1+ (1,0) [0|0] "" Vector__XXX
 SG_ DIF_a155_LVPowerState m155 : 18|1@1+ (1,0) [0|0] "" Vector__XXX
 SG_ DIF_a156_observation m156 : 18|4@1+ (1,0) [0|0] "" Vector__XXX
 SG_ DIF_a158_BUS2_IBST_status m158 : 18|1@1+ (1,0) [0|0] "" Vector__XXX
 SG_ DIF_a173_phaseCDetected m173 : 18|1@1+ (1,0) [0|0] "" Vector__XXX
 SG_ DIF_a225_fluidImplausible m225 : 18|1@1+ (1,0) [0|0] "" Vector__XXX
 SG_ DIF_a242_ResolverError m242 : 18|1@1+ (1,0) [0|0] "" Vector__XXX
 SG_ DIF_a244_singleSwitchShort m244 : 18|1@1+ (1,0) [0|0] "" Vector__XXX
 SG_ DIF_a245_unsuccessfulSafeState m245 : 18|1@1+ (1,0) [0|0] "" Vector__XXX
 SG_ DIF_a001_thermalShutdown_H m1 : 17|1@1+ (1,0) [0|0] "" Vector__XXX
 SG_ DIF_a002_thermalShutdown_H m2 : 17|1@1+ (1,0) [0|0] "" Vector__XXX
 SG_ DIF_a003_thermalShutdown_H m3 : 17|1@1+ (1,0) [0|0] "" Vector__XXX
 SG_ DIF_a010_hibernate m10 : 17|1@1+ (1,0) [0|0] "" Vector__XXX
 SG_ DIF_a015_hwOpenCircuitTestFailed m15 : 17|1@1+ (1,0) [0|0] "" Vector__XXX
 SG_ DIF_a035_phaseBerror m35 : 17|1@1+ (1,0) [0|0] "" Vector__XXX
 SG_ DIF_a040_capability m40 : 17|1@1+ (1,0) [0|0] "" Vector__XXX
 SG_ DIF_a041_SDC_status_MIA m41 : 17|1@1+ (1,0) [0|0] "" Vector__XXX
 SG_ DIF_a052_capability m52 : 17|1@1+ (1,0) [0|0] "" Vector__XXX
 SG_ DIF_a087_gtwTime m87 : 17|1@1+ (1,0) [0|0] "" Vector__XXX
 SG_ DIF_a088_uiCruiseControl m88 : 17|1@1+ (1,0) [0|0] "" Vector__XXX
 SG_ DIF_a091_ESP_wheelSpeeds m91 : 17|1@1+ (1,0) [0|0] "" Vector__XXX
 SG_ DIF_a092_bmsDriveLimits m92 : 17|1@1+ (1,0) [0|0] "" Vector__XXX
 SG_ DIF_a096_text_fast m96 : 17|1@1+ (1,0) [0|0] "" Vector__XXX
 SG_ DIF_a099_thread1Hz m99 : 17|1@1+ (1,0) [0|0] "" Vector__XXX
 SG_ DIF_a110_EPBR_status m110 : 17|1@1+ (1,0) [0|0] "" Vector__XXX
 SG_ DIF_a112_gdicResetLine m112 : 17|1@1+ (1,0) [0|0] "" Vector__XXX
 SG_ DIF_a117_slaveCommand m117 : 17|1@1+ (1,0) [0|0] "" Vector__XXX
 SG_ DIF_a136_crcError_BL m136 : 17|1@1+ (1,0) [0|0] "" Vector__XXX
 SG_ DIF_a144_chassisType m144 : 17|1@1+ (1,0) [0|0] "" Vector__XXX
 SG_ DIF_a155_coolant m155 : 17|1@1+ (1,0) [0|0] "" Vector__XXX
 SG_ DIF_a157_RCM_inertial2 m157 : 17|1@1+ (1,0) [0|0] "" Vector__XXX
 SG_ DIF_a158_BUS1_IBST_status m158 : 17|1@1+ (1,0) [0|0] "" Vector__XXX
 SG_ DIF_a161_EPAS3P_angleCalib m161 : 17|1@1+ (1,0) [0|0] "" Vector__XXX
 SG_ DIF_a173_phaseBDetected m173 : 17|1@1+ (1,0) [0|0] "" Vector__XXX
 SG_ DIF_a225_hs2Implausible m225 : 17|1@1+ (1,0) [0|0] "" Vector__XXX
 SG_ DIF_a242_RotorFlux m242 : 17|1@1+ (1,0) [0|0] "" Vector__XXX
 SG_ DIF_a244_desatLowSide m244 : 17|1@1+ (1,0) [0|0] "" Vector__XXX
 SG_ DIF_a245_busShort m245 : 17|1@1+ (1,0) [0|0] "" Vector__XXX
 SG_ DIF_a000_alertDataW0 m0 : 16|16@1+ (1,0) [0|0] "" Vector__XXX
 SG_ DIF_a001_thermalWarning_H m1 : 16|1@1+ (1,0) [0|0] "" Vector__XXX
 SG_ DIF_a002_thermalWarning_H m2 : 16|1@1+ (1,0) [0|0] "" Vector__XXX
 SG_ DIF_a003_thermalWarning_H m3 : 16|1@1+ (1,0) [0|0] "" Vector__XXX
 SG_ DIF_a007_phaseAcurrent m7 : 16|8@1+ (8,0) [0|0] "" Vector__XXX
 SG_ DIF_a010_sccReset m10 : 16|1@1+ (1,0) [0|0] "" Vector__XXX
 SG_ DIF_a011_reason m11 : 16|3@1+ (1,0) [0|0] "" Vector__XXX
 SG_ DIF_a013_address m13 : 16|32@1+ (1,0) [0|0] "" Vector__XXX
 SG_ DIF_a014_motorSpeed m14 : 16|14@1- (2,0) [0|0] "" Vector__XXX
 SG_ DIF_a015_hwLatchTestFailed m15 : 16|1@1+ (1,0) [0|0] "" Vector__XXX
 SG_ DIF_a016_newSafeState m16 : 16|2@1+ (1,0) [0|0] "" Vector__XXX
 SG_ DIF_a024_vBat m24 : 16|8@1+ (2,0) [0|0] "" Vector__XXX
 SG_ DIF_a025_Ia m25 : 16|16@1- (0.1,0) [0|0] "" Vector__XXX
 SG_ DIF_a026_Ib m26 : 16|16@1- (0.1,0) [0|0] "" Vector__XXX
 SG_ DIF_a027_Ic m27 : 16|16@1- (0.1,0) [0|0] "" Vector__XXX
 SG_ DIF_a028_phaseAirms m28 : 16|16@1+ (1,0) [0|0] "" Vector__XXX
 SG_ DIF_a029_phaseBirms m29 : 16|16@1+ (1,0) [0|0] "" Vector__XXX
 SG_ DIF_a030_phaseCirms m30 : 16|16@1+ (1,0) [0|0] "" Vector__XXX
 SG_ DIF_a031_phaseAoffset m31 : 16|15@1- (0.002,0) [0|0] "" Vector__XXX
 SG_ DIF_a032_phaseBoffset m32 : 16|15@1- (0.002,0) [0|0] "" Vector__XXX
 SG_ DIF_a033_phaseAcurrent m33 : 16|16@1- (1,0) [0|0] "" Vector__XXX
 SG_ DIF_a034_phaseBcurrent m34 : 16|16@1- (1,0) [0|0] "" Vector__XXX
 SG_ DIF_a035_phaseAerror m35 : 16|1@1+ (1,0) [0|0] "" Vector__XXX
 SG_ DIF_a036_busVoltage m36 : 16|16@1+ (0.1,0) [0|0] "" Vector__XXX
 SG_ DIF_a037_busVoltage m37 : 16|16@1+ (0.1,0) [0|0] "" Vector__XXX
 SG_ DIF_a038_vBMS m38 : 16|13@1+ (0.2,0) [0|0] "" Vector__XXX
 SG_ DIF_a040_torque m40 : 16|1@1+ (1,0) [0|0] "" Vector__XXX
 SG_ DIF_a041_uartRxDataAvailable m41 : 16|1@1+ (1,0) [0|0] "" Vector__XXX
 SG_ DIF_a042_inletTemp m42 : 16|10@1+ (0.25,-60) [0|0] "" Vector__XXX
 SG_ DIF_a043_outletTemp m43 : 16|16@1- (0.1,0) [0|0] "" Vector__XXX
 SG_ DIF_a044_outletTemp m44 : 16|16@1- (0.1,0) [0|0] "" Vector__XXX
 SG_ DIF_a045_inletTemp m45 : 16|10@1+ (0.25,-60) [0|0] "" Vector__XXX
 SG_ DIF_a046_statorTemp1 m46 : 16|16@1- (0.1,0) [0|0] "" Vector__XXX
 SG_ DIF_a047_statorTemp1 m47 : 16|16@1- (0.1,0) [0|0] "" Vector__XXX
 SG_ DIF_a048_statorTemp2 m48 : 16|16@1- (0.1,0) [0|0] "" Vector__XXX
 SG_ DIF_a049_statorTemp1 m49 : 16|8@1- (1,80) [0|0] "" Vector__XXX
 SG_ DIF_a050_statorTemp1 m50 : 16|16@1- (0.1,0) [0|0] "" Vector__XXX
 SG_ DIF_a052_torque m52 : 16|1@1+ (1,0) [0|0] "" Vector__XXX
 SG_ DIF_a054_outletTemp m54 : 16|16@1- (0.1,0) [0|0] "" Vector__XXX
 SG_ DIF_a055_parameterDI m55 : 16|13@1- (0.25,0) [0|0] "" Vector__XXX
 SG_ DIF_a056_pcbTemp m56 : 16|16@1- (0.1,0) [0|0] "" Vector__XXX
 SG_ DIF_a057_pcbTemp m57 : 16|16@1- (0.1,0) [0|0] "" Vector__XXX
 SG_ DIF_a058_pcbTemp m58 : 16|10@1+ (0.25,-60) [0|0] "" Vector__XXX
 SG_ DIF_a059_heatsinkTemp m59 : 16|16@1- (0.1,0) [0|0] "" Vector__XXX
 SG_ DIF_a060_heatsinkTemp m60 : 16|16@1- (0.1,0) [0|0] "" Vector__XXX
 SG_ DIF_a061_sensor m61 : 16|2@1+ (1,0) [0|0] "" Vector__XXX
 SG_ DIF_a062_limpReason m62 : 16|6@1+ (1,0) [0|0] "" Vector__XXX
 SG_ DIF_a064_interventionType m64 : 16|4@1+ (1,0) [0|0] "" Vector__XXX
 SG_ DIF_a065_canID m65 : 16|16@1+ (1,0) [0|0] "" Vector__XXX
 SG_ DIF_a066_badValue1 m66 : 16|16@1+ (1,0) [0|0] "" Vector__XXX
 SG_ DIF_a067_canID m67 : 16|16@1+ (1,0) [0|0] "" Vector__XXX
 SG_ DIF_a069_motorSpeed m69 : 16|16@1- (1,0) [0|0] "" Vector__XXX
 SG_ DIF_a070_serviceDataId m70 : 16|16@1+ (1,0) [0|0] "" Vector__XXX
 SG_ DIF_a071_busVslopeLimit m71 : 16|16@1+ (0.1,0) [0|0] "" Vector__XXX
 SG_ DIF_a072_reason m72 : 16|2@1+ (1,0) [0|0] "" Vector__XXX
 SG_ DIF_a073_motorSpeedrpm m73 : 16|16@1- (1,0) [0|0] "" Vector__XXX
 SG_ DIF_a074_brazeFailCount m74 : 16|8@1+ (1,0) [0|0] "" Vector__XXX
 SG_ DIF_a075_motorSpeed m75 : 16|16@1+ (1,0) [0|0] "" Vector__XXX
 SG_ DIF_a076_lvSupplyV m76 : 16|16@1+ (0.001,0) [0|0] "" Vector__XXX
 SG_ DIF_a077_lvSupplyV m77 : 16|16@1+ (0.001,0) [0|0] "" Vector__XXX
 SG_ DIF_a078_adcRefChan m78 : 16|4@1+ (1,0) [0|0] "" Vector__XXX
 SG_ DIF_a079_adcRefChan m79 : 16|4@1+ (1,0) [0|0] "" Vector__XXX
 SG_ DIF_a084_lowDataValue m84 : 16|32@1+ (1,0) [0|0] "" Vector__XXX
 SG_ DIF_a087_gtwCarConfig m87 : 16|1@1+ (1,0) [0|0] "" Vector__XXX
 SG_ DIF_a088_uiChassisControl m88 : 16|1@1+ (1,0) [0|0] "" Vector__XXX
 SG_ DIF_a090_reason m90 : 16|1@1+ (1,0) [0|0] "" Vector__XXX
 SG_ DIF_a091_ESP_brakeTorque m91 : 16|1@1+ (1,0) [0|0] "" Vector__XXX
 SG_ DIF_a092_bmsStatus m92 : 16|1@1+ (1,0) [0|0] "" Vector__XXX
 SG_ DIF_a093_mailboxID m93 : 16|16@1+ (1,0) [0|0] "" Vector__XXX
 SG_ DIF_a094_canID m94 : 16|12@1+ (1,0) [0|0] "" Vector__XXX
 SG_ DIF_a095_mailboxID m95 : 16|16@1+ (1,0) [0|0] "" Vector__XXX
 SG_ DIF_a096_const_fast m96 : 16|1@1+ (1,0) [0|0] "" Vector__XXX
 SG_ DIF_a097_errorType m97 : 16|3@1+ (1,0) [0|0] "" Vector__XXX
 SG_ DIF_a098_pwmCount m98 : 16|16@1+ (1,0) [0|0] "" Vector__XXX
 SG_ DIF_a099_watchdogReset m99 : 16|1@1+ (1,0) [0|0] "" Vector__XXX
 SG_ DIF_a101_highDataValue m101 : 16|32@1+ (1,0) [0|0] "" Vector__XXX
 SG_ DIF_a103_fluidTorDeltaT m103 : 16|8@1- (2.0078740157480315,68.26771653543307) [0|0] "" Vector__XXX
 SG_ DIF_a107_fpgaVersion m107 : 16|16@1+ (1,0) [0|0] "" Vector__XXX
 SG_ DIF_a108_fromState m108 : 16|8@1+ (1,0) [0|0] "" Vector__XXX
 SG_ DIF_a110_EPBL_status m110 : 16|1@1+ (1,0) [0|0] "" Vector__XXX
 SG_ DIF_a111_phAcalib m111 : 16|16@1+ (1,0) [0|0] "" Vector__XXX
 SG_ DIF_a112_pwmSwitching m112 : 16|1@1+ (1,0) [0|0] "" Vector__XXX
 SG_ DIF_a113_heatsink1Temp m113 : 16|16@1- (0.1,0) [0|0] "" Vector__XXX
 SG_ DIF_a117_torque m117 : 16|1@1+ (1,0) [0|0] "" Vector__XXX
 SG_ DIF_a119_hvpFaults m119 : 16|1@1+ (1,0) [0|0] "" Vector__XXX
 SG_ DIF_a120_dcLinkInfo m120 : 16|1@1+ (1,0) [0|0] "" Vector__XXX
 SG_ DIF_a121_badRegReason m121 : 16|3@1+ (1,0) [0|0] "" Vector__XXX
 SG_ DIF_a122_taskID m122 : 16|5@1+ (1,0) [0|0] "" Vector__XXX
 SG_ DIF_a123_lossReason m123 : 16|3@1+ (1,0) [0|0] "" Vector__XXX
 SG_ DIF_a126_limpReason m126 : 16|6@1+ (1,0) [0|0] "" Vector__XXX
 SG_ DIF_a127_gpoReason m127 : 16|4@1+ (1,0) [0|0] "" Vector__XXX
 SG_ DIF_a128_expectedFPGAversion m128 : 16|16@1+ (1,0) [0|0] "" Vector__XXX
 SG_ DIF_a133_capacitorTemp m133 : 16|16@1- (0.1,0) [0|0] "" Vector__XXX
 SG_ DIF_a134_wheelSpeedDiffFrL m134 : 16|12@1- (0.0625,0) [0|0] "" Vector__XXX
 SG_ DIF_a136_spiError_BL m136 : 16|1@1+ (1,0) [0|0] "" Vector__XXX
 SG_ DIF_a142_lashAngle m142 : 16|10@1+ (0.06,0) [0|0] "" Vector__XXX
 SG_ DIF_a144_autopilot m144 : 16|1@1+ (1,0) [0|0] "" Vector__XXX
 SG_ DIF_a147_overtorque1UsedCount m147 : 16|8@1+ (1,0) [0|0] "" Vector__XXX
 SG_ DIF_a148_initialHeatsinkT m148 : 16|6@1+ (3,-40) [0|0] "" Vector__XXX
 SG_ DIF_a149_flow m149 : 16|8@1+ (0.1,0) [0|0] "" Vector__XXX
 SG_ DIF_a150_vBatRawMinusFiltered m150 : 16|10@1- (1,0) [0|0] "" Vector__XXX
 SG_ DIF_a151_torqueMotor m151 : 16|16@1- (0.25,0) [0|0] "" Vector__XXX
 SG_ DIF_a152_errorType m152 : 16|3@1+ (1,0) [0|0] "" Vector__XXX
 SG_ DIF_a153_oilFlow m153 : 16|8@1+ (0.1,0) [0|0] "" Vector__XXX
 SG_ DIF_a154_motorRPM m154 : 16|16@1- (1,0) [0|0] "" Vector__XXX
 SG_ DIF_a155_sensors m155 : 16|1@1+ (1,0) [0|0] "" Vector__XXX
 SG_ DIF_a156_initialSafeState m156 : 16|2@1+ (1,0) [0|0] "" Vector__XXX
 SG_ DIF_a157_RCM_inertial1 m157 : 16|1@1+ (1,0) [0|0] "" Vector__XXX
 SG_ DIF_a158_IBST_party1 m158 : 16|1@1+ (1,0) [0|0] "" Vector__XXX
 SG_ DIF_a160_vBatRawMinusFiltered m160 : 16|10@1- (1,0) [0|0] "" Vector__XXX
 SG_ DIF_a161_EPAS3P_sysStatus m161 : 16|1@1+ (1,0) [0|0] "" Vector__XXX
 SG_ DIF_a162_normalFetBurnIn m162 : 16|8@1+ (2,0) [0|0] "" Vector__XXX
 SG_ DIF_a172_statorTemp1 m172 : 16|16@1- (0.1,0) [0|0] "" Vector__XXX
 SG_ DIF_a173_phaseADetected m173 : 16|1@1+ (1,0) [0|0] "" Vector__XXX
 SG_ DIF_a177_storedValue m177 : 16|16@1+ (0.0001,0) [0|0] "" Vector__XXX
 SG_ DIF_a202_reason m202 : 16|4@1+ (1,0) [0|0] "" Vector__XXX
 SG_ DIF_a225_hs1Implausible m225 : 16|1@1+ (1,0) [0|0] "" Vector__XXX
 SG_ DIF_a229_vBMS m229 : 16|13@1+ (0.2,0) [0|0] "" Vector__XXX
 SG_ DIF_a233_missedMsgCount m233 : 16|4@1+ (1,0) [0|0] "" Vector__XXX
 SG_ DIF_a234_PCS_dcdcStatus m234 : 16|1@1+ (1,0) [0|0] "" Vector__XXX
 SG_ DIF_a236_states m236 : 16|1@1+ (1,0) [0|0] "" Vector__XXX
 SG_ DIF_a240_shortedSwitches m240 : 16|6@1+ (1,0) [0|0] "" Vector__XXX
 SG_ DIF_a241_statorEndWindingTemp m241 : 16|8@1- (1,88) [0|0] "" Vector__XXX
 SG_ DIF_a242_RotorOffset m242 : 16|1@1+ (1,0) [0|0] "" Vector__XXX
 SG_ DIF_a243_logId m243 : 16|4@1+ (1,0) [0|0] "" Vector__XXX
 SG_ DIF_a244_desatHighSide m244 : 16|1@1+ (1,0) [0|0] "" Vector__XXX
 SG_ DIF_a245_singleSwitchShort m245 : 16|1@1+ (1,0) [0|0] "" Vector__XXX
 SG_ DIF_a246_atSpeedDIResetCount m246 : 16|4@1+ (1,-1) [0|0] "" Vector__XXX
 SG_ DIF_a247_rotorOffsetEst m247 : 16|10@1- (0.05,0) [0|0] "" Vector__XXX
 SG_ DIF_a249_statorResistanceEst m249 : 16|11@1+ (5e-05,0) [0|0] "" Vector__XXX
 SG_ DIF_a250_voltage m250 : 16|12@1+ (0.01,0) [0|0] "" Vector__XXX
 SG_ DIF_a251_oilFlow m251 : 16|8@1+ (0.1,0) [0|0] "" Vector__XXX
 SG_ DIF_a253_voltage m253 : 16|14@1+ (0.002,0) [0|0] "" Vector__XXX
 SG_ DIF_a254_voltage m254 : 16|14@1+ (0.005,0) [0|0] "" Vector__XXX
 SG_ DIF_alertState : 15|1@1+ (1,0) [0|0] "" Vector__XXX
 SG_ DIF_alertID M : 0|8@1+ (1,0) [0|0] "" Vector__XXX

BO_ 1319 DI_alertLog: 8 Vector__XXX
 SG_ DI_a218_vdcPreControlAyDmzActive m218 : 63|1@1+ (1,0) [0|0] "" Vector__XXX
 SG_ DI_a159_passiveOverride m159 : 62|1@1+ (1,0) [0|0] "" Vector__XXX
 SG_ DI_a170_treadDepthAlertSet m170 : 62|1@1+ (1,0) [0|0] "" Vector__XXX
 SG_ DI_a213_alertReason m213 : 62|1@1+ (1,0) [0|0] "" Vector__XXX
 SG_ DI_a218_vdcPreControlYawMomentAc m218 : 62|1@1+ (1,0) [0|0] "" Vector__XXX
 SG_ DI_a199_vdcMode m199 : 61|2@1+ (1,0) [0|0] "" Vector__XXX
 SG_ DI_a053_errorType m53 : 60|3@1+ (1,0) [0|0] "" Vector__XXX
 SG_ DI_a056_errorType m56 : 60|3@1+ (1,0) [0|0] "" Vector__XXX
 SG_ DI_a059_errorType m59 : 60|3@1+ (1,0) [0|0] "" Vector__XXX
 SG_ DI_a066_errorType m66 : 60|3@1+ (1,0) [0|0] "" Vector__XXX
 SG_ DI_a199_understeerdMzActive m199 : 60|1@1+ (1,0) [0|0] "" Vector__XXX
 SG_ DI_a162_sysStateExitCondition m162 : 59|5@1+ (1,0) [0|0] "" Vector__XXX
 SG_ DI_a199_decelControlActive m199 : 59|1@1+ (1,0) [0|0] "" Vector__XXX
 SG_ DI_a112_maxTransient m112 : 58|6@1+ (0.004,0.05) [0|0] "" Vector__XXX
 SG_ DI_a162_frunkOpen m162 : 58|1@1+ (1,0) [0|0] "" Vector__XXX
 SG_ DI_a199_oversteerdMzActive m199 : 58|1@1+ (1,0) [0|0] "" Vector__XXX
 SG_ DI_a218_preControlActivationGain m218 : 58|4@1+ (0.1,0) [0|0] "" Vector__XXX
 SG_ DI_a219_oversteerYawRateError m219 : 58|6@1- (0.006,-0.18) [0|0] "" Vector__XXX
 SG_ DI_a220_understeerDecelInitThres m220 : 58|6@1+ (0.006,0) [0|0] "" Vector__XXX
 SG_ DI_a221_understeerdMzYawRateErro m221 : 58|6@1+ (0.006,0) [0|0] "" Vector__XXX
 SG_ DI_a223_surfaceUtility m223 : 58|3@1+ (15,0) [0|0] "" Vector__XXX
 SG_ DI_a248_rolloverDmzLearnDownMass m248 : 58|6@1+ (100,3000) [0|0] "" Vector__XXX
 SG_ DI_a162_chargeCableConnected m162 : 57|1@1+ (1,0) [0|0] "" Vector__XXX
 SG_ DI_a199_preControlActive m199 : 57|1@1+ (1,0) [0|0] "" Vector__XXX
 SG_ DI_a213_stickyMuTotalConfidence m213 : 57|5@1+ (0.1,0) [0|0] "" Vector__XXX
 SG_ DI_a223_regenTCActive m223 : 57|1@1+ (1,0) [0|0] "" Vector__XXX
 SG_ DI_a099_cpuUsage10ms m99 : 56|8@1+ (1,0) [0|0] "" Vector__XXX
 SG_ DI_a135_vhldGrade m135 : 56|8@1+ (0.01,-1) [0|0] "" Vector__XXX
 SG_ DI_a142_peakVehicleVelocity m142 : 56|8@1+ (0.25,0) [0|0] "" Vector__XXX
 SG_ DI_a159_targetOvershoot m159 : 56|6@1+ (0.5,0) [0|0] "" Vector__XXX
 SG_ DI_a170_distanceSinceLastTireCon m170 : 56|6@1+ (500,0) [0|0] "" Vector__XXX
 SG_ DI_a188_distanceSinceLastTireCon m188 : 56|8@1+ (500,0) [0|0] "" Vector__XXX
 SG_ DI_a223_driveTCActive m223 : 56|1@1+ (1,0) [0|0] "" Vector__XXX
 SG_ DI_a233_wheelGroundVelocity m233 : 56|8@1+ (0.25,0) [0|0] "" Vector__XXX
 SG_ DI_a100_crcFailed m100 : 55|1@1+ (1,0) [0|0] "" Vector__XXX
 SG_ DI_a100_nvramInvalidArgs m100 : 54|1@1+ (1,0) [0|0] "" Vector__XXX
 SG_ DI_a100_nvramErrorPresent m100 : 53|1@1+ (1,0) [0|0] "" Vector__XXX
 SG_ DI_a193_brakeTorqueFrRCurrVal m193 : 53|10@1+ (12,0) [0|0] "" Vector__XXX
 SG_ DI_a194_brakeTorqueReRCurrVal m194 : 53|10@1+ (12,0) [0|0] "" Vector__XXX
 SG_ DI_a195_wheelSlipFrRCurrValue m195 : 53|10@1+ (0.001,0) [0|0] "" Vector__XXX
 SG_ DI_a196_wheelSlipReRCurrValue m196 : 53|10@1+ (0.001,0) [0|0] "" Vector__XXX
 SG_ DI_a198_steeringAngleCurrVal m198 : 53|10@1- (1.6,0) [0|0] "" Vector__XXX
 SG_ DI_a204_rollRateCurrVal m204 : 53|10@1- (0.006,0) [0|0] "" Vector__XXX
 SG_ DI_a205_pitchRateCurrVal m205 : 53|10@1- (0.006,0) [0|0] "" Vector__XXX
 SG_ DI_a206_yawRateCurrVal m206 : 53|10@1- (0.006,0) [0|0] "" Vector__XXX
 SG_ DI_a207_driverTorqueCurrVal m207 : 53|10@1- (14.649,0) [0|0] "" Vector__XXX
 SG_ DI_a208_driverTorqueCurrVal m208 : 53|10@1- (14.649,0) [0|0] "" Vector__XXX
 SG_ DI_a214_wheelSpeedFrRCurrVal m214 : 53|10@1- (0.12,37.92) [0|0] "" Vector__XXX
 SG_ DI_a215_wheelSpeedReRCurrVal m215 : 53|10@1- (0.12,37.92) [0|0] "" Vector__XXX
 SG_ DI_a068_wheelSpeedDiffReR m68 : 52|12@1- (0.0625,0) [0|0] "" Vector__XXX
 SG_ DI_a074_epbSystemStatus m74 : 52|4@1+ (1,0) [0|0] "" Vector__XXX
 SG_ DI_a100_lastOperationActive m100 : 52|1@1+ (1,0) [0|0] "" Vector__XXX
 SG_ DI_a134_wheelSpeedDiffReR m134 : 52|12@1- (0.0625,0) [0|0] "" Vector__XXX
 SG_ DI_a218_vehicleVelocity m218 : 52|6@1+ (1,0) [0|0] "" Vector__XXX
 SG_ DI_a219_vehicleVelocity m219 : 52|6@1+ (1,0) [0|0] "" Vector__XXX
 SG_ DI_a220_vehicleVelocity m220 : 52|6@1+ (1,0) [0|0] "" Vector__XXX
 SG_ DI_a221_vehicleVelocity m221 : 52|6@1+ (1,0) [0|0] "" Vector__XXX
 SG_ DI_a223_musurfHigh m223 : 52|4@1+ (0.1,0) [0|0] "" Vector__XXX
 SG_ DI_a248_peakLateralJerk m248 : 52|6@1+ (1,0) [0|0] "" Vector__XXX
 SG_ DI_a084_flashEccTestFail m84 : 51|1@1+ (1,0) [0|0] "" Vector__XXX
 SG_ DI_a100_operationTimedOut m100 : 51|1@1+ (1,0) [0|0] "" Vector__XXX
 SG_ DI_a213_stickyMuTarget m213 : 51|6@1+ (0.025,0) [0|0] "" Vector__XXX
 SG_ DI_a084_postAddressTestFail m84 : 50|1@1+ (1,0) [0|0] "" Vector__XXX
 SG_ DI_a100_eraseUnlockFailurePresen m100 : 50|1@1+ (1,0) [0|0] "" Vector__XXX
 SG_ DI_a162_timeSinceCruiseCancel m162 : 50|7@1+ (0.5,0) [0|0] "" Vector__XXX
 SG_ DI_a199_sensorYawRate m199 : 50|7@1- (0.024,0) [0|0] "" Vector__XXX
 SG_ DI_a084_preAddressTestFail m84 : 49|1@1+ (1,0) [0|0] "" Vector__XXX
 SG_ DI_a100_writeUnlockFailurePresen m100 : 49|1@1+ (1,0) [0|0] "" Vector__XXX
 SG_ DI_a112_maxValue m112 : 49|9@1+ (0.0055,0.5) [0|0] "" Vector__XXX
 SG_ DI_a000_alertDataW2 m0 : 48|16@1+ (1,0) [0|0] "" Vector__XXX
 SG_ DI_a013_errorType m13 : 48|4@1+ (1,0) [0|0] "" Vector__XXX
 SG_ DI_a053_canID m53 : 48|12@1+ (1,0) [0|0] "" Vector__XXX
 SG_ DI_a055_errorType m55 : 48|1@1+ (1,0) [0|0] "" Vector__XXX
 SG_ DI_a056_canID m56 : 48|12@1+ (1,0) [0|0] "" Vector__XXX
 SG_ DI_a058_errorType m58 : 48|1@1+ (1,0) [0|0] "" Vector__XXX
 SG_ DI_a059_canID m59 : 48|12@1+ (1,0) [0|0] "" Vector__XXX
 SG_ DI_a061_errorType m61 : 48|1@1+ (1,0) [0|0] "" Vector__XXX
 SG_ DI_a066_canID m66 : 48|12@1+ (1,0) [0|0] "" Vector__XXX
 SG_ DI_a074_failureReason m74 : 48|4@1+ (1,0) [0|0] "" Vector__XXX
 SG_ DI_a084_eccCheckFail m84 : 48|1@1+ (1,0) [0|0] "" Vector__XXX
 SG_ DI_a093_errorType m93 : 48|1@1+ (1,0) [0|0] "" Vector__XXX
 SG_ DI_a094_badValue2 m94 : 48|16@1+ (1,0) [0|0] "" Vector__XXX
 SG_ DI_a098_errorCode m98 : 48|4@1+ (1,0) [0|0] "" Vector__XXX
 SG_ DI_a099_cpuUsage1kHz m99 : 48|8@1+ (1,0) [0|0] "" Vector__XXX
 SG_ DI_a100_isEraseOperation m100 : 48|1@1+ (1,0) [0|0] "" Vector__XXX
 SG_ DI_a125_minBusVoltage m125 : 48|16@1+ (0.1,0) [0|0] "" Vector__XXX
 SG_ DI_a131_warnTimeRemaining m131 : 48|16@1+ (1,0) [0|0] "" Vector__XXX
 SG_ DI_a142_peakFrontBrakeTorque m142 : 48|8@1+ (50,0) [0|0] "" Vector__XXX
 SG_ DI_a159_crsUi m159 : 48|8@1- (4,0) [0|0] "" Vector__XXX
 SG_ DI_a160_distanceSinceLastTireCon m160 : 48|12@1+ (0.01,0) [0|0] "" Vector__XXX
 SG_ DI_a172_timeSinceCruiseCancel m172 : 48|7@1+ (0.5,0) [0|0] "" Vector__XXX
 SG_ DI_a185_autoparkInternalState m185 : 48|5@1+ (1,0) [0|0] "" Vector__XXX
 SG_ DI_a188_treadWearFactorAvgConfid m188 : 48|5@1+ (0.05,0) [0|0] "" Vector__XXX
 SG_ DI_a190_treadWearFactorAvgConfid m190 : 48|5@1+ (0.05,0) [0|0] "" Vector__XXX
 SG_ DI_a191_timeSinceCruiseCancel m191 : 48|7@1+ (0.5,0) [0|0] "" Vector__XXX
 SG_ DI_a223_musurf m223 : 48|4@1+ (0.1,0) [0|0] "" Vector__XXX
 SG_ DI_a232_steerAngleValid m232 : 48|1@1+ (1,0) [0|0] "" Vector__XXX
 SG_ DI_a232_yawRateValid m232 : 47|1@1+ (1,0) [0|0] "" Vector__XXX
 SG_ DI_a162_requestSource m162 : 46|4@1+ (1,0) [0|0] "" Vector__XXX
 SG_ DI_a224_brakeRRTemp m224 : 46|10@1- (1,300) [0|0] "" Vector__XXX
 SG_ DI_a232_longitudinalAccelValid m232 : 46|1@1+ (1,0) [0|0] "" Vector__XXX
 SG_ DI_a248_vehicleVelocity m248 : 46|6@1+ (1,0) [0|0] "" Vector__XXX
 SG_ DI_a135_vhldPropulsiveTorque m135 : 45|10@1- (1,0) [0|0] "" Vector__XXX
 SG_ DI_a199_vehicleVelocity m199 : 45|5@1+ (2,0) [0|0] "" Vector__XXX
 SG_ DI_a213_stickyMu m213 : 45|6@1+ (0.025,0) [0|0] "" Vector__XXX
 SG_ DI_a232_lateralAccelValid m232 : 45|1@1+ (1,0) [0|0] "" Vector__XXX
 SG_ DI_a170_odometer m170 : 44|12@1+ (500,0) [0|0] "" Vector__XXX
 SG_ DI_a232_allMotorTorquesValid m232 : 44|1@1+ (1,0) [0|0] "" Vector__XXX
 SG_ DI_a074_unit2Gear m74 : 43|3@1+ (1,0) [0|0] "" Vector__XXX
 SG_ DI_a162_requestedGear m162 : 43|3@1+ (1,0) [0|0] "" Vector__XXX
 SG_ DI_a193_brakeTorqueFrRLastVal m193 : 43|10@1+ (12,0) [0|0] "" Vector__XXX
 SG_ DI_a194_brakeTorqueReRLastVal m194 : 43|10@1+ (12,0) [0|0] "" Vector__XXX
 SG_ DI_a195_wheelSlipFrRLastValue m195 : 43|10@1+ (0.001,0) [0|0] "" Vector__XXX
 SG_ DI_a196_wheelSlipReRLastValue m196 : 43|10@1+ (0.001,0) [0|0] "" Vector__XXX
 SG_ DI_a198_steeringAngleLastVal m198 : 43|10@1- (1.6,0) [0|0] "" Vector__XXX
 SG_ DI_a204_rollRateLastVal m204 : 43|10@1- (0.006,0) [0|0] "" Vector__XXX
 SG_ DI_a205_pitchRateLastVal m205 : 43|10@1- (0.006,0) [0|0] "" Vector__XXX
 SG_ DI_a206_yawRateLastVal m206 : 43|10@1- (0.006,0) [0|0] "" Vector__XXX
 SG_ DI_a207_driverTorqueLastVal m207 : 43|10@1- (14.649,0) [0|0] "" Vector__XXX
 SG_ DI_a208_driverTorqueLastVal m208 : 43|10@1- (14.649,0) [0|0] "" Vector__XXX
 SG_ DI_a214_wheelSpeedFrRLastVal m214 : 43|10@1- (0.12,37.92) [0|0] "" Vector__XXX
 SG_ DI_a215_wheelSpeedReRLastVal m215 : 43|10@1- (0.12,37.92) [0|0] "" Vector__XXX
 SG_ DI_a218_predictedYawRateError m218 : 43|9@1- (0.006,0) [0|0] "" Vector__XXX
 SG_ DI_a219_oversteerYawRateTar m219 : 43|9@1- (0.006,0) [0|0] "" Vector__XXX
 SG_ DI_a220_understeerDecelYawRateTa m220 : 43|9@1- (0.006,0) [0|0] "" Vector__XXX
 SG_ DI_a221_understeerdMzYawRateTar m221 : 43|9@1- (0.006,0) [0|0] "" Vector__XXX
 SG_ DI_a232_OversteerActiveValid m232 : 43|1@1+ (1,0) [0|0] "" Vector__XXX
 SG_ DI_a098_recordID m98 : 42|4@1+ (1,0) [0|0] "" Vector__XXX
 SG_ DI_a232_UndersteerActiveValid m232 : 42|1@1+ (1,0) [0|0] "" Vector__XXX
 SG_ DI_a232_AbsBrakeEventActiveValid m232 : 41|1@1+ (1,0) [0|0] "" Vector__XXX
 SG_ DI_a248_absLatAccelForHighDynami m248 : 41|5@1+ (0.5,0) [0|0] "" Vector__XXX
 SG_ DI_a065_mailboxID m65 : 40|16@1+ (1,0) [0|0] "" Vector__XXX
 SG_ DI_a068_wheelSpeedDiffReL m68 : 40|12@1- (0.0625,0) [0|0] "" Vector__XXX
 SG_ DI_a074_unit1Gear m74 : 40|3@1+ (1,0) [0|0] "" Vector__XXX
 SG_ DI_a096_word2 m96 : 40|16@1+ (1,0) [0|0] "" Vector__XXX
 SG_ DI_a097_argument m97 : 40|16@1+ (1,0) [0|0] "" Vector__XXX
 SG_ DI_a098_pageID m98 : 40|2@1+ (1,0) [0|0] "" Vector__XXX
 SG_ DI_a099_cpuUsage100Hz m99 : 40|8@1+ (1,0) [0|0] "" Vector__XXX
 SG_ DI_a112_minValue m112 : 40|9@1+ (0.0065,0) [0|0] "" Vector__XXX
 SG_ DI_a122_stackSize m122 : 40|16@1+ (1,0) [0|0] "" Vector__XXX
 SG_ DI_a134_wheelSpeedDiffReL m134 : 40|12@1- (0.0625,0) [0|0] "" Vector__XXX
 SG_ DI_a142_peakVertAccelDelta m142 : 40|8@1+ (0.08,0) [0|0] "" Vector__XXX
 SG_ DI_a159_crsUp m159 : 40|8@1- (4,0) [0|0] "" Vector__XXX
 SG_ DI_a160_wearFactorReL m160 : 40|6@1+ (0.00125,0.96) [0|0] "" Vector__XXX
 SG_ DI_a162_currentGear m162 : 40|3@1+ (1,0) [0|0] "" Vector__XXX
 SG_ DI_a163_requestSource m163 : 40|4@1+ (1,0) [0|0] "" Vector__XXX
 SG_ DI_a164_torqueDriver m164 : 40|14@1- (0.2,0) [0|0] "" Vector__XXX
 SG_ DI_a172_currentGear m172 : 40|3@1+ (1,0) [0|0] "" Vector__XXX
 SG_ DI_a185_crsFaultReason m185 : 40|5@1+ (1,0) [0|0] "" Vector__XXX
 SG_ DI_a187_systemTorqueCommand m187 : 40|16@1- (1,0) [0|0] "" Vector__XXX
 SG_ DI_a188_treadWearFactorReL m188 : 40|6@1+ (0.001,0.969) [0|0] "" Vector__XXX
 SG_ DI_a189_motorSpeed m189 : 40|5@1- (0.5,0) [0|0] "" Vector__XXX
 SG_ DI_a190_treadWearFactorReL m190 : 40|6@1+ (0.001,0.969) [0|0] "" Vector__XXX
 SG_ DI_a191_requestSource m191 : 40|4@1+ (1,0) [0|0] "" Vector__XXX
 SG_ DI_a193_brakeTorqueFrR m193 : 40|3@1+ (1,0) [0|0] "" Vector__XXX
 SG_ DI_a194_brakeTorqueReR m194 : 40|3@1+ (1,0) [0|0] "" Vector__XXX
 SG_ DI_a195_wheelSlipFrR m195 : 40|3@1+ (1,0) [0|0] "" Vector__XXX
 SG_ DI_a196_wheelSlipReR m196 : 40|3@1+ (1,0) [0|0] "" Vector__XXX
 SG_ DI_a198_steeringAngle m198 : 40|3@1+ (1,0) [0|0] "" Vector__XXX
 SG_ DI_a204_rollRate m204 : 40|3@1+ (1,0) [0|0] "" Vector__XXX
 SG_ DI_a205_pitchRate m205 : 40|3@1+ (1,0) [0|0] "" Vector__XXX
 SG_ DI_a206_yawRate m206 : 40|3@1+ (1,0) [0|0] "" Vector__XXX
 SG_ DI_a207_driverTorque m207 : 40|3@1+ (1,0) [0|0] "" Vector__XXX
 SG_ DI_a208_driverTorque m208 : 40|3@1+ (1,0) [0|0] "" Vector__XXX
 SG_ DI_a214_wheelSpeedFrR m214 : 40|3@1+ (1,0) [0|0] "" Vector__XXX
 SG_ DI_a215_wheelSpeedReR m215 : 40|3@1+ (1,0) [0|0] "" Vector__XXX
 SG_ DI_a223_vehicleVelocity m223 : 40|7@1- (1,48) [0|0] "" Vector__XXX
 SG_ DI_a232_WheelBrakeTorquesValid m232 : 40|1@1+ (1,0) [0|0] "" Vector__XXX
 SG_ DI_a233_peakLongAccelDecrease m233 : 40|9@1- (0.05,0) [0|0] "" Vector__XXX
 SG_ DI_a237_vehicleSpeed m237 : 40|6@1+ (1,0) [0|0] "" Vector__XXX
 SG_ DI_a213_learnUpMu m213 : 39|6@1+ (0.024,0) [0|0] "" Vector__XXX
 SG_ DI_a232_BrakeMasterCylPressValid m232 : 39|1@1+ (1,0) [0|0] "" Vector__XXX
 SG_ DI_a170_wearFactorReL m170 : 38|6@1+ (0.00125,0.96) [0|0] "" Vector__XXX
 SG_ DI_a199_driverIntendedYawRate m199 : 38|7@1- (0.024,0) [0|0] "" Vector__XXX
 SG_ DI_a232_allWhlSpeedRotationAvail m232 : 38|1@1+ (1,0) [0|0] "" Vector__XXX
 SG_ DI_a124_cruiseFaultStack m124 : 37|3@1+ (1,0) [0|0] "" Vector__XXX
 SG_ DI_a218_lateralAccelFilt m218 : 37|6@1- (0.5,0) [0|0] "" Vector__XXX
 SG_ DI_a219_lateralAccelFilt m219 : 37|6@1- (0.5,0) [0|0] "" Vector__XXX
 SG_ DI_a220_lateralAccelFilt m220 : 37|6@1- (0.5,0) [0|0] "" Vector__XXX
 SG_ DI_a221_lateralAccelFilt m221 : 37|6@1- (0.5,0) [0|0] "" Vector__XXX
 SG_ DI_a074_unit0Gear m74 : 36|3@1+ (1,0) [0|0] "" Vector__XXX
 SG_ DI_a144_autonomyFeatureType m144 : 36|1@1+ (1,0) [0|0] "" Vector__XXX
 SG_ DI_a191_requestedGear m191 : 36|3@1+ (1,0) [0|0] "" Vector__XXX
 SG_ DI_a224_brakeRLTemp m224 : 36|10@1- (1,300) [0|0] "" Vector__XXX
 SG_ DI_a135_vhldTotalBrakeTorque m135 : 35|10@1+ (10,0) [0|0] "" Vector__XXX
 SG_ DI_a144_chassisSubType m144 : 35|1@1+ (1,0) [0|0] "" Vector__XXX
 SG_ DI_a163_requestedGear m163 : 35|3@1+ (1,0) [0|0] "" Vector__XXX
 SG_ DI_a212_wheelRotationRe2R m212 : 35|3@1+ (1,0) [0|0] "" Vector__XXX
 SG_ DI_a232_musurfHigh m232 : 35|3@1+ (0.15,0.15) [0|0] "" Vector__XXX
 SG_ DI_a248_lateralAccelDriverIntend m248 : 35|6@1- (0.5,0) [0|0] "" Vector__XXX
 SG_ DI_a144_powerLiftgateType m144 : 34|1@1+ (1,0) [0|0] "" Vector__XXX
 SG_ DI_a213_confidenceInLowMu m213 : 34|5@1+ (0.03225806451612903,0) [0|0] "" Vector__XXX
 SG_ DI_a144_dasHw m144 : 33|1@1+ (1,0) [0|0] "" Vector__XXX
 SG_ DI_a162_pedalPos m162 : 33|7@1+ (0.8,0) [0|0] "" Vector__XXX
 SG_ DI_a191_currentGear m191 : 33|3@1+ (1,0) [0|0] "" Vector__XXX
 SG_ DI_a201_packOvervoltage m201 : 33|1@1+ (1,0) [0|0] "" Vector__XXX
 SG_ DI_a000_alertDataW1 m0 : 32|16@1+ (1,0) [0|0] "" Vector__XXX
 SG_ DI_a010_wdtFlags m10 : 32|16@1+ (1,0) [0|0] "" Vector__XXX
 SG_ DI_a012_accel2SupplyV m12 : 32|16@1+ (0.001,0) [0|0] "" Vector__XXX
 SG_ DI_a021_maxBusVoltage m21 : 32|16@1+ (0.1,0) [0|0] "" Vector__XXX
 SG_ DI_a051_packCurrent m51 : 32|16@1- (0.1,0) [0|0] "" Vector__XXX
 SG_ DI_a053_badValue2 m53 : 32|16@1+ (1,0) [0|0] "" Vector__XXX
 SG_ DI_a054_mailboxID m54 : 32|16@1+ (1,0) [0|0] "" Vector__XXX
 SG_ DI_a055_canID m55 : 32|16@1+ (1,0) [0|0] "" Vector__XXX
 SG_ DI_a056_badValue2 m56 : 32|16@1+ (1,0) [0|0] "" Vector__XXX
 SG_ DI_a057_mailboxID m57 : 32|16@1+ (1,0) [0|0] "" Vector__XXX
 SG_ DI_a058_canID m58 : 32|16@1+ (1,0) [0|0] "" Vector__XXX
 SG_ DI_a059_badValue2 m59 : 32|16@1+ (1,0) [0|0] "" Vector__XXX
 SG_ DI_a060_mailboxID m60 : 32|16@1+ (1,0) [0|0] "" Vector__XXX
 SG_ DI_a061_canID m61 : 32|16@1+ (1,0) [0|0] "" Vector__XXX
 SG_ DI_a065_errorType m65 : 32|1@1+ (1,0) [0|0] "" Vector__XXX
 SG_ DI_a066_badValue2 m66 : 32|16@1+ (1,0) [0|0] "" Vector__XXX
 SG_ DI_a067_mailboxID m67 : 32|16@1+ (1,0) [0|0] "" Vector__XXX
 SG_ DI_a074_attemptCount m74 : 32|4@1+ (1,0) [0|0] "" Vector__XXX
 SG_ DI_a080_track2Voltage m80 : 32|16@1+ (0.001,0) [0|0] "" Vector__XXX
 SG_ DI_a081_track2Voltage m81 : 32|16@1+ (0.001,0) [0|0] "" Vector__XXX
 SG_ DI_a082_track2Voltage m82 : 32|16@1+ (0.001,0) [0|0] "" Vector__XXX
 SG_ DI_a093_canID m93 : 32|16@1+ (1,0) [0|0] "" Vector__XXX
 SG_ DI_a094_badValue1 m94 : 32|16@1+ (1,0) [0|0] "" Vector__XXX
 SG_ DI_a095_canID m95 : 32|16@1+ (1,0) [0|0] "" Vector__XXX
 SG_ DI_a098_page2Counter m98 : 32|8@1+ (1,0) [0|0] "" Vector__XXX
 SG_ DI_a099_cpuUsage10Hz m99 : 32|8@1+ (1,0) [0|0] "" Vector__XXX
 SG_ DI_a124_cruiseFaultReason m124 : 32|5@1+ (1,0) [0|0] "" Vector__XXX
 SG_ DI_a125_maxChargeCurrent m125 : 32|16@1- (0.1,0) [0|0] "" Vector__XXX
 SG_ DI_a131_warnSpeedLimit m131 : 32|16@1+ (1,0) [0|0] "" Vector__XXX
 SG_ DI_a142_peakLongAccelDelta m142 : 32|8@1+ (0.08,0) [0|0] "" Vector__XXX
 SG_ DI_a144_brakeActuationType m144 : 32|1@1+ (1,0) [0|0] "" Vector__XXX
 SG_ DI_a159_targetAccel m159 : 32|8@1+ (0.075,-10) [0|0] "" Vector__XXX
 SG_ DI_a160_wearFactorFrR m160 : 32|6@1+ (0.00125,0.96) [0|0] "" Vector__XXX
 SG_ DI_a163_currentGear m163 : 32|3@1+ (1,0) [0|0] "" Vector__XXX
 SG_ DI_a164_pedalPos m164 : 32|8@1+ (0.4,0) [0|0] "" Vector__XXX
 SG_ DI_a170_wearFactorFrR m170 : 32|6@1+ (0.00125,0.96) [0|0] "" Vector__XXX
 SG_ DI_a172_pedalPos m172 : 32|8@1+ (0.4,0) [0|0] "" Vector__XXX
 SG_ DI_a173_pedalPos m173 : 32|8@1+ (0.4,0) [0|0] "" Vector__XXX
 SG_ DI_a184_autoparkInternalState m184 : 32|5@1+ (1,0) [0|0] "" Vector__XXX
 SG_ DI_a185_crsNotAvailableReason m185 : 32|6@1+ (1,0) [0|0] "" Vector__XXX
 SG_ DI_a187_rawPedal m187 : 32|8@1+ (0.4,0) [0|0] "" Vector__XXX
 SG_ DI_a188_treadWearFactorFrR m188 : 32|6@1+ (0.001,0.969) [0|0] "" Vector__XXX
 SG_ DI_a189_systemTorque m189 : 32|8@1- (10,0) [0|0] "" Vector__XXX
 SG_ DI_a190_treadWearFactorFrR m190 : 32|6@1+ (0.001,0.969) [0|0] "" Vector__XXX
 SG_ DI_a191_reverseDeniedAfterCruise m191 : 32|1@1+ (1,0) [0|0] "" Vector__XXX
 SG_ DI_a199_lateralAccelFilt m199 : 32|6@1- (0.5,0) [0|0] "" Vector__XXX
 SG_ DI_a201_dragTorqueControlOff m201 : 32|1@1+ (1,0) [0|0] "" Vector__XXX
 SG_ DI_a202_sysStateExitCondition m202 : 32|5@1+ (1,0) [0|0] "" Vector__XXX
 SG_ DI_a212_wheelRotationRe2L m212 : 32|3@1+ (1,0) [0|0] "" Vector__XXX
 SG_ DI_a223_UI_tractionControlMode m223 : 32|3@1+ (1,0) [0|0] "" Vector__XXX
 SG_ DI_a232_musurf m232 : 32|3@1+ (0.15,0.15) [0|0] "" Vector__XXX
 SG_ DI_a233_peakPositiveSlip m233 : 32|8@1+ (0.005,0) [0|0] "" Vector__XXX
 SG_ DI_a237_longitudinalAccel m237 : 32|8@1- (0.25,0) [0|0] "" Vector__XXX
 SG_ DI_a242_massEstimate m242 : 32|8@1+ (25,1500) [0|0] "" Vector__XXX
 SG_ DI_a253_track2Voltage m253 : 32|16@1+ (0.001,0) [0|0] "" Vector__XXX
 SG_ DI_a144_softPerformanceLimit m144 : 31|1@1+ (1,0) [0|0] "" Vector__XXX
 SG_ DI_a162_autonomyBehavior m162 : 31|2@1+ (1,0) [0|0] "" Vector__XXX
 SG_ DI_a144_heatsinkType m144 : 30|1@1+ (1,0) [0|0] "" Vector__XXX
 SG_ DI_a162_essContClosed m162 : 30|1@1+ (1,0) [0|0] "" Vector__XXX
 SG_ DI_a218_bankAngle m218 : 30|7@1- (0.008,0) [0|0] "" Vector__XXX
 SG_ DI_a219_bankAngle m219 : 30|7@1- (0.008,0) [0|0] "" Vector__XXX
 SG_ DI_a220_bankAngle m220 : 30|7@1- (0.008,0) [0|0] "" Vector__XXX
 SG_ DI_a221_bankAngle m221 : 30|7@1- (0.008,0) [0|0] "" Vector__XXX
 SG_ DI_a010_ovfNmi m10 : 29|1@1+ (1,0) [0|0] "" Vector__XXX
 SG_ DI_a144_oilPump2HwType m144 : 29|1@1+ (1,0) [0|0] "" Vector__XXX
 SG_ DI_a193_brakeTorqueFrLCurrVal m193 : 29|10@1+ (12,0) [0|0] "" Vector__XXX
 SG_ DI_a194_brakeTorqueReLCurrVal m194 : 29|10@1+ (12,0) [0|0] "" Vector__XXX
 SG_ DI_a195_wheelSlipFrLCurrValue m195 : 29|10@1+ (0.001,0) [0|0] "" Vector__XXX
 SG_ DI_a196_wheelSlipReLCurrValue m196 : 29|10@1+ (0.001,0) [0|0] "" Vector__XXX
 SG_ DI_a198_MCPressCurrValue m198 : 29|10@1- (0.3,123.6) [0|0] "" Vector__XXX
 SG_ DI_a204_longAccelCurrVal m204 : 29|10@1- (0.08,0) [0|0] "" Vector__XXX
 SG_ DI_a205_latAccelCurrVal m205 : 29|10@1- (0.08,0) [0|0] "" Vector__XXX
 SG_ DI_a206_verticalAccelCurrVal m206 : 29|10@1- (0.08,0) [0|0] "" Vector__XXX
 SG_ DI_a207_motorTorqueCurrVal m207 : 29|10@1- (14.649,0) [0|0] "" Vector__XXX
 SG_ DI_a208_motorTorqueCurrVal m208 : 29|10@1- (14.649,0) [0|0] "" Vector__XXX
 SG_ DI_a211_motorSpeedLastVal m211 : 29|10@1- (0.11,35.09) [0|0] "" Vector__XXX
 SG_ DI_a213_scaledLowMuProbability m213 : 29|5@1+ (0.03225806451612903,0) [0|0] "" Vector__XXX
 SG_ DI_a214_wheelSpeedFrLCurrVal m214 : 29|10@1- (0.12,37.92) [0|0] "" Vector__XXX
 SG_ DI_a215_wheelSpeedReLCurrVal m215 : 29|10@1- (0.12,37.92) [0|0] "" Vector__XXX
 SG_ DI_a241_motorSpeedLastVal m241 : 29|10@1- (0.11,35.09) [0|0] "" Vector__XXX
 SG_ DI_a248_lateralAccel2HzFilt m248 : 29|6@1- (0.5,0) [0|0] "" Vector__XXX
 SG_ DI_a010_rlNmi m10 : 28|1@1+ (1,0) [0|0] "" Vector__XXX
 SG_ DI_a068_wheelSpeedDiffFrR m68 : 28|12@1- (0.0625,0) [0|0] "" Vector__XXX
 SG_ DI_a094_errorType m94 : 28|3@1+ (1,0) [0|0] "" Vector__XXX
 SG_ DI_a112_eventDurationMs m112 : 28|12@1+ (1,0) [0|0] "" Vector__XXX
 SG_ DI_a134_wheelSpeedDiffFrR m134 : 28|12@1- (0.0625,0) [0|0] "" Vector__XXX
 SG_ DI_a144_oilPump1HwType m144 : 28|1@1+ (1,0) [0|0] "" Vector__XXX
 SG_ DI_a154_rearSteeringAngleCurrVal m154 : 28|9@1- (0.04,0) [0|0] "" Vector__XXX
 SG_ DI_a189_brakePressed m189 : 28|1@1+ (1,0) [0|0] "" Vector__XXX
 SG_ DI_a223_DI_tractionControlMode m223 : 28|3@1+ (1,0) [0|0] "" Vector__XXX
 SG_ DI_a010_sysDbgNmi m10 : 27|1@1+ (1,0) [0|0] "" Vector__XXX
 SG_ DI_a144_platformMaxBusVoltage m144 : 27|1@1+ (1,0) [0|0] "" Vector__XXX
 SG_ DI_a155_liftgateStatus m155 : 27|1@1+ (1,0) [0|0] "" Vector__XXX
 SG_ DI_a197_wheelSaturationReR m197 : 27|3@1+ (1,0) [0|0] "" Vector__XXX
 SG_ DI_a212_wheelRotationReR m212 : 27|3@1+ (1,0) [0|0] "" Vector__XXX
 SG_ DI_a010_pieVectErrorNmi m10 : 26|1@1+ (1,0) [0|0] "" Vector__XXX
 SG_ DI_a092_bmsSystemStatus m92 : 26|1@1+ (1,0) [0|0] "" Vector__XXX
 SG_ DI_a130_aebBrakeTorqueCommand m130 : 26|13@1+ (3,0) [0|0] "" Vector__XXX
 SG_ DI_a144_frunkLatchType m144 : 26|1@1+ (1,0) [0|0] "" Vector__XXX
 SG_ DI_a160_wearFactorFrL m160 : 26|6@1+ (0.00125,0.96) [0|0] "" Vector__XXX
 SG_ DI_a170_wearFactorFrL m170 : 26|6@1+ (0.00125,0.96) [0|0] "" Vector__XXX
 SG_ DI_a199_bankAngle m199 : 26|6@1- (0.016,0) [0|0] "" Vector__XXX
 SG_ DI_a223_addState_dif m223 : 26|2@1+ (1,0) [0|0] "" Vector__XXX
 SG_ DI_a224_brakeFRTemp m224 : 26|10@1- (1,300) [0|0] "" Vector__XXX
 SG_ DI_a244_massEstimateRLS m244 : 26|10@1+ (10,1500) [0|0] "" Vector__XXX
 SG_ DI_a254_vxFromFx m254 : 26|10@1+ (0.05,0) [0|0] "" Vector__XXX
 SG_ DI_a010_cpu2signMismatchNmi m10 : 25|1@1+ (1,0) [0|0] "" Vector__XXX
 SG_ DI_a024_currentGear m24 : 25|3@1+ (1,0) [0|0] "" Vector__XXX
 SG_ DI_a088_uiDriveSystemsDebug m88 : 25|1@1+ (1,0) [0|0] "" Vector__XXX
 SG_ DI_a092_bmsPackConfig m92 : 25|1@1+ (1,0) [0|0] "" Vector__XXX
 SG_ DI_a135_vhldBrakeTorqueCommand m135 : 25|10@1+ (10,0) [0|0] "" Vector__XXX
 SG_ DI_a144_cabinPTCHeaterType m144 : 25|1@1+ (1,0) [0|0] "" Vector__XXX
 SG_ DI_a155_systemStatus m155 : 25|1@1+ (1,0) [0|0] "" Vector__XXX
 SG_ DI_a010_cpu1signMismatchNmi m10 : 24|1@1+ (1,0) [0|0] "" Vector__XXX
 SG_ DI_a024_brakePressed m24 : 24|1@1+ (1,0) [0|0] "" Vector__XXX
 SG_ DI_a026_vehicleSpeed m26 : 24|12@1+ (0.08,-40) [0|0] "" Vector__XXX
 SG_ DI_a048_triggerEvent m48 : 24|6@1+ (1,0) [0|0] "" Vector__XXX
 SG_ DI_a064_vehicleSpeed m64 : 24|12@1+ (0.08,-40) [0|0] "" Vector__XXX
 SG_ DI_a078_adcRefLowAvg m78 : 24|16@1+ (1,0) [0|0] "" Vector__XXX
 SG_ DI_a079_adcRefHighAvg m79 : 24|16@1+ (1,0) [0|0] "" Vector__XXX
 SG_ DI_a088_semiControls m88 : 24|1@1+ (1,0) [0|0] "" Vector__XXX
 SG_ DI_a092_bmsVoltageRegGain m92 : 24|1@1+ (1,0) [0|0] "" Vector__XXX
 SG_ DI_a096_word1 m96 : 24|16@1+ (1,0) [0|0] "" Vector__XXX
 SG_ DI_a097_lineNumber m97 : 24|16@1+ (1,0) [0|0] "" Vector__XXX
 SG_ DI_a098_page1Counter m98 : 24|8@1+ (1,0) [0|0] "" Vector__XXX
 SG_ DI_a099_cpuUsage1Hz m99 : 24|8@1+ (1,0) [0|0] "" Vector__XXX
 SG_ DI_a122_stackUsed m122 : 24|16@1+ (1,0) [0|0] "" Vector__XXX
 SG_ DI_a130_dasAebEvent m130 : 24|2@1+ (1,0) [0|0] "" Vector__XXX
 SG_ DI_a133_vhldGrade m133 : 24|8@1+ (0.01,-1) [0|0] "" Vector__XXX
 SG_ DI_a135_vhldBrakeApply m135 : 24|1@1+ (1,0) [0|0] "" Vector__XXX
 SG_ DI_a141_DAS_redundantBrakingCont m141 : 24|1@1+ (1,0) [0|0] "" Vector__XXX
 SG_ DI_a142_minimumPositiveSlipRatio m142 : 24|8@1+ (0.01,0) [0|0] "" Vector__XXX
 SG_ DI_a144_inverterHardware m144 : 24|1@1+ (1,0) [0|0] "" Vector__XXX
 SG_ DI_a155_restraintStatus m155 : 24|1@1+ (1,0) [0|0] "" Vector__XXX
 SG_ DI_a159_targetSpeed m159 : 24|8@1+ (0.5,0) [0|0] "" Vector__XXX
 SG_ DI_a160_tireFitment m160 : 24|2@1+ (1,0) [0|0] "" Vector__XXX
 SG_ DI_a170_tireFitment m170 : 24|2@1+ (1,0) [0|0] "" Vector__XXX
 SG_ DI_a175_crsNotAvailableStack m175 : 24|3@1+ (1,0) [0|0] "" Vector__XXX
 SG_ DI_a184_apcUnavailableReason m184 : 24|4@1+ (1,0) [0|0] "" Vector__XXX
 SG_ DI_a185_apcUnavailableReason m185 : 24|4@1+ (1,0) [0|0] "" Vector__XXX
 SG_ DI_a188_treadWearFactorFrL m188 : 24|6@1+ (0.001,0.969) [0|0] "" Vector__XXX
 SG_ DI_a189_grade m189 : 24|4@1- (4,0) [0|0] "" Vector__XXX
 SG_ DI_a190_treadWearFactorFrL m190 : 24|6@1+ (0.001,0.969) [0|0] "" Vector__XXX
 SG_ DI_a197_wheelSaturationReL m197 : 24|3@1+ (1,0) [0|0] "" Vector__XXX
 SG_ DI_a200_MBPFaultProbability m200 : 24|10@1+ (0.008,0) [0|0] "" Vector__XXX
 SG_ DI_a212_wheelRotationReL m212 : 24|3@1+ (1,0) [0|0] "" Vector__XXX
 SG_ DI_a213_rawLowMuProbability m213 : 24|5@1+ (0.03225806451612903,0) [0|0] "" Vector__XXX
 SG_ DI_a216_MBPFaultProbability m216 : 24|10@1+ (0.008,0) [0|0] "" Vector__XXX
 SG_ DI_a218_muVehicleDecFilt m218 : 24|6@1+ (0.025,0) [0|0] "" Vector__XXX
 SG_ DI_a219_muVehicleDecFilt m219 : 24|6@1+ (0.025,0) [0|0] "" Vector__XXX
 SG_ DI_a220_muVehicleDecFilt m220 : 24|6@1+ (0.025,0) [0|0] "" Vector__XXX
 SG_ DI_a221_muVehicleDecFilt m221 : 24|6@1+ (0.025,0) [0|0] "" Vector__XXX
 SG_ DI_a223_addState_dir m223 : 24|2@1+ (1,0) [0|0] "" Vector__XXX
 SG_ DI_a226_trunkOpen m226 : 24|1@1+ (1,0) [0|0] "" Vector__XXX
 SG_ DI_a232_vehicleVelocity m232 : 24|6@1+ (1,0) [0|0] "" Vector__XXX
 SG_ DI_a233_peakNegativeSlip m233 : 24|8@1+ (0.005,-1) [0|0] "" Vector__XXX
 SG_ DI_a237_verticalAccel m237 : 24|8@1- (0.25,0) [0|0] "" Vector__XXX
 SG_ DI_a242_vehicleVelocity m242 : 24|6@1+ (1,0) [0|0] "" Vector__XXX
 SG_ DI_a246_opdUnavailableReason m246 : 24|5@1+ (1,0) [0|0] "" Vector__XXX
 SG_ DI_a248_bankAngle m248 : 24|5@1- (0.05,0) [0|0] "" Vector__XXX
 SG_ DI_a010_flashUncErrorNmi m10 : 23|1@1+ (1,0) [0|0] "" Vector__XXX
 SG_ DI_a088_vehicleControl2 m88 : 23|1@1+ (1,0) [0|0] "" Vector__XXX
 SG_ DI_a091_ESP_redundantBrakingStat m91 : 23|1@1+ (1,0) [0|0] "" Vector__XXX
 SG_ DI_a092_bmsCtrStatus m92 : 23|1@1+ (1,0) [0|0] "" Vector__XXX
 SG_ DI_a141_DAS_autonomyControl m141 : 23|1@1+ (1,0) [0|0] "" Vector__XXX
 SG_ DI_a144_brakeHWType m144 : 23|1@1+ (1,0) [0|0] "" Vector__XXX
 SG_ DI_a155_vcleftSwitchStatus m155 : 23|1@1+ (1,0) [0|0] "" Vector__XXX
 SG_ DI_a226_falconDoorOpen m226 : 23|1@1+ (1,0) [0|0] "" Vector__XXX
 SG_ DI_a010_ramUncErrorNmi m10 : 22|1@1+ (1,0) [0|0] "" Vector__XXX
 SG_ DI_a040_temperature m40 : 22|1@1+ (1,0) [0|0] "" Vector__XXX
 SG_ DI_a052_temperature m52 : 22|1@1+ (1,0) [0|0] "" Vector__XXX
 SG_ DI_a088_mcuDriverLimits m88 : 22|1@1+ (1,0) [0|0] "" Vector__XXX
 SG_ DI_a091_ESP_party3 m91 : 22|1@1+ (1,0) [0|0] "" Vector__XXX
 SG_ DI_a092_bmsThermalStatus m92 : 22|1@1+ (1,0) [0|0] "" Vector__XXX
 SG_ DI_a141_DAS_longControlTuningPar m141 : 22|1@1+ (1,0) [0|0] "" Vector__XXX
 SG_ DI_a144_vdcType m144 : 22|1@1+ (1,0) [0|0] "" Vector__XXX
 SG_ DI_a155_rightDoorStatus m155 : 22|1@1+ (1,0) [0|0] "" Vector__XXX
 SG_ DI_a226_proxDetected m226 : 22|1@1+ (1,0) [0|0] "" Vector__XXX
 SG_ DI_a010_clockFailNmi m10 : 21|1@1+ (1,0) [0|0] "" Vector__XXX
 SG_ DI_a040_hvStatus m40 : 21|1@1+ (1,0) [0|0] "" Vector__XXX
 SG_ DI_a052_hvStatus m52 : 21|1@1+ (1,0) [0|0] "" Vector__XXX
 SG_ DI_a088_uiTrackModeSettings m88 : 21|1@1+ (1,0) [0|0] "" Vector__XXX
 SG_ DI_a090_state4 m90 : 21|1@1+ (1,0) [0|0] "" Vector__XXX
 SG_ DI_a091_ESP_status m91 : 21|1@1+ (1,0) [0|0] "" Vector__XXX
 SG_ DI_a092_bmsSocStatus m92 : 21|1@1+ (1,0) [0|0] "" Vector__XXX
 SG_ DI_a096_boot_flash m96 : 21|1@1+ (1,0) [0|0] "" Vector__XXX
 SG_ DI_a141_DAS_longControl m141 : 21|1@1+ (1,0) [0|0] "" Vector__XXX
 SG_ DI_a144_performancePackage m144 : 21|1@1+ (1,0) [0|0] "" Vector__XXX
 SG_ DI_a155_leftDoorStatus m155 : 21|1@1+ (1,0) [0|0] "" Vector__XXX
 SG_ DI_a199_muVehicleDecFilt m199 : 21|5@1+ (0.05,0) [0|0] "" Vector__XXX
 SG_ DI_a210_secondaryBrakeActuatorIs m210 : 21|1@1+ (1,0) [0|0] "" Vector__XXX
 SG_ DI_a226_frunkNotLatched m226 : 21|1@1+ (1,0) [0|0] "" Vector__XXX
 SG_ DI_a005_stalkEvents m5 : 20|4@1+ (1,0) [0|0] "" Vector__XXX
 SG_ DI_a010_watchdog m10 : 20|1@1+ (1,0) [0|0] "" Vector__XXX
 SG_ DI_a036_numAvailableUnits m36 : 20|4@1+ (1,0) [0|0] "" Vector__XXX
 SG_ DI_a040_capability2 m40 : 20|1@1+ (1,0) [0|0] "" Vector__XXX
 SG_ DI_a052_capability2 m52 : 20|1@1+ (1,0) [0|0] "" Vector__XXX
 SG_ DI_a087_carState m87 : 20|1@1+ (1,0) [0|0] "" Vector__XXX
 SG_ DI_a088_uiVehicleModes m88 : 20|1@1+ (1,0) [0|0] "" Vector__XXX
 SG_ DI_a090_state2 m90 : 20|1@1+ (1,0) [0|0] "" Vector__XXX
 SG_ DI_a091_ESP_offsets m91 : 20|1@1+ (1,0) [0|0] "" Vector__XXX
 SG_ DI_a092_bmsBmbMinMax m92 : 20|1@1+ (1,0) [0|0] "" Vector__XXX
 SG_ DI_a096_mem_regs m96 : 20|1@1+ (1,0) [0|0] "" Vector__XXX
 SG_ DI_a099_thread1kHz m99 : 20|1@1+ (1,0) [0|0] "" Vector__XXX
 SG_ DI_a130_aebSmState m130 : 20|3@1+ (1,0) [0|0] "" Vector__XXX
 SG_ DI_a133_reverseGear m133 : 20|1@1+ (1,0) [0|0] "" Vector__XXX
 SG_ DI_a135_vhldSmState m135 : 20|4@1+ (1,0) [0|0] "" Vector__XXX
 SG_ DI_a141_DAS_smartShift m141 : 20|1@1+ (1,0) [0|0] "" Vector__XXX
 SG_ DI_a144_packPerformanceDeviation m144 : 20|1@1+ (1,0) [0|0] "" Vector__XXX
 SG_ DI_a155_status m155 : 20|1@1+ (1,0) [0|0] "" Vector__XXX
 SG_ DI_a162_motorSpeed m162 : 20|10@1- (0.2,0) [0|0] "" Vector__XXX
 SG_ DI_a165_crsCancelStack m165 : 20|3@1+ (1,0) [0|0] "" Vector__XXX
 SG_ DI_a202_movement m202 : 20|9@1+ (0.005,0) [0|0] "" Vector__XXX
 SG_ DI_a210_brakeTmpEstStateFaulted m210 : 20|1@1+ (1,0) [0|0] "" Vector__XXX
 SG_ DI_a223_velocityEstimatorState m223 : 20|3@1+ (1,0) [0|0] "" Vector__XXX
 SG_ DI_a226_hvStateNotUpForDrive m226 : 20|1@1+ (1,0) [0|0] "" Vector__XXX
 SG_ DI_a010_nmiWatchdog m10 : 19|1@1+ (1,0) [0|0] "" Vector__XXX
 SG_ DI_a040_status m40 : 19|1@1+ (1,0) [0|0] "" Vector__XXX
 SG_ DI_a052_status m52 : 19|1@1+ (1,0) [0|0] "" Vector__XXX
 SG_ DI_a064_vehiclePowerState m64 : 19|2@1+ (1,0) [0|0] "" Vector__XXX
 SG_ DI_a074_vehicleSpeed m74 : 19|12@1+ (0.08,-40) [0|0] "" Vector__XXX
 SG_ DI_a083_brakeSwitchIrrationalNC m83 : 19|1@1+ (1,0) [0|0] "" Vector__XXX
 SG_ DI_a087_gearControl m87 : 19|1@1+ (1,0) [0|0] "" Vector__XXX
 SG_ DI_a088_uiPowertrainControl m88 : 19|1@1+ (1,0) [0|0] "" Vector__XXX
 SG_ DI_a090_locState m90 : 19|1@1+ (1,0) [0|0] "" Vector__XXX
 SG_ DI_a091_ESP_motorLimits m91 : 19|1@1+ (1,0) [0|0] "" Vector__XXX
 SG_ DI_a092_bmsPowerAvailable m92 : 19|1@1+ (1,0) [0|0] "" Vector__XXX
 SG_ DI_a096_mem_data m96 : 19|1@1+ (1,0) [0|0] "" Vector__XXX
 SG_ DI_a099_thread100Hz m99 : 19|1@1+ (1,0) [0|0] "" Vector__XXX
 SG_ DI_a110_EPBR_autonomyHealth m110 : 19|1@1+ (1,0) [0|0] "" Vector__XXX
 SG_ DI_a141_DAS_status2 m141 : 19|1@1+ (1,0) [0|0] "" Vector__XXX
 SG_ DI_a144_packEnergy m144 : 19|1@1+ (1,0) [0|0] "" Vector__XXX
 SG_ DI_a154_rearSteeringAngleLastVal m154 : 19|9@1- (0.04,0) [0|0] "" Vector__XXX
 SG_ DI_a155_vehicleStatus m155 : 19|1@1+ (1,0) [0|0] "" Vector__XXX
 SG_ DI_a193_brakeTorqueFrLLastVal m193 : 19|10@1+ (12,0) [0|0] "" Vector__XXX
 SG_ DI_a194_brakeTorqueReLLastVal m194 : 19|10@1+ (12,0) [0|0] "" Vector__XXX
 SG_ DI_a195_wheelSlipFrLLastValue m195 : 19|10@1+ (0.001,0) [0|0] "" Vector__XXX
 SG_ DI_a196_wheelSlipReLLastValue m196 : 19|10@1+ (0.001,0) [0|0] "" Vector__XXX
 SG_ DI_a197_wheelSaturationFrR m197 : 19|3@1+ (1,0) [0|0] "" Vector__XXX
 SG_ DI_a198_MCPressureLastValue m198 : 19|10@1- (0.3,123.6) [0|0] "" Vector__XXX
 SG_ DI_a203_btcState m203 : 19|1@1+ (1,0) [0|0] "" Vector__XXX
 SG_ DI_a204_longAccelLastVal m204 : 19|10@1- (0.08,0) [0|0] "" Vector__XXX
 SG_ DI_a205_latAccelLastVal m205 : 19|10@1- (0.08,0) [0|0] "" Vector__XXX
 SG_ DI_a206_verticalAccelLastVal m206 : 19|10@1- (0.08,0) [0|0] "" Vector__XXX
 SG_ DI_a207_motorTorqueLastVal m207 : 19|10@1- (14.649,0) [0|0] "" Vector__XXX
 SG_ DI_a208_motorTorqueLastVal m208 : 19|10@1- (14.649,0) [0|0] "" Vector__XXX
 SG_ DI_a211_motorSpeedCurrVal m211 : 19|10@1- (0.11,35.09) [0|0] "" Vector__XXX
 SG_ DI_a212_wheelRotationFrR m212 : 19|3@1+ (1,0) [0|0] "" Vector__XXX
 SG_ DI_a214_wheelSpeedFrLLastVal m214 : 19|10@1- (0.12,37.92) [0|0] "" Vector__XXX
 SG_ DI_a215_wheelSpeedReLLastVal m215 : 19|10@1- (0.12,37.92) [0|0] "" Vector__XXX
 SG_ DI_a223_btcState m223 : 19|1@1+ (1,0) [0|0] "" Vector__XXX
 SG_ DI_a227_vehiclePowerState m227 : 19|2@1+ (1,0) [0|0] "" Vector__XXX
 SG_ DI_a232_UI_tractionControlMode m232 : 19|3@1+ (1,0) [0|0] "" Vector__XXX
 SG_ DI_a241_motorSpeedCurrVal m241 : 19|10@1- (0.11,35.09) [0|0] "" Vector__XXX
 SG_ DI_a010_hwBist m10 : 18|1@1+ (1,0) [0|0] "" Vector__XXX
 SG_ DI_a025_bfillUnavailableReason m25 : 18|5@1+ (1,0) [0|0] "" Vector__XXX
 SG_ DI_a040_power m40 : 18|1@1+ (1,0) [0|0] "" Vector__XXX
 SG_ DI_a052_power m52 : 18|1@1+ (1,0) [0|0] "" Vector__XXX
 SG_ DI_a083_brakeSwitchIrrationalNO m83 : 18|1@1+ (1,0) [0|0] "" Vector__XXX
 SG_ DI_a087_gtwUpdateStatus m87 : 18|1@1+ (1,0) [0|0] "" Vector__XXX
 SG_ DI_a088_uiDriverAssistMapData m88 : 18|1@1+ (1,0) [0|0] "" Vector__XXX
 SG_ DI_a090_state m90 : 18|1@1+ (1,0) [0|0] "" Vector__XXX
 SG_ DI_a091_ESP_wheelRotation m91 : 18|1@1+ (1,0) [0|0] "" Vector__XXX
 SG_ DI_a092_bmsHvBusStatus m92 : 18|1@1+ (1,0) [0|0] "" Vector__XXX
 SG_ DI_a096_text_flash m96 : 18|1@1+ (1,0) [0|0] "" Vector__XXX
 SG_ DI_a099_thread10Hz m99 : 18|1@1+ (1,0) [0|0] "" Vector__XXX
 SG_ DI_a110_EPBL_autonomyHealth m110 : 18|1@1+ (1,0) [0|0] "" Vector__XXX
 SG_ DI_a141_DAS_status m141 : 18|1@1+ (1,0) [0|0] "" Vector__XXX
 SG_ DI_a144_drivetrainType m144 : 18|1@1+ (1,0) [0|0] "" Vector__XXX
 SG_ DI_a155_LVPowerState m155 : 18|1@1+ (1,0) [0|0] "" Vector__XXX
 SG_ DI_a158_BUS2_IBST_status m158 : 18|1@1+ (1,0) [0|0] "" Vector__XXX
 SG_ DI_a210_espActuatorState m210 : 18|2@1+ (1,0) [0|0] "" Vector__XXX
 SG_ DI_a213_currentState m213 : 18|2@1+ (1,0) [0|0] "" Vector__XXX
 SG_ DI_a218_muVehicleLearnDown m218 : 18|6@1+ (0.025,0) [0|0] "" Vector__XXX
 SG_ DI_a219_muVehicleLearnDown m219 : 18|6@1+ (0.025,0) [0|0] "" Vector__XXX
 SG_ DI_a220_muVehicleLearnDown m220 : 18|6@1+ (0.025,0) [0|0] "" Vector__XXX
 SG_ DI_a221_muVehicleLearnDown m221 : 18|6@1+ (0.025,0) [0|0] "" Vector__XXX
 SG_ DI_a228_ambientTempFaulted m228 : 18|1@1+ (1,0) [0|0] "" Vector__XXX
 SG_ DI_a245_vehicleHoldState m245 : 18|3@1+ (1,0) [0|0] "" Vector__XXX
 SG_ DI_a248_muVehicleLearnDown m248 : 18|6@1+ (0.025,0) [0|0] "" Vector__XXX
 SG_ DI_a010_hibernate m10 : 17|1@1+ (1,0) [0|0] "" Vector__XXX
 SG_ DI_a040_capability m40 : 17|1@1+ (1,0) [0|0] "" Vector__XXX
 SG_ DI_a052_capability m52 : 17|1@1+ (1,0) [0|0] "" Vector__XXX
 SG_ DI_a083_brakeSwitchNC m83 : 17|1@1+ (1,0) [0|0] "" Vector__XXX
 SG_ DI_a087_gtwTime m87 : 17|1@1+ (1,0) [0|0] "" Vector__XXX
 SG_ DI_a088_uiCruiseControl m88 : 17|1@1+ (1,0) [0|0] "" Vector__XXX
 SG_ DI_a091_ESP_wheelSpeeds m91 : 17|1@1+ (1,0) [0|0] "" Vector__XXX
 SG_ DI_a092_bmsDriveLimits m92 : 17|1@1+ (1,0) [0|0] "" Vector__XXX
 SG_ DI_a096_text_fast m96 : 17|1@1+ (1,0) [0|0] "" Vector__XXX
 SG_ DI_a099_thread1Hz m99 : 17|1@1+ (1,0) [0|0] "" Vector__XXX
 SG_ DI_a108_APP_status m108 : 17|1@1+ (1,0) [0|0] "" Vector__XXX
 SG_ DI_a110_EPBR_status m110 : 17|1@1+ (1,0) [0|0] "" Vector__XXX
 SG_ DI_a141_DAS_pmmControl m141 : 17|1@1+ (1,0) [0|0] "" Vector__XXX
 SG_ DI_a143_systemTorqueLimit m143 : 17|1@1+ (1,0) [0|0] "" Vector__XXX
 SG_ DI_a144_chassisType m144 : 17|1@1+ (1,0) [0|0] "" Vector__XXX
 SG_ DI_a155_coolant m155 : 17|1@1+ (1,0) [0|0] "" Vector__XXX
 SG_ DI_a157_RCM_inertial2 m157 : 17|1@1+ (1,0) [0|0] "" Vector__XXX
 SG_ DI_a158_BUS1_IBST_status m158 : 17|1@1+ (1,0) [0|0] "" Vector__XXX
 SG_ DI_a161_EPAS3P_angleCalib m161 : 17|1@1+ (1,0) [0|0] "" Vector__XXX
 SG_ DI_a170_kTire m170 : 17|7@1+ (0.001,0.008) [0|0] "" Vector__XXX
 SG_ DI_a185_apcCancelReason m185 : 17|5@1+ (1,0) [0|0] "" Vector__XXX
 SG_ DI_a200_MBPFailedCase m200 : 17|6@1+ (1,0) [0|0] "" Vector__XXX
 SG_ DI_a216_MBPFailedCase m216 : 17|6@1+ (1,0) [0|0] "" Vector__XXX
 SG_ DI_a228_faulted m228 : 17|1@1+ (1,0) [0|0] "" Vector__XXX
 SG_ DI_a230_CMPD_state m230 : 17|1@1+ (1,0) [0|0] "" Vector__XXX
 SG_ DI_a249_learning_DIR m249 : 17|1@1+ (1,0) [0|0] "" Vector__XXX
 SG_ DI_a250_tasMIA m250 : 17|1@1+ (1,0) [0|0] "" Vector__XXX
 SG_ DI_a251_summonActive m251 : 17|1@1+ (1,0) [0|0] "" Vector__XXX
 SG_ DI_a000_alertDataW0 m0 : 16|16@1+ (1,0) [0|0] "" Vector__XXX
 SG_ DI_a005_pButtonEvents m5 : 16|4@1+ (1,0) [0|0] "" Vector__XXX
 SG_ DI_a010_sccReset m10 : 16|1@1+ (1,0) [0|0] "" Vector__XXX
 SG_ DI_a012_accel1SupplyV m12 : 16|16@1+ (0.001,0) [0|0] "" Vector__XXX
 SG_ DI_a013_address m13 : 16|32@1+ (1,0) [0|0] "" Vector__XXX
 SG_ DI_a015_reason m15 : 16|1@1+ (1,0) [0|0] "" Vector__XXX
 SG_ DI_a021_packVoltage m21 : 16|16@1+ (0.1,0) [0|0] "" Vector__XXX
 SG_ DI_a024_pedalPos m24 : 16|8@1+ (0.4,0) [0|0] "" Vector__XXX
 SG_ DI_a025_backfillState m25 : 16|2@1+ (1,0) [0|0] "" Vector__XXX
 SG_ DI_a026_pedalPos m26 : 16|8@1+ (0.4,0) [0|0] "" Vector__XXX
 SG_ DI_a036_numFaultedUnits m36 : 16|4@1+ (1,0) [0|0] "" Vector__XXX
 SG_ DI_a040_torque m40 : 16|1@1+ (1,0) [0|0] "" Vector__XXX
 SG_ DI_a042_state4 m42 : 16|1@1+ (1,0) [0|0] "" Vector__XXX
 SG_ DI_a043_state4 m43 : 16|1@1+ (1,0) [0|0] "" Vector__XXX
 SG_ DI_a048_logId m48 : 16|4@1+ (1,0) [0|0] "" Vector__XXX
 SG_ DI_a051_dcCableCurrentEst m51 : 16|16@1- (0.1,0) [0|0] "" Vector__XXX
 SG_ DI_a052_torque m52 : 16|1@1+ (1,0) [0|0] "" Vector__XXX
 SG_ DI_a053_badValue1 m53 : 16|16@1+ (1,0) [0|0] "" Vector__XXX
 SG_ DI_a054_canID m54 : 16|16@1+ (1,0) [0|0] "" Vector__XXX
 SG_ DI_a055_mailboxID m55 : 16|16@1+ (1,0) [0|0] "" Vector__XXX
 SG_ DI_a056_badValue1 m56 : 16|16@1+ (1,0) [0|0] "" Vector__XXX
 SG_ DI_a057_canID m57 : 16|16@1+ (1,0) [0|0] "" Vector__XXX
 SG_ DI_a058_mailboxID m58 : 16|16@1+ (1,0) [0|0] "" Vector__XXX
 SG_ DI_a059_badValue1 m59 : 16|16@1+ (1,0) [0|0] "" Vector__XXX
 SG_ DI_a060_canID m60 : 16|16@1+ (1,0) [0|0] "" Vector__XXX
 SG_ DI_a061_mailboxID m61 : 16|16@1+ (1,0) [0|0] "" Vector__XXX
 SG_ DI_a062_limpReason m62 : 16|6@1+ (1,0) [0|0] "" Vector__XXX
 SG_ DI_a063_gpoReason m63 : 16|4@1+ (1,0) [0|0] "" Vector__XXX
 SG_ DI_a064_hvState m64 : 16|3@1+ (1,0) [0|0] "" Vector__XXX
 SG_ DI_a065_canID m65 : 16|16@1+ (1,0) [0|0] "" Vector__XXX
 SG_ DI_a066_badValue1 m66 : 16|16@1+ (1,0) [0|0] "" Vector__XXX
 SG_ DI_a067_canID m67 : 16|16@1+ (1,0) [0|0] "" Vector__XXX
 SG_ DI_a068_wheelSpeedDiffFrL m68 : 16|12@1- (0.0625,0) [0|0] "" Vector__XXX
 SG_ DI_a070_serviceDataId m70 : 16|16@1+ (1,0) [0|0] "" Vector__XXX
 SG_ DI_a074_recoveredGear m74 : 16|3@1+ (1,0) [0|0] "" Vector__XXX
 SG_ DI_a076_lvSupplyV m76 : 16|16@1+ (0.001,0) [0|0] "" Vector__XXX
 SG_ DI_a077_lvSupplyV m77 : 16|16@1+ (0.001,0) [0|0] "" Vector__XXX
 SG_ DI_a078_adcRefChan m78 : 16|4@1+ (1,0) [0|0] "" Vector__XXX
 SG_ DI_a079_adcRefChan m79 : 16|4@1+ (1,0) [0|0] "" Vector__XXX
 SG_ DI_a080_track1Voltage m80 : 16|16@1+ (0.001,0) [0|0] "" Vector__XXX
 SG_ DI_a081_track1Voltage m81 : 16|16@1+ (0.001,0) [0|0] "" Vector__XXX
 SG_ DI_a082_track1Voltage m82 : 16|16@1+ (0.001,0) [0|0] "" Vector__XXX
 SG_ DI_a083_brakeSwitchNO m83 : 16|1@1+ (1,0) [0|0] "" Vector__XXX
 SG_ DI_a084_lowDataValue m84 : 16|32@1+ (1,0) [0|0] "" Vector__XXX
 SG_ DI_a087_gtwCarConfig m87 : 16|1@1+ (1,0) [0|0] "" Vector__XXX
 SG_ DI_a088_uiChassisControl m88 : 16|1@1+ (1,0) [0|0] "" Vector__XXX
 SG_ DI_a089_SCCM_rightStalk m89 : 16|1@1+ (1,0) [0|0] "" Vector__XXX
 SG_ DI_a090_reason m90 : 16|1@1+ (1,0) [0|0] "" Vector__XXX
 SG_ DI_a091_ESP_brakeTorque m91 : 16|1@1+ (1,0) [0|0] "" Vector__XXX
 SG_ DI_a092_bmsStatus m92 : 16|1@1+ (1,0) [0|0] "" Vector__XXX
 SG_ DI_a093_mailboxID m93 : 16|16@1+ (1,0) [0|0] "" Vector__XXX
 SG_ DI_a094_canID m94 : 16|12@1+ (1,0) [0|0] "" Vector__XXX
 SG_ DI_a095_mailboxID m95 : 16|16@1+ (1,0) [0|0] "" Vector__XXX
 SG_ DI_a096_const_fast m96 : 16|1@1+ (1,0) [0|0] "" Vector__XXX
 SG_ DI_a097_errorType m97 : 16|3@1+ (1,0) [0|0] "" Vector__XXX
 SG_ DI_a098_page0Counter m98 : 16|8@1+ (1,0) [0|0] "" Vector__XXX
 SG_ DI_a099_watchdogReset m99 : 16|1@1+ (1,0) [0|0] "" Vector__XXX
 SG_ DI_a100_mcr m100 : 16|32@1+ (1,0) [0|0] "" Vector__XXX
 SG_ DI_a101_highDataValue m101 : 16|32@1+ (1,0) [0|0] "" Vector__XXX
 SG_ DI_a104_proxIrrationalReason m104 : 16|1@1+ (1,0) [0|0] "" Vector__XXX
 SG_ DI_a105_cpStatus m105 : 16|1@1+ (1,0) [0|0] "" Vector__XXX
 SG_ DI_a108_APP_environment m108 : 16|1@1+ (1,0) [0|0] "" Vector__XXX
 SG_ DI_a110_EPBL_status m110 : 16|1@1+ (1,0) [0|0] "" Vector__XXX
 SG_ DI_a112_eventStartMs m112 : 16|12@1+ (1,0) [0|0] "" Vector__XXX
 SG_ DI_a122_taskID m122 : 16|5@1+ (1,0) [0|0] "" Vector__XXX
 SG_ DI_a124_undrivenWheelMPH m124 : 16|16@1+ (0.1,0) [0|0] "" Vector__XXX
 SG_ DI_a125_maxDischargeCurrent m125 : 16|16@1- (0.1,0) [0|0] "" Vector__XXX
 SG_ DI_a130_aebFaultReason m130 : 16|4@1+ (1,0) [0|0] "" Vector__XXX
 SG_ DI_a131_totalTimeRemaining m131 : 16|16@1+ (1,0) [0|0] "" Vector__XXX
 SG_ DI_a133_vhldSmState m133 : 16|4@1+ (1,0) [0|0] "" Vector__XXX
 SG_ DI_a134_wheelSpeedDiffFrL m134 : 16|12@1- (0.0625,0) [0|0] "" Vector__XXX
 SG_ DI_a135_vhldFaultReason m135 : 16|4@1+ (1,0) [0|0] "" Vector__XXX
 SG_ DI_a140_PTC_feedbackStatus m140 : 16|1@1+ (1,0) [0|0] "" Vector__XXX
 SG_ DI_a141_DAS_control m141 : 16|1@1+ (1,0) [0|0] "" Vector__XXX
 SG_ DI_a142_impactedWheel m142 : 16|2@1+ (1,0) [0|0] "" Vector__XXX
 SG_ DI_a143_mechPowerLimit m143 : 16|1@1+ (1,0) [0|0] "" Vector__XXX
 SG_ DI_a144_autopilot m144 : 16|1@1+ (1,0) [0|0] "" Vector__XXX
 SG_ DI_a146_panicReason m146 : 16|3@1+ (1,0) [0|0] "" Vector__XXX
 SG_ DI_a154_rearSteeringAngle m154 : 16|3@1+ (1,0) [0|0] "" Vector__XXX
 SG_ DI_a155_sensors m155 : 16|1@1+ (1,0) [0|0] "" Vector__XXX
 SG_ DI_a157_RCM_inertial1 m157 : 16|1@1+ (1,0) [0|0] "" Vector__XXX
 SG_ DI_a158_IBST_party1 m158 : 16|1@1+ (1,0) [0|0] "" Vector__XXX
 SG_ DI_a159_gradeEst m159 : 16|8@1- (0.5,0) [0|0] "" Vector__XXX
 SG_ DI_a160_kTire m160 : 16|7@1+ (0.001,0.008) [0|0] "" Vector__XXX
 SG_ DI_a161_EPAS3P_sysStatus m161 : 16|1@1+ (1,0) [0|0] "" Vector__XXX
 SG_ DI_a162_shiftDeniedReason m162 : 16|4@1+ (1,0) [0|0] "" Vector__XXX
 SG_ DI_a163_motorSpeed m163 : 16|16@1- (0.01,0) [0|0] "" Vector__XXX
 SG_ DI_a164_motorSpeed m164 : 16|16@1- (0.01,0) [0|0] "" Vector__XXX
 SG_ DI_a165_crsCancelReason m165 : 16|4@1+ (1,0) [0|0] "" Vector__XXX
 SG_ DI_a170_tireSeasonSelected m170 : 16|1@1+ (1,0) [0|0] "" Vector__XXX
 SG_ DI_a172_motorSpeed m172 : 16|16@1- (0.01,0) [0|0] "" Vector__XXX
 SG_ DI_a173_brakeApply m173 : 16|16@1- (0.01,0) [0|0] "" Vector__XXX
 SG_ DI_a175_crsNotAvailableReason m175 : 16|6@1+ (1,0) [0|0] "" Vector__XXX
 SG_ DI_a177_newFitment m177 : 16|2@1+ (1,0) [0|0] "" Vector__XXX
 SG_ DI_a178_offsetValue m178 : 16|8@1- (0.16,0) [0|0] "" Vector__XXX
 SG_ DI_a180_crsNotAvailableReason m180 : 16|6@1+ (1,0) [0|0] "" Vector__XXX
 SG_ DI_a184_apcCancelReason m184 : 16|5@1+ (1,0) [0|0] "" Vector__XXX
 SG_ DI_a185_summonActive m185 : 16|1@1+ (1,0) [0|0] "" Vector__XXX
 SG_ DI_a187_filteredAccel m187 : 16|16@1- (0.01,0) [0|0] "" Vector__XXX
 SG_ DI_a188_relativeTireTreadDepth m188 : 16|6@1+ (0.2,0) [0|0] "" Vector__XXX
 SG_ DI_a189_accelPedal m189 : 16|5@1+ (3.125,0) [0|0] "" Vector__XXX
 SG_ DI_a190_relativeTireTreadDepth m190 : 16|6@1+ (0.2,0) [0|0] "" Vector__XXX
 SG_ DI_a191_motorSpeed m191 : 16|16@1- (0.01,0) [0|0] "" Vector__XXX
 SG_ DI_a193_brakeTorqueFrL m193 : 16|3@1+ (1,0) [0|0] "" Vector__XXX
 SG_ DI_a194_brakeTorqueReL m194 : 16|3@1+ (1,0) [0|0] "" Vector__XXX
 SG_ DI_a195_wheelSlipFrL m195 : 16|3@1+ (1,0) [0|0] "" Vector__XXX
 SG_ DI_a196_wheelSlipReL m196 : 16|3@1+ (1,0) [0|0] "" Vector__XXX
 SG_ DI_a197_wheelSaturationFrL m197 : 16|3@1+ (1,0) [0|0] "" Vector__XXX
 SG_ DI_a198_MCPressure m198 : 16|3@1+ (1,0) [0|0] "" Vector__XXX
 SG_ DI_a199_muVehicleLearnDown m199 : 16|5@1+ (0.05,0) [0|0] "" Vector__XXX
 SG_ DI_a200_MBPCheckStatus m200 : 16|1@1+ (1,0) [0|0] "" Vector__XXX
 SG_ DI_a201_maxRegenPower m201 : 16|16@1- (0.5,0) [0|0] "" Vector__XXX
 SG_ DI_a202_reason m202 : 16|4@1+ (1,0) [0|0] "" Vector__XXX
 SG_ DI_a203_ptcStateLocal m203 : 16|3@1+ (1,0) [0|0] "" Vector__XXX
 SG_ DI_a204_longAccel m204 : 16|3@1+ (1,0) [0|0] "" Vector__XXX
 SG_ DI_a205_latAccel m205 : 16|3@1+ (1,0) [0|0] "" Vector__XXX
 SG_ DI_a206_verticalAccel m206 : 16|3@1+ (1,0) [0|0] "" Vector__XXX
 SG_ DI_a207_motorTorque m207 : 16|3@1+ (1,0) [0|0] "" Vector__XXX
 SG_ DI_a208_motorTorque m208 : 16|3@1+ (1,0) [0|0] "" Vector__XXX
 SG_ DI_a210_ptcStateGlobal m210 : 16|2@1+ (1,0) [0|0] "" Vector__XXX
 SG_ DI_a211_motorSpeed m211 : 16|3@1+ (1,0) [0|0] "" Vector__XXX
 SG_ DI_a212_wheelRotationFrL m212 : 16|3@1+ (1,0) [0|0] "" Vector__XXX
 SG_ DI_a213_previousState m213 : 16|2@1+ (1,0) [0|0] "" Vector__XXX
 SG_ DI_a214_wheelSpeedFrL m214 : 16|3@1+ (1,0) [0|0] "" Vector__XXX
 SG_ DI_a215_wheelSpeedReL m215 : 16|3@1+ (1,0) [0|0] "" Vector__XXX
 SG_ DI_a216_MBPCheckStatus m216 : 16|1@1+ (1,0) [0|0] "" Vector__XXX
 SG_ DI_a217_IrrationalOutputReason m217 : 16|3@1+ (1,0) [0|0] "" Vector__XXX
 SG_ DI_a218_vdcActivationAlertType m218 : 16|2@1+ (1,0) [0|0] "" Vector__XXX
 SG_ DI_a219_vdcActivationAlertType m219 : 16|2@1+ (1,0) [0|0] "" Vector__XXX
 SG_ DI_a220_vdcActivationAlertType m220 : 16|2@1+ (1,0) [0|0] "" Vector__XXX
 SG_ DI_a221_vdcActivationAlertType m221 : 16|2@1+ (1,0) [0|0] "" Vector__XXX
 SG_ DI_a223_ptcStateLocal m223 : 16|3@1+ (1,0) [0|0] "" Vector__XXX
 SG_ DI_a224_brakeFLTemp m224 : 16|10@1- (1,300) [0|0] "" Vector__XXX
 SG_ DI_a226_systState m226 : 16|4@1+ (1,0) [0|0] "" Vector__XXX
 SG_ DI_a227_hvState m227 : 16|3@1+ (1,0) [0|0] "" Vector__XXX
 SG_ DI_a228_bteDegraded m228 : 16|1@1+ (1,0) [0|0] "" Vector__XXX
 SG_ DI_a230_CMP_HVStatus m230 : 16|1@1+ (1,0) [0|0] "" Vector__XXX
 SG_ DI_a232_velocityEstimatorState m232 : 16|3@1+ (1,0) [0|0] "" Vector__XXX
 SG_ DI_a233_impactedWheel m233 : 16|2@1+ (1,0) [0|0] "" Vector__XXX
 SG_ DI_a236_states m236 : 16|1@1+ (1,0) [0|0] "" Vector__XXX
 SG_ DI_a237_lateralAccel m237 : 16|8@1- (0.25,0) [0|0] "" Vector__XXX
 SG_ DI_a239_numRequests m239 : 16|16@1+ (1,0) [0|0] "" Vector__XXX
 SG_ DI_a241_motorSpeed m241 : 16|3@1+ (1,0) [0|0] "" Vector__XXX
 SG_ DI_a242_trailerSwayIndex m242 : 16|5@1+ (0.05,0) [0|0] "" Vector__XXX
 SG_ DI_a244_massEstimate m244 : 16|10@1+ (10,1500) [0|0] "" Vector__XXX
 SG_ DI_a245_ebrStatus m245 : 16|2@1+ (1,0) [0|0] "" Vector__XXX
 SG_ DI_a246_onePedalDrivingState m246 : 16|4@1+ (1,0) [0|0] "" Vector__XXX
 SG_ DI_a248_vdcTurnDirection m248 : 16|2@1- (1,0) [0|0] "" Vector__XXX
 SG_ DI_a249_learning_DIF m249 : 16|1@1+ (1,0) [0|0] "" Vector__XXX
 SG_ DI_a250_tasRequest m250 : 16|1@1+ (1,0) [0|0] "" Vector__XXX
 SG_ DI_a251_diPowerOnForDrive m251 : 16|1@1+ (1,0) [0|0] "" Vector__XXX
 SG_ DI_a253_track1Voltage m253 : 16|16@1+ (0.001,0) [0|0] "" Vector__XXX
 SG_ DI_a254_vxFromAx m254 : 16|10@1+ (0.05,0) [0|0] "" Vector__XXX
 SG_ DI_alertState : 15|1@1+ (1,0) [0|0] "" Vector__XXX
 SG_ DI_alertID M : 0|8@1+ (1,0) [0|0] "" Vector__XXX

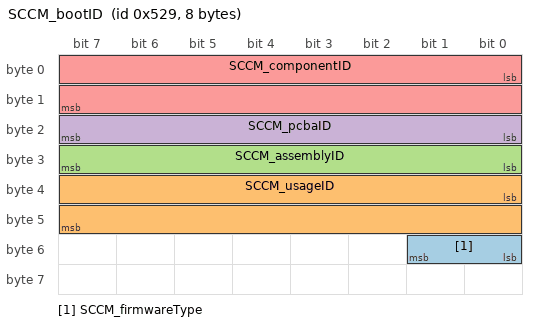
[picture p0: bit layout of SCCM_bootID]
BO_ 1321 SCCM_bootID: 8 Vector__XXX
 SG_ SCCM_firmwareType : 48|2@1+ (1,0) [0|0] "" Vector__XXX
 SG_ SCCM_usageID : 32|16@1+ (1,0) [0|0] "" Vector__XXX
 SG_ SCCM_assemblyID : 24|8@1+ (1,0) [0|0] "" Vector__XXX
 SG_ SCCM_pcbaID : 16|8@1+ (1,0) [0|0] "" Vector__XXX
 SG_ SCCM_componentID : 0|16@1+ (1,0) [0|0] "" Vector__XXX

BO_ 1322 FC_alertLog: 8 Vector__XXX
 SG_ FC_a146_CA_flybackTargetV m146 : 48|16@1+ (0.01283327338,0) [0|0] "" Vector__XXX
 SG_ FC_a146_CA_flybackV m146 : 32|16@1+ (0.01283327338,0) [0|0] "" Vector__XXX
 SG_ FC_a159_CA_wdtTaskList2 m159 : 32|16@1+ (1,0) [0|0] "" Vector__XXX
 SG_ FC_a130_CA_flybackSwOvType m130 : 16|1@1+ (1,0) [0|0] "" Vector__XXX
 SG_ FC_a146_CA_flybackOnTime m146 : 16|16@1+ (0.0007629511,0) [0|0] "" Vector__XXX
 SG_ FC_a159_CA_wdtTaskList1 m159 : 16|16@1+ (1,0) [0|0] "" Vector__XXX
 SG_ FC_alertType : 15|1@1+ (1,0) [0|0] "" Vector__XXX
 SG_ FC_alertID M : 0|15@1+ (1,0) [0|0] "" Vector__XXX

BO_ 1327 GTW_epochTimeGtw: 8 Vector__XXX
 SG_ GTW_epoch_ns : 7|64@0+ (1,0) [0|0] "" Vector__XXX

CM_ BO_ 1317 "ESP32-DualCAN Model3_VEH. Not seen on this car in the logs.";
VAL_ 1317 PMF_a010_DI_systemStatus 0 "UNKNOWN" 1 "RELEASED" 2 "PARKED" 3 "DYNAMIC" 4 "PARKING" 5 "RELEASING" 6 "FAULT" 7 "FAULT_SECURE" 8 "MISMATCH" ;
VAL_ 1317 PMF_a010_DI_status 0 "DISABLED" 1 "ENABLED" 2 "TEMPORARY_FAILURE" 3 "SNA" ;
VAL_ 1317 PMF_a064_UI_stoppingMode 0 "STANDARD" 1 "CREEP" 2 "HOLD" ;
VAL_ 1317 PMF_a042_GTW_drivetrainType 0 "RWD" 1 "AWD" ;
VAL_ 1317 PMF_a017_EPBR_status 0 "DISABLED" 1 "ENABLED" 2 "TEMPORARY_FAILURE" 3 "SNA" ;
VAL_ 1317 PMF_a017_EPBL_status 0 "DISABLED" 1 "ENABLED" 2 "TEMPORARY_FAILURE" 3 "SNA" ;
VAL_ 1317 PMF_a033_state 0 "STANDBY" 1 "DRIVE" 2 "SUPPORT" 3 "CHARGE" 4 "FEIM" 5 "CLEAR_FAULT" 6 "FAULT" 7 "WELD" 8 "TEST" 9 "SNA" 10 "DIAG" ;
VAL_ 1317 PMF_a039_DIS_status 0 "DISABLED" 1 "ENABLED" 2 "TEMPORARY_FAILURE" 3 "SNA" ;
VAL_ 1317 PMF_a040_PM_state 0 "STANDBY" 1 "DRIVE" 2 "SUPPORT" 3 "CHARGE" 4 "FEIM" 5 "CLEAR_FAULT" 6 "FAULT" 7 "WELD" 8 "TEST" 9 "SNA" 10 "DIAG" ;
VAL_ 1317 PMF_alertState 0 "CLEARED" 1 "SET" ;
VAL_ 1317 PMF_alertID 0 "ALERT_DO_NOT_USE_ZERO" 1 "a001_DriverDoorOpen" 2 "a002_DoorOpen" 3 "a003_TrunkOpen" 4 "a004_FrunkOpen" 5 "a005_HeadlightsOnDoorOpen" 6 "a006_RemoteServiceAlert" 7 "a007_SoftPackConfigMismatch" 8 "a008_TouchScreenError" 9 "a009_SquashfsError" 10 "a010_MapsMissing" 11 "a011_IncorrectMap" 12 "a012_NotOnPrivateProperty" 13 "a013_TPMSHardWarning" 14 "a014_TPMSSoftWarning" 15 "a015_TPMSOverPressureWarning" 16 "a016_TPMSTemperatureWarning" 17 "a017_TPMSSystemFault" 18 "a018_SlipStartOn" 19 "a019_ParkBrakeFault" 20 "a020_SteeringReduced" 21 "a021_RearSeatbeltUnbuckled" 22 "a022_ApeFusesEtc" 23 "a023_CellInternetCheckFailed" 24 "a024_WifiInternetCheckFailed" 25 "a025_WifiOnlineCheckFailed" 26 "a026_ModemResetLoopDetected" 27 "a027_AutoSteerMIA" 28 "a028_FrontTrunkPopupClosed" 29 "a029_ModemMIA" 30 "a030_ModemVMCrash" 31 "a031_BrakeFluidLow" 32 "a032_CellModemRecoveryResets" 33 "a033_ApTrialExpired" 34 "a034_WakeupProblem" 35 "a035_AudioWatchdogKernelError" 36 "a036_AudioWatchdogHfpError" 37 "a037_AudioWatchdogXrunStormError" 38 "a038_AudioWatchdogA2bI2cLockupError" 39 "a039_AudioA2bNeedRediscovery" 40 "a040_HomelinkTransmit" 41 "a041_AudioDmesgXrun" 42 "a042_AudioDmesgRtThrottling" 43 "a043_InvalidMapDataOverride" 44 "a044_AudioDmesgDspException" 45 "a045_ECallNeedsService" 46 "a046_BackupCameraStreamError" 47 "a047_CellRoamingDisallowed" 48 "a048_AudioPremiumAmpCheckFailed" 49 "a049_BrakeShiftRequired" 50 "a050_BackupCameraIPUTimeout" 51 "a051_BackupCameraFrameTimeout" 52 "a052_KernelPanicReported" 53 "a053_QtCarExitError" 54 "a054_AudioBoostPowerBad" 55 "a055_ManualECallDisabled" 56 "a056_ManualECallButtonDisconnected" 57 "a057_CellAntennaDisconnected" 58 "a058_GPSAntennaDisconnected" 59 "a059_ECallSpeakerDisconnected" 60 "a060_ECallMicDisconnected" 61 "a061_SIMTestFailed" 62 "a062_ENSTestFailed" 63 "a063_CellularTestFailed" 64 "a064_ModemFirmwareTestFailed" 65 "a065_WiFiRecoveryReset" 66 "a066_GpuHangDetected" 67 "a067_WarnOnI915" 68 "a068_VideoUnexpectedExit" 69 "a069_VideoUDPTimeout" 70 "a070_VideoPipelineWarning" 71 "a071_VideoPipelineError" 72 "a072_ECallAnalogMicFailed" 73 "a073_ECallDigitalMicFailed" 74 "a074_EMMCHangDetected" 75 "a075_BackupCameraInitError" 76 "a076_NumFalseManualECalls" 77 "a077_AudioA2bMicChannelSwap" 78 "a078_DashcamUsbDriveUnmountable" 79 "a079_DashcamUsbDriveFull" 80 "a080_DashcamUsbDriveSlow" 81 "a081_CellModemSearchExpired" 82 "a082_NumModemRebootStuckInECall" 83 "a083_ECallProxyWatchdogTriggered" 84 "a084_SerializerError" 85 "a085_DeserializerError" 86 "a086_TouchEnumerationError" 87 "a087_BmpReset" 88 "a088_CellRemovableSimMissing" 89 "a089_RadioSoftResetError" 90 "a090_RadioPingFailError" 91 "a091_VehicleLinkStall" 92 "a092_updateStarted" 93 "a093_updateEnded" 94 "a094_ModemPowerOnFailure" 95 "a095_CidStorageRunningLow" 96 "a096_VideodPipelineIssueDetected" 97 "a097_AudiodRestarted" 98 "a098_DiskCheckFailure" 99 "a099_eMMCStatusError" 100 "a100_eMMCFTLError" 101 "a101_wifiStackProblem" 102 "a102_A2bDiscoveryFailed" 103 "a103_UsbHubNotEnumerating" 104 "a104_DashcamUsbDriveMissing" 105 "a105_firmwareReinstallRequested" 106 "a106_rebootBackstopTriggered" 107 "a107_DashcamUsbDriveTooBigForVfatFsck" 108 "a108_DashcamUsbDriveGettingFull" 109 "a109_DashcamUsbDriveTooSmall" 110 "a110_DashcamUsbDriveCorrupt" 111 "a111_DashcamUsbDriveWrongPort" 112 "a112_badUSBDevice" 113 "a113_DashcamHasOnboardSentryClips" ;
CM_ BO_ 1318 "ESP32-DualCAN Model3_VEH. Not seen on this car in the logs.";
VAL_ 1318 DIF_a153_state 0 "STANDBY" 1 "DRIVE" 2 "SUPPORT" 3 "CHARGE" 4 "FEIM" 5 "CLEAR_FAULT" 6 "FAULT" 7 "WELD" 8 "TEST" 9 "SNA" 10 "DIAG" ;
VAL_ 1318 DIF_a103_ambientTemp 4294966273 "SNA" ;
VAL_ 1318 DIF_a014_brakeMasterCylPress 1023 "SNA" ;
VAL_ 1318 DIF_a149_state 0 "STANDBY" 1 "DRIVE" 2 "SUPPORT" 3 "CHARGE" 4 "FEIM" 5 "CLEAR_FAULT" 6 "FAULT" 7 "WELD" 8 "TEST" 9 "SNA" 10 "DIAG" ;
VAL_ 1318 DIF_a144_powerLiftgateType 0 "NOT_INSTALLED" 1 "TESLA_REV1" ;
VAL_ 1318 DIF_a144_dasHw 3 "PARKER_PASCAL_2_5" 4 "TESLA_AP3" ;
VAL_ 1318 DIF_a014_adState 0 "STARTUP" 1 "NORMAL" 2 "BACKUP" 3 "FAULTED" ;
VAL_ 1318 DIF_a024_state 0 "STANDBY" 1 "DRIVE" 2 "SUPPORT" 3 "CHARGE" 4 "FEIM" 5 "CLEAR_FAULT" 6 "FAULT" 7 "WELD" 8 "TEST" 9 "SNA" 10 "DIAG" ;
VAL_ 1318 DIF_a144_frunkLatchType 0 "UNKNOWN" 1 "DOUBLE_ACTUATOR" 2 "DOUBLE_PULL" ;
VAL_ 1318 DIF_a144_cabinPTCHeaterType 0 "BORGWARNER" 1 "NONE" ;
VAL_ 1318 DIF_a155_systemStatus 0 "UNKNOWN" 1 "RELEASED" 2 "PARKED" 3 "DYNAMIC" 4 "PARKING" 5 "RELEASING" 6 "FAULT" 7 "FAULT_SECURE" 8 "MISMATCH" ;
VAL_ 1318 DIF_a162_additionalFetBurnIn 65535 "SNA" ;
VAL_ 1318 DIF_a144_brakeHWType 0 "P42_MANDO_43MOC" 1 "LARGE_P42_BREMBO_44MOC" 2 "LARGE_P42_MANDO_43MOC" 3 "LARGE_P42_BREMBO_LARGE_44MOC" 6 "LARGE_P42_V2_BREMBO_44MOC" 7 "LARGE_P42_V2_BREMBO_LARGE_44MOC" ;
VAL_ 1318 DIF_a117_systemStatus 0 "UNKNOWN" 1 "RELEASED" 2 "PARKED" 3 "DYNAMIC" 4 "PARKING" 5 "RELEASING" 6 "FAULT" 7 "FAULT_SECURE" 8 "MISMATCH" ;
VAL_ 1318 DIF_a144_vdcType 0 "BOSCH_VDC" 1 "TESLA_VDC" ;
VAL_ 1318 DIF_a091_ESP_status 0 "DISABLED" 1 "ENABLED" 2 "TEMPORARY_FAILURE" 3 "SNA" ;
VAL_ 1318 DIF_a144_performancePackage 0 "BASE" 1 "PERFORMANCE" 3 "BASE_PLUS" 4 "SNA" ;
VAL_ 1318 DIF_a155_status 0 "DISABLED" 1 "ENABLED" 2 "TEMPORARY_FAILURE" 3 "SNA" ;
VAL_ 1318 DIF_a040_status 0 "DISABLED" 1 "ENABLED" 2 "TEMPORARY_FAILURE" 3 "SNA" ;
VAL_ 1318 DIF_a052_status 0 "DISABLED" 1 "ENABLED" 2 "TEMPORARY_FAILURE" 3 "SNA" ;
VAL_ 1318 DIF_a144_packEnergy 0 "50_KWH" 1 "74_KWH" 2 "62_KWH" ;
VAL_ 1318 DIF_a090_state 0 "STANDBY" 1 "DRIVE" 2 "SUPPORT" 3 "CHARGE" 4 "FEIM" 5 "CLEAR_FAULT" 6 "FAULT" 7 "WELD" 8 "TEST" 9 "SNA" 10 "DIAG" ;
VAL_ 1318 DIF_a144_drivetrainType 0 "RWD" 1 "AWD" ;
VAL_ 1318 DIF_a158_BUS2_IBST_status 0 "DISABLED" 1 "ENABLED" 2 "TEMPORARY_FAILURE" 3 "SNA" ;
VAL_ 1318 DIF_a110_EPBR_status 0 "DISABLED" 1 "ENABLED" 2 "TEMPORARY_FAILURE" 3 "SNA" ;
VAL_ 1318 DIF_a144_chassisType 2 "3_CHASSIS" 3 "Y_CHASSIS" ;
VAL_ 1318 DIF_a158_BUS1_IBST_status 0 "DISABLED" 1 "ENABLED" 2 "TEMPORARY_FAILURE" 3 "SNA" ;
VAL_ 1318 DIF_a110_EPBL_status 0 "DISABLED" 1 "ENABLED" 2 "TEMPORARY_FAILURE" 3 "SNA" ;
VAL_ 1318 DIF_a144_autopilot 0 "NONE" 1 "HIGHWAY" 2 "ENHANCED" 3 "SELF_DRIVING" 4 "BASIC" ;
VAL_ 1318 DIF_a162_normalFetBurnIn 65535 "SNA" ;
VAL_ 1318 DIF_alertState 0 "CLEARED" 1 "SET" ;
VAL_ 1318 DIF_alertID 0 "ALERT_DO_NOT_USE_ZERO" 1 "a001_DriverDoorOpen" 2 "a002_DoorOpen" 3 "a003_TrunkOpen" 4 "a004_FrunkOpen" 5 "a005_HeadlightsOnDoorOpen" 6 "a006_RemoteServiceAlert" 7 "a007_SoftPackConfigMismatch" 8 "a008_TouchScreenError" 9 "a009_SquashfsError" 10 "a010_MapsMissing" 11 "a011_IncorrectMap" 12 "a012_NotOnPrivateProperty" 13 "a013_TPMSHardWarning" 14 "a014_TPMSSoftWarning" 15 "a015_TPMSOverPressureWarning" 16 "a016_TPMSTemperatureWarning" 17 "a017_TPMSSystemFault" 18 "a018_SlipStartOn" 19 "a019_ParkBrakeFault" 20 "a020_SteeringReduced" 21 "a021_RearSeatbeltUnbuckled" 22 "a022_ApeFusesEtc" 23 "a023_CellInternetCheckFailed" 24 "a024_WifiInternetCheckFailed" 25 "a025_WifiOnlineCheckFailed" 26 "a026_ModemResetLoopDetected" 27 "a027_AutoSteerMIA" 28 "a028_FrontTrunkPopupClosed" 29 "a029_ModemMIA" 30 "a030_ModemVMCrash" 31 "a031_BrakeFluidLow" 32 "a032_CellModemRecoveryResets" 33 "a033_ApTrialExpired" 34 "a034_WakeupProblem" 35 "a035_AudioWatchdogKernelError" 36 "a036_AudioWatchdogHfpError" 37 "a037_AudioWatchdogXrunStormError" 38 "a038_AudioWatchdogA2bI2cLockupError" 39 "a039_AudioA2bNeedRediscovery" 40 "a040_HomelinkTransmit" 41 "a041_AudioDmesgXrun" 42 "a042_AudioDmesgRtThrottling" 43 "a043_InvalidMapDataOverride" 44 "a044_AudioDmesgDspException" 45 "a045_ECallNeedsService" 46 "a046_BackupCameraStreamError" 47 "a047_CellRoamingDisallowed" 48 "a048_AudioPremiumAmpCheckFailed" 49 "a049_BrakeShiftRequired" 50 "a050_BackupCameraIPUTimeout" 51 "a051_BackupCameraFrameTimeout" 52 "a052_KernelPanicReported" 53 "a053_QtCarExitError" 54 "a054_AudioBoostPowerBad" 55 "a055_ManualECallDisabled" 56 "a056_ManualECallButtonDisconnected" 57 "a057_CellAntennaDisconnected" 58 "a058_GPSAntennaDisconnected" 59 "a059_ECallSpeakerDisconnected" 60 "a060_ECallMicDisconnected" 61 "a061_SIMTestFailed" 62 "a062_ENSTestFailed" 63 "a063_CellularTestFailed" 64 "a064_ModemFirmwareTestFailed" 65 "a065_WiFiRecoveryReset" 66 "a066_GpuHangDetected" 67 "a067_WarnOnI915" 68 "a068_VideoUnexpectedExit" 69 "a069_VideoUDPTimeout" 70 "a070_VideoPipelineWarning" 71 "a071_VideoPipelineError" 72 "a072_ECallAnalogMicFailed" 73 "a073_ECallDigitalMicFailed" 74 "a074_EMMCHangDetected" 75 "a075_BackupCameraInitError" 76 "a076_NumFalseManualECalls" 77 "a077_AudioA2bMicChannelSwap" 78 "a078_DashcamUsbDriveUnmountable" 79 "a079_DashcamUsbDriveFull" 80 "a080_DashcamUsbDriveSlow" 81 "a081_CellModemSearchExpired" 82 "a082_NumModemRebootStuckInECall" 83 "a083_ECallProxyWatchdogTriggered" 84 "a084_SerializerError" 85 "a085_DeserializerError" 86 "a086_TouchEnumerationError" 87 "a087_BmpReset" 88 "a088_CellRemovableSimMissing" 89 "a089_RadioSoftResetError" 90 "a090_RadioPingFailError" 91 "a091_VehicleLinkStall" 92 "a092_updateStarted" 93 "a093_updateEnded" 94 "a094_ModemPowerOnFailure" 95 "a095_CidStorageRunningLow" 96 "a096_VideodPipelineIssueDetected" 97 "a097_AudiodRestarted" 98 "a098_DiskCheckFailure" 99 "a099_eMMCStatusError" 100 "a100_eMMCFTLError" 101 "a101_wifiStackProblem" 102 "a102_A2bDiscoveryFailed" 103 "a103_UsbHubNotEnumerating" 104 "a104_DashcamUsbDriveMissing" 105 "a105_firmwareReinstallRequested" 106 "a106_rebootBackstopTriggered" 107 "a107_DashcamUsbDriveTooBigForVfatFsck" 108 "a108_DashcamUsbDriveGettingFull" 109 "a109_DashcamUsbDriveTooSmall" 110 "a110_DashcamUsbDriveCorrupt" 111 "a111_DashcamUsbDriveWrongPort" 112 "a112_badUSBDevice" 113 "a113_DashcamHasOnboardSentryClips" ;
CM_ BO_ 1319 "ESP32-DualCAN Model3_VEH. Seen on this car: 8-byte frames; fit good (bits covered 100%, mux 100%, ranges 100%).";
VAL_ 1319 DI_a224_brakeRRTemp 1023 "SNA" ;
VAL_ 1319 DI_a170_odometer 4294967295 "SNA" ;
VAL_ 1319 DI_a198_steeringAngle 16383 "SNA" ;
VAL_ 1319 DI_a204_rollRate 4294950912 "SNA" ;
VAL_ 1319 DI_a205_pitchRate 4294950912 "SNA" ;
VAL_ 1319 DI_a206_yawRate 4294934528 "SNA" ;
VAL_ 1319 DI_a237_vehicleSpeed 8191 "SNA" ;
VAL_ 1319 DI_a224_brakeRLTemp 1023 "SNA" ;
VAL_ 1319 DI_a144_powerLiftgateType 0 "NOT_INSTALLED" 1 "TESLA_REV1" ;
VAL_ 1319 DI_a144_dasHw 3 "PARKER_PASCAL_2_5" 4 "TESLA_AP3" ;
VAL_ 1319 DI_a051_packCurrent 4294934528 "SNA" ;
VAL_ 1319 DI_a223_UI_tractionControlMode 0 "NORMAL" 1 "SLIP_START" 2 "DEV_MODE_1" 3 "DEV_MODE_2" 4 "ROLLS_MODE" 5 "DYNO_MODE" 6 "OFFROAD_ASSIST" ;
VAL_ 1319 DI_a237_longitudinalAccel 4294934528 "SNA" ;
VAL_ 1319 DI_a223_DI_tractionControlMode 0 "NORMAL" 1 "SLIP_START" 2 "DEV_MODE_1" 3 "DEV_MODE_2" 4 "ROLLS_MODE" 5 "DYNO_MODE" 6 "OFFROAD_ASSIST" ;
VAL_ 1319 DI_a144_frunkLatchType 0 "UNKNOWN" 1 "DOUBLE_ACTUATOR" 2 "DOUBLE_PULL" ;
VAL_ 1319 DI_a224_brakeFRTemp 1023 "SNA" ;
VAL_ 1319 DI_a144_cabinPTCHeaterType 0 "BORGWARNER" 1 "NONE" ;
VAL_ 1319 DI_a155_systemStatus 0 "UNKNOWN" 1 "RELEASED" 2 "PARKED" 3 "DYNAMIC" 4 "PARKING" 5 "RELEASING" 6 "FAULT" 7 "FAULT_SECURE" 8 "MISMATCH" ;
VAL_ 1319 DI_a026_vehicleSpeed 8191 "SNA" ;
VAL_ 1319 DI_a064_vehicleSpeed 8191 "SNA" ;
VAL_ 1319 DI_a160_tireFitment 0 "SQUARE" 1 "STAGGERED" 3 "SNA" ;
VAL_ 1319 DI_a170_tireFitment 0 "SQUARE" 1 "STAGGERED" 3 "SNA" ;
VAL_ 1319 DI_a237_verticalAccel 4294934528 "SNA" ;
VAL_ 1319 DI_a144_brakeHWType 0 "P42_MANDO_43MOC" 1 "LARGE_P42_BREMBO_44MOC" 2 "LARGE_P42_MANDO_43MOC" 3 "LARGE_P42_BREMBO_LARGE_44MOC" 6 "LARGE_P42_V2_BREMBO_44MOC" 7 "LARGE_P42_V2_BREMBO_LARGE_44MOC" ;
VAL_ 1319 DI_a144_vdcType 0 "BOSCH_VDC" 1 "TESLA_VDC" ;
VAL_ 1319 DI_a091_ESP_status 0 "DISABLED" 1 "ENABLED" 2 "TEMPORARY_FAILURE" 3 "SNA" ;
VAL_ 1319 DI_a144_performancePackage 0 "BASE" 1 "PERFORMANCE" 3 "BASE_PLUS" 4 "SNA" ;
VAL_ 1319 DI_a155_status 0 "DISABLED" 1 "ENABLED" 2 "TEMPORARY_FAILURE" 3 "SNA" ;
VAL_ 1319 DI_a223_velocityEstimatorState 0 "NOT_INITIALIZED" 1 "WHEELS_NORMAL" 2 "WHEELS_REDUCED" 3 "BACKUP_WHEELS_A" 4 "BACKUP_WHEELS_B" 5 "BACKUP_MOTOR" ;
VAL_ 1319 DI_a040_status 0 "DISABLED" 1 "ENABLED" 2 "TEMPORARY_FAILURE" 3 "SNA" ;
VAL_ 1319 DI_a052_status 0 "DISABLED" 1 "ENABLED" 2 "TEMPORARY_FAILURE" 3 "SNA" ;
VAL_ 1319 DI_a064_vehiclePowerState 0 "OFF" 1 "CONDITIONING" 2 "ACCESSORY" 3 "DRIVE" ;
VAL_ 1319 DI_a074_vehicleSpeed 8191 "SNA" ;
VAL_ 1319 DI_a144_packEnergy 0 "50_KWH" 1 "74_KWH" 2 "62_KWH" ;
VAL_ 1319 DI_a227_vehiclePowerState 0 "OFF" 1 "CONDITIONING" 2 "ACCESSORY" 3 "DRIVE" ;
VAL_ 1319 DI_a232_UI_tractionControlMode 0 "NORMAL" 1 "SLIP_START" 2 "DEV_MODE_1" 3 "DEV_MODE_2" 4 "ROLLS_MODE" 5 "DYNO_MODE" 6 "OFFROAD_ASSIST" ;
VAL_ 1319 DI_a090_state 0 "STANDBY" 1 "DRIVE" 2 "SUPPORT" 3 "CHARGE" 4 "FEIM" 5 "CLEAR_FAULT" 6 "FAULT" 7 "WELD" 8 "TEST" 9 "SNA" 10 "DIAG" ;
VAL_ 1319 DI_a141_DAS_status 0 "DISABLED" 1 "ENABLED" 2 "TEMPORARY_FAILURE" 3 "SNA" ;
VAL_ 1319 DI_a144_drivetrainType 0 "RWD" 1 "AWD" ;
VAL_ 1319 DI_a158_BUS2_IBST_status 0 "DISABLED" 1 "ENABLED" 2 "TEMPORARY_FAILURE" 3 "SNA" ;
VAL_ 1319 DI_a245_vehicleHoldState 0 "UNAVAILABLE" 1 "STANDBY" 2 "BLEND_IN" 3 "STANDSTILL" 4 "BLEND_OUT" 5 "PARK" 6 "FAULT" 7 "INIT" ;
VAL_ 1319 DI_a108_APP_status 0 "DISABLED" 1 "ENABLED" 2 "TEMPORARY_FAILURE" 3 "SNA" ;
VAL_ 1319 DI_a110_EPBR_status 0 "DISABLED" 1 "ENABLED" 2 "TEMPORARY_FAILURE" 3 "SNA" ;
VAL_ 1319 DI_a143_systemTorqueLimit 63 "SNA" ;
VAL_ 1319 DI_a144_chassisType 2 "3_CHASSIS" 3 "Y_CHASSIS" ;
VAL_ 1319 DI_a158_BUS1_IBST_status 0 "DISABLED" 1 "ENABLED" 2 "TEMPORARY_FAILURE" 3 "SNA" ;
VAL_ 1319 DI_a230_CMPD_state 0 "STANDBY" 1 "DRIVE" 2 "SUPPORT" 3 "CHARGE" 4 "FEIM" 5 "CLEAR_FAULT" 6 "FAULT" 7 "WELD" 8 "TEST" 9 "SNA" 10 "DIAG" ;
VAL_ 1319 DI_a021_packVoltage 65535 "SNA" ;
VAL_ 1319 DI_a064_hvState 0 "DOWN" 1 "COMING_UP" 2 "GOING_DOWN" 3 "UP_FOR_DRIVE" 4 "UP_FOR_CHARGE" 5 "UP_FOR_DC_CHARGE" 6 "UP" ;
VAL_ 1319 DI_a110_EPBL_status 0 "DISABLED" 1 "ENABLED" 2 "TEMPORARY_FAILURE" 3 "SNA" ;
VAL_ 1319 DI_a144_autopilot 0 "NONE" 1 "HIGHWAY" 2 "ENHANCED" 3 "SELF_DRIVING" 4 "BASIC" ;
VAL_ 1319 DI_a173_brakeApply 0 "INACTIVE" 1 "ACTIVE" ;
VAL_ 1319 DI_a188_relativeTireTreadDepth 4294967264 "SNA" ;
VAL_ 1319 DI_a190_relativeTireTreadDepth 4294967264 "SNA" ;
VAL_ 1319 DI_a206_verticalAccel 4294934528 "SNA" ;
VAL_ 1319 DI_a224_brakeFLTemp 1023 "SNA" ;
VAL_ 1319 DI_a227_hvState 0 "DOWN" 1 "COMING_UP" 2 "GOING_DOWN" 3 "UP_FOR_DRIVE" 4 "UP_FOR_CHARGE" 5 "UP_FOR_DC_CHARGE" 6 "UP" ;
VAL_ 1319 DI_a232_velocityEstimatorState 0 "NOT_INITIALIZED" 1 "WHEELS_NORMAL" 2 "WHEELS_REDUCED" 3 "BACKUP_WHEELS_A" 4 "BACKUP_WHEELS_B" 5 "BACKUP_MOTOR" ;
VAL_ 1319 DI_a237_lateralAccel 4294934528 "SNA" ;
VAL_ 1319 DI_a245_ebrStatus 0 "EBR_IS_NOT_AVAILABLE" 1 "EBR_IS_AVAILABLE" 2 "ACTUATING_DI_EBR" 3 "EBR_COMMAND_INVALID" ;
VAL_ 1319 DI_a246_onePedalDrivingState 0 "UNAVAILABLE" 1 "QUICK_BRAKE_RAMP" 2 "STANDBY" 3 "NOMINAL" 4 "MOTOR_BLEND_OUT_PENDING" 5 "MOTOR_BLEND_OUT_ACTIVE" 6 "NO_MOTOR" 7 "MOTOR_BLEND_IN" 8 "NUM_STATES" ;
VAL_ 1319 DI_alertState 0 "CLEARED" 1 "SET" ;
VAL_ 1319 DI_alertID 0 "ALERT_DO_NOT_USE_ZERO" 1 "a001_DriverDoorOpen" 2 "a002_DoorOpen" 3 "a003_TrunkOpen" 4 "a004_FrunkOpen" 5 "a005_HeadlightsOnDoorOpen" 6 "a006_RemoteServiceAlert" 7 "a007_SoftPackConfigMismatch" 8 "a008_TouchScreenError" 9 "a009_SquashfsError" 10 "a010_MapsMissing" 11 "a011_IncorrectMap" 12 "a012_NotOnPrivateProperty" 13 "a013_TPMSHardWarning" 14 "a014_TPMSSoftWarning" 15 "a015_TPMSOverPressureWarning" 16 "a016_TPMSTemperatureWarning" 17 "a017_TPMSSystemFault" 18 "a018_SlipStartOn" 19 "a019_ParkBrakeFault" 20 "a020_SteeringReduced" 21 "a021_RearSeatbeltUnbuckled" 22 "a022_ApeFusesEtc" 23 "a023_CellInternetCheckFailed" 24 "a024_WifiInternetCheckFailed" 25 "a025_WifiOnlineCheckFailed" 26 "a026_ModemResetLoopDetected" 27 "a027_AutoSteerMIA" 28 "a028_FrontTrunkPopupClosed" 29 "a029_ModemMIA" 30 "a030_ModemVMCrash" 31 "a031_BrakeFluidLow" 32 "a032_CellModemRecoveryResets" 33 "a033_ApTrialExpired" 34 "a034_WakeupProblem" 35 "a035_AudioWatchdogKernelError" 36 "a036_AudioWatchdogHfpError" 37 "a037_AudioWatchdogXrunStormError" 38 "a038_AudioWatchdogA2bI2cLockupError" 39 "a039_AudioA2bNeedRediscovery" 40 "a040_HomelinkTransmit" 41 "a041_AudioDmesgXrun" 42 "a042_AudioDmesgRtThrottling" 43 "a043_InvalidMapDataOverride" 44 "a044_AudioDmesgDspException" 45 "a045_ECallNeedsService" 46 "a046_BackupCameraStreamError" 47 "a047_CellRoamingDisallowed" 48 "a048_AudioPremiumAmpCheckFailed" 49 "a049_BrakeShiftRequired" 50 "a050_BackupCameraIPUTimeout" 51 "a051_BackupCameraFrameTimeout" 52 "a052_KernelPanicReported" 53 "a053_QtCarExitError" 54 "a054_AudioBoostPowerBad" 55 "a055_ManualECallDisabled" 56 "a056_ManualECallButtonDisconnected" 57 "a057_CellAntennaDisconnected" 58 "a058_GPSAntennaDisconnected" 59 "a059_ECallSpeakerDisconnected" 60 "a060_ECallMicDisconnected" 61 "a061_SIMTestFailed" 62 "a062_ENSTestFailed" 63 "a063_CellularTestFailed" 64 "a064_ModemFirmwareTestFailed" 65 "a065_WiFiRecoveryReset" 66 "a066_GpuHangDetected" 67 "a067_WarnOnI915" 68 "a068_VideoUnexpectedExit" 69 "a069_VideoUDPTimeout" 70 "a070_VideoPipelineWarning" 71 "a071_VideoPipelineError" 72 "a072_ECallAnalogMicFailed" 73 "a073_ECallDigitalMicFailed" 74 "a074_EMMCHangDetected" 75 "a075_BackupCameraInitError" 76 "a076_NumFalseManualECalls" 77 "a077_AudioA2bMicChannelSwap" 78 "a078_DashcamUsbDriveUnmountable" 79 "a079_DashcamUsbDriveFull" 80 "a080_DashcamUsbDriveSlow" 81 "a081_CellModemSearchExpired" 82 "a082_NumModemRebootStuckInECall" 83 "a083_ECallProxyWatchdogTriggered" 84 "a084_SerializerError" 85 "a085_DeserializerError" 86 "a086_TouchEnumerationError" 87 "a087_BmpReset" 88 "a088_CellRemovableSimMissing" 89 "a089_RadioSoftResetError" 90 "a090_RadioPingFailError" 91 "a091_VehicleLinkStall" 92 "a092_updateStarted" 93 "a093_updateEnded" 94 "a094_ModemPowerOnFailure" 95 "a095_CidStorageRunningLow" 96 "a096_VideodPipelineIssueDetected" 97 "a097_AudiodRestarted" 98 "a098_DiskCheckFailure" 99 "a099_eMMCStatusError" 100 "a100_eMMCFTLError" 101 "a101_wifiStackProblem" 102 "a102_A2bDiscoveryFailed" 103 "a103_UsbHubNotEnumerating" 104 "a104_DashcamUsbDriveMissing" 105 "a105_firmwareReinstallRequested" 106 "a106_rebootBackstopTriggered" 107 "a107_DashcamUsbDriveTooBigForVfatFsck" 108 "a108_DashcamUsbDriveGettingFull" 109 "a109_DashcamUsbDriveTooSmall" 110 "a110_DashcamUsbDriveCorrupt" 111 "a111_DashcamUsbDriveWrongPort" 112 "a112_badUSBDevice" 113 "a113_DashcamHasOnboardSentryClips" ;
CM_ BO_ 1321 "ESP32-DualCAN Model3_VEH. Seen on this car: 8-byte frames; fit weak (bits covered 0%, mux 100%, ranges 100%).";
CM_ BO_ 1322 "ESP32-DualCAN Model3_VEH. Not seen on this car in the logs.";
VAL_ 1322 FC_alertID 0 "ALERT_DO_NOT_USE_ZERO" 1 "a001_DriverDoorOpen" 2 "a002_DoorOpen" 3 "a003_TrunkOpen" 4 "a004_FrunkOpen" 5 "a005_HeadlightsOnDoorOpen" 6 "a006_RemoteServiceAlert" 7 "a007_SoftPackConfigMismatch" 8 "a008_TouchScreenError" 9 "a009_SquashfsError" 10 "a010_MapsMissing" 11 "a011_IncorrectMap" 12 "a012_NotOnPrivateProperty" 13 "a013_TPMSHardWarning" 14 "a014_TPMSSoftWarning" 15 "a015_TPMSOverPressureWarning" 16 "a016_TPMSTemperatureWarning" 17 "a017_TPMSSystemFault" 18 "a018_SlipStartOn" 19 "a019_ParkBrakeFault" 20 "a020_SteeringReduced" 21 "a021_RearSeatbeltUnbuckled" 22 "a022_ApeFusesEtc" 23 "a023_CellInternetCheckFailed" 24 "a024_WifiInternetCheckFailed" 25 "a025_WifiOnlineCheckFailed" 26 "a026_ModemResetLoopDetected" 27 "a027_AutoSteerMIA" 28 "a028_FrontTrunkPopupClosed" 29 "a029_ModemMIA" 30 "a030_ModemVMCrash" 31 "a031_BrakeFluidLow" 32 "a032_CellModemRecoveryResets" 33 "a033_ApTrialExpired" 34 "a034_WakeupProblem" 35 "a035_AudioWatchdogKernelError" 36 "a036_AudioWatchdogHfpError" 37 "a037_AudioWatchdogXrunStormError" 38 "a038_AudioWatchdogA2bI2cLockupError" 39 "a039_AudioA2bNeedRediscovery" 40 "a040_HomelinkTransmit" 41 "a041_AudioDmesgXrun" 42 "a042_AudioDmesgRtThrottling" 43 "a043_InvalidMapDataOverride" 44 "a044_AudioDmesgDspException" 45 "a045_ECallNeedsService" 46 "a046_BackupCameraStreamError" 47 "a047_CellRoamingDisallowed" 48 "a048_AudioPremiumAmpCheckFailed" 49 "a049_BrakeShiftRequired" 50 "a050_BackupCameraIPUTimeout" 51 "a051_BackupCameraFrameTimeout" 52 "a052_KernelPanicReported" 53 "a053_QtCarExitError" 54 "a054_AudioBoostPowerBad" 55 "a055_ManualECallDisabled" 56 "a056_ManualECallButtonDisconnected" 57 "a057_CellAntennaDisconnected" 58 "a058_GPSAntennaDisconnected" 59 "a059_ECallSpeakerDisconnected" 60 "a060_ECallMicDisconnected" 61 "a061_SIMTestFailed" 62 "a062_ENSTestFailed" 63 "a063_CellularTestFailed" 64 "a064_ModemFirmwareTestFailed" 65 "a065_WiFiRecoveryReset" 66 "a066_GpuHangDetected" 67 "a067_WarnOnI915" 68 "a068_VideoUnexpectedExit" 69 "a069_VideoUDPTimeout" 70 "a070_VideoPipelineWarning" 71 "a071_VideoPipelineError" 72 "a072_ECallAnalogMicFailed" 73 "a073_ECallDigitalMicFailed" 74 "a074_EMMCHangDetected" 75 "a075_BackupCameraInitError" 76 "a076_NumFalseManualECalls" 77 "a077_AudioA2bMicChannelSwap" 78 "a078_DashcamUsbDriveUnmountable" 79 "a079_DashcamUsbDriveFull" 80 "a080_DashcamUsbDriveSlow" 81 "a081_CellModemSearchExpired" 82 "a082_NumModemRebootStuckInECall" 83 "a083_ECallProxyWatchdogTriggered" 84 "a084_SerializerError" 85 "a085_DeserializerError" 86 "a086_TouchEnumerationError" 87 "a087_BmpReset" 88 "a088_CellRemovableSimMissing" 89 "a089_RadioSoftResetError" 90 "a090_RadioPingFailError" 91 "a091_VehicleLinkStall" 92 "a092_updateStarted" 93 "a093_updateEnded" 94 "a094_ModemPowerOnFailure" 95 "a095_CidStorageRunningLow" 96 "a096_VideodPipelineIssueDetected" 97 "a097_AudiodRestarted" 98 "a098_DiskCheckFailure" 99 "a099_eMMCStatusError" 100 "a100_eMMCFTLError" 101 "a101_wifiStackProblem" 102 "a102_A2bDiscoveryFailed" 103 "a103_UsbHubNotEnumerating" 104 "a104_DashcamUsbDriveMissing" 105 "a105_firmwareReinstallRequested" 106 "a106_rebootBackstopTriggered" 107 "a107_DashcamUsbDriveTooBigForVfatFsck" 108 "a108_DashcamUsbDriveGettingFull" 109 "a109_DashcamUsbDriveTooSmall" 110 "a110_DashcamUsbDriveCorrupt" 111 "a111_DashcamUsbDriveWrongPort" 112 "a112_badUSBDevice" 113 "a113_DashcamHasOnboardSentryClips" ;
CM_ BO_ 1327 "ESP32-DualCAN Model3_VEH. Seen on this car: 8-byte frames; fit ok (bits covered 100%, mux 100%, ranges 100%).";
